VERSION ""

NS_ :

BS_:

BU_: IVI

BO_ 32 ACU_A102: 8 Vector__XXX
  SG_ AirbagCrashOrder_v3 : 5|6@0+ (1,0) [0|0] "" IVI

BO_ 116 ECM_A110: 8 Vector__XXX
  SG_ PowerTrainSetPoint : 11|10@0+ (0.125,0) [0|125] "%" IVI
  SG_ RawSensor : 17|10@0+ (0.125,0) [0|125] "%" IVI
  SG_ StopAutoPhase : 47|3@0+ (1,0) [0|0] "" IVI

BO_ 117 ECM_A112: 8 Vector__XXX
  SG_ PowerTrainStatus : 25|2@0+ (1,0) [0|0] "" IVI
  SG_ EngineRPM : 39|16@0+ (0.125,0) [0|8191.75] "rpm" IVI
  SG_ MeanEffectiveTorque : 55|12@0+ (0.5,-400) [-400|1647] "Nm" IVI

BO_ 168 STRG_A1: 7 Vector__XXX
  SG_ SteeringWheelAngleRaw : 22|15@0+ (0.1,-1080) [-1080|1080] "°" IVI
  SG_ SwaSensorInternalStatus : 39|3@0+ (1,0) [0|0] "" IVI
  SG_ SteeringWheelRotationSpeed : 47|16@0+ (0.1,-3276.7) [-3276.7|3276.7] "°/s" IVI

BO_ 171 VDC_A6: 8 Vector__XXX
  SG_ YawRateCorrected : 10|11@0+ (0.1,-100) [-100|100] "°/s" IVI
  SG_ BrakingPressure : 31|8@0+ (0.5,0) [0|126] "bar" IVI
  SG_ SteeringWheelAngleCorrected : 39|15@0+ (0.1,-1080) [-1080|1080] "°" IVI

BO_ 180 VDC_A5: 8 Vector__XXX
  SG_ LongitudinalAccelCorrected : 23|12@0+ (0.001,-2) [-2|2] "G" IVI
  SG_ TransversalAccelCorrected : 47|12@0+ (0.001,-2) [-2|2] "G" IVI

BO_ 286 ATCU_A107: 3 Vector__XXX
  SG_ TorqueConverterState : 22|2@0+ (1,0) [0|0] "" IVI

BO_ 303 ATCU_A108: 7 Vector__XXX
  SG_ GearLeverPosition_v2 : 20|4@0+ (1,0) [0|0] "" IVI

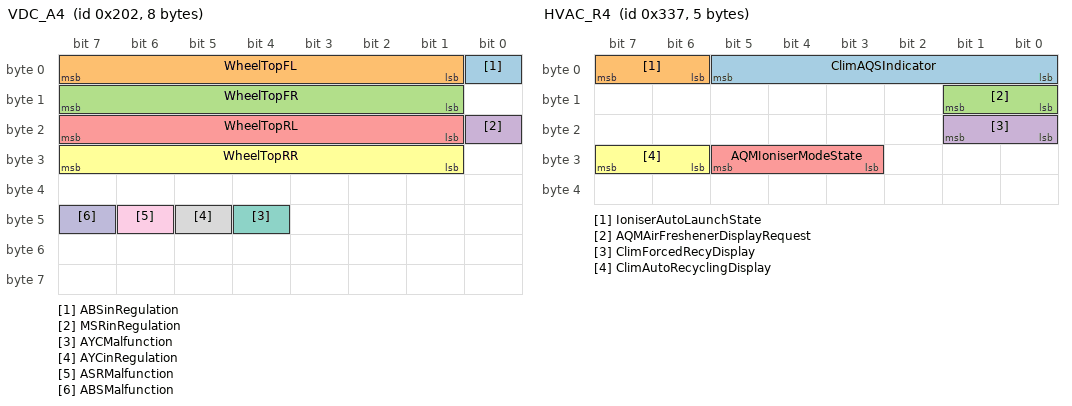
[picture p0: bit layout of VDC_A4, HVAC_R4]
BO_ 514 VDC_A4: 8 Vector__XXX
  SG_ ABSinRegulation : 0|1@0+ (1,0) [0|0] "" IVI
  SG_ WheelTopFL : 7|7@0+ (1,0) [0|96] "top" IVI
  SG_ WheelTopFR : 15|7@0+ (1,0) [0|96] "top" IVI
  SG_ MSRinRegulation : 16|1@0+ (1,0) [0|0] "" IVI
  SG_ WheelTopRL : 23|7@0+ (1,0) [0|96] "top" IVI
  SG_ WheelTopRR : 31|7@0+ (1,0) [0|96] "top" IVI
  SG_ AYCMalfunction : 44|1@0+ (1,0) [0|0] "" IVI
  SG_ AYCinRegulation : 45|1@0+ (1,0) [0|0] "" IVI
  SG_ ASRMalfunction : 46|1@0+ (1,0) [0|0] "" IVI
  SG_ ABSMalfunction : 47|1@0+ (1,0) [0|0] "" IVI

BO_ 534 EPS_A101: 4 Vector__XXX
  SG_ EPSWarning : 19|2@0+ (1,0) [0|0] "" IVI

BO_ 606 ADASISv2_A101: 8 IVI
  SG_ ADASISv2_ShortRang : 7|64@0+ (1,0) [0|0] "" Vector__XXX

BO_ 649 VDC_A3: 8 Vector__XXX
  SG_ WheelSpeedRL : 23|16@0+ (0.0416666667,0) [0|2730.583333] "rpm" IVI
  SG_ WheelSpeedRR : 39|16@0+ (0.0416666667,0) [0|2730.583333] "rpm" IVI
  SG_ VehicleSpeedBody : 55|16@0+ (0.01,0) [0|655.34] "km/h" IVI

BO_ 650 VDC_A9: 8 Vector__XXX
  SG_ WheelSpeedFR : 7|16@0+ (0.0416666667,0) [0|2730.583333] "rpm" IVI
  SG_ WheelSpeedFL : 23|16@0+ (0.0416666667,0) [0|2730.583333] "rpm" IVI
  SG_ VehicleSpeed : 39|16@0+ (0.01,0) [0|655.34] "km/h" IVI

BO_ 791 HVAC_A1: 8 Vector__XXX
  SG_ ISS_EcoActivationState : 43|2@0+ (1,0) [0|0] "" IVI
  SG_ AirCondEcoActivationState : 45|2@0+ (1,0) [0|0] "" IVI
  SG_ ClimECOModeStatusDisplay : 52|2@0+ (1,0) [0|0] "" IVI

BO_ 823 HVAC_R4: 5 Vector__XXX
  SG_ ClimAQSIndicator : 5|6@0+ (2,0) [0|100] "%" IVI
  SG_ IoniserAutoLaunchState : 7|2@0+ (1,0) [0|0] "" IVI
  SG_ AQMAirFreshenerDisplayRequest : 9|2@0+ (1,0) [0|0] "" IVI
  SG_ ClimForcedRecyDisplay : 17|2@0+ (1,0) [0|0] "" IVI
  SG_ AQMIoniserModeState : 29|3@0+ (1,0) [0|0] "" IVI
  SG_ ClimAutoRecyclingDisplay : 31|2@0+ (1,0) [0|0] "" IVI

BO_ 893 EPS_A103: 3 Vector__XXX
  SG_ LDW_VibrationIntensityState : 2|2@0+ (1,0) [0|0] "" IVI
  SG_ LCA_SteeringStatus2 : 7|2@0+ (1,0) [0|0] "" IVI

BO_ 928 ADASISv2_A102: 8 IVI
  SG_ ADASISv2_LongRang : 7|64@0+ (1,0) [0|0] "" Vector__XXX

BO_ 929 ADASISv2_A104: 8 IVI
  SG_ ADASISv2_SEGMENT : 7|64@0+ (1,0) [0|0] "" Vector__XXX

BO_ 931 ADASISv2_A105: 8 IVI
  SG_ ADASISv2_STUB : 7|64@0+ (1,0) [0|0] "" Vector__XXX

BO_ 934 AVM_A120: 3 Vector__XXX
  SG_ APA_StatusDisplay2 : 11|2@0+ (1,0) [0|0] "" IVI

BO_ 955 ECM_R102: 2 Vector__XXX
  SG_ RST_Boost_Duration_MMI : 7|8@0+ (1,0) [0|240] "s" IVI
  SG_ RST_Boost_Activation_MMI : 15|2@0+ (1,0) [0|0] "" IVI

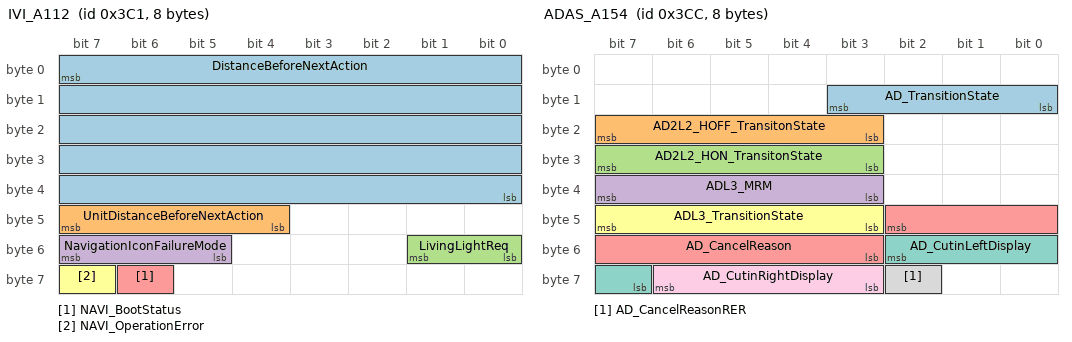
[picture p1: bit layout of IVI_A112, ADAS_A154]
BO_ 961 IVI_A112: 8 IVI
  SG_ DistanceBeforeNextAction : 7|40@0+ (1,0) [0|0] "" Vector__XXX
  SG_ UnitDistanceBeforeNextAction : 47|4@0+ (1,0) [0|0] "" Vector__XXX
  SG_ LivingLightReq : 49|2@0+ (1,0) [0|0] "" Vector__XXX
  SG_ NavigationIconFailureMode : 55|3@0+ (1,0) [0|0] "" Vector__XXX
  SG_ NAVI_BootStatus : 62|1@0+ (1,0) [0|0] "" Vector__XXX
  SG_ NAVI_OperationError : 63|1@0+ (1,0) [0|0] "" Vector__XXX

BO_ 962 SONAR_A118: 3 Vector__XXX
  SG_ APA_StatusDisplay : 11|2@0+ (1,0) [0|0] "" IVI

BO_ 967 IVI_A5: 8 IVI
  SG_ CDisplayAvailability : 1|2@0+ (1,0) [0|0] "" Vector__XXX
  SG_ AutoACC2_ON_Request_MM : 3|2@0+ (1,0) [0|0] "" Vector__XXX
  SG_ Audio_WorkingAuthorize : 5|2@0+ (1,0) [0|0] "" Vector__XXX
  SG_ IVI_RefusetoSleep : 7|2@0+ (1,0) [0|0] "" Vector__XXX
  SG_ SonarSystemPauseRequest2 : 8|1@0+ (1,0) [0|0] "" Vector__XXX
  SG_ IVI_InitializationState : 9|1@0+ (1,0) [0|0] "" Vector__XXX
  SG_ MMCustomerAction : 12|3@0+ (1,0) [0|6] "" Vector__XXX
  SG_ UserFeedbackAvailability : 13|1@0+ (1,0) [0|0] "" Vector__XXX
  SG_ AudioAvailability : 14|1@0+ (1,0) [0|0] "" Vector__XXX
  SG_ SwitchRequest_AVM : 16|1@0+ (1,0) [0|0] "" Vector__XXX
  SG_ ChangeViewRequest_AVM : 18|2@0+ (1,0) [0|0] "" Vector__XXX
  SG_ Audio_ProcessingDeactivation : 24|1@0+ (1,0) [0|0] "" Vector__XXX
  SG_ VehicleGPSreliability : 31|7@0+ (1,0) [0|127] "" Vector__XXX
  SG_ PassengerHeatingRequest : 33|2@0+ (1,0) [0|0] "" Vector__XXX
  SG_ PassengerVentilRequest : 35|2@0+ (1,0) [0|0] "" Vector__XXX
  SG_ DriverHeatingRequest : 37|2@0+ (1,0) [0|0] "" Vector__XXX
  SG_ DriverVentilRequest : 39|2@0+ (1,0) [0|0] "" Vector__XXX
  SG_ StorageFormatRequest : 42|2@0+ (1,0) [0|0] "" Vector__XXX
  SG_ TPMS_ResetDriverRequest2 : 44|2@0+ (1,0) [0|0] "" Vector__XXX
  SG_ TPW_ResetDriverRequest2 : 47|2@0+ (1,0) [0|0] "" Vector__XXX
  SG_ SatelliteGPSNumber : 55|7@0+ (1,0) [0|126] "wu" Vector__XXX
  SG_ EcoPedalForceSettingRequest : 58|2@0+ (1,0) [0|0] "" Vector__XXX
  SG_ HUD_UpDownRequest2 : 60|2@0+ (1,0) [0|0] "" Vector__XXX
  SG_ IVI_ParkAssistVolumeState : 63|3@0+ (1,0) [0|0] "" Vector__XXX

BO_ 969 HEVC_M101: 1 Vector__XXX
  SG_ TorqueDistributionRatioDisplay : 7|8@0+ (0.5,0) [0|100] "%" IVI

BO_ 970 BLM_A101: 1 Vector__XXX
  SG_ VirtualKeyActivationState : 3|1@0+ (1,0) [0|0] "" IVI
  SG_ VirtualKeyState : 4|1@0+ (1,0) [0|0] "" IVI

BO_ 972 ADAS_A154: 8 Vector__XXX
  SG_ AD_TransitionState : 11|4@0+ (1,0) [0|0] "" IVI
  SG_ AD2L2_HOFF_TransitonState : 23|5@0+ (1,0) [0|0] "" IVI
  SG_ AD2L2_HON_TransitonState : 31|5@0+ (1,0) [0|0] "" IVI
  SG_ ADL3_MRM : 39|5@0+ (1,0) [0|0] "" IVI
  SG_ AD_CancelReason : 42|8@0+ (1,0) [0|255] "CancelReason" IVI
  SG_ ADL3_TransitionState : 47|5@0+ (1,0) [0|0] "" IVI
  SG_ AD_CutinLeftDisplay : 50|4@0+ (1,0) [0|0] "" IVI
  SG_ AD_CancelReasonRER : 58|1@0+ (1,0) [0|0] "" IVI
  SG_ AD_CutinRightDisplay : 62|4@0+ (1,0) [0|0] "" IVI

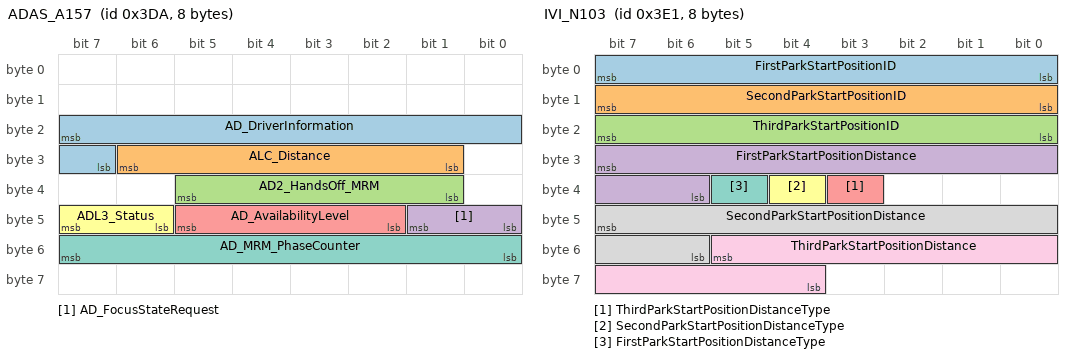
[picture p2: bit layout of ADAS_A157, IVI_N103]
BO_ 986 ADAS_A157: 8 Vector__XXX
  SG_ AD_DriverInformation : 23|9@0+ (1,0) [0|511] "Instruction" IVI
  SG_ ALC_Distance : 30|6@0+ (100,100) [100|6000] "m" IVI
  SG_ AD2_HandsOff_MRM : 37|5@0+ (1,0) [0|0] "" IVI
  SG_ AD_FocusStateRequest : 41|2@0+ (1,0) [0|0] "" IVI
  SG_ AD_AvailabilityLevel : 45|4@0+ (1,0) [0|0] "" IVI
  SG_ ADL3_Status : 47|2@0+ (1,0) [0|0] "" IVI
  SG_ AD_MRM_PhaseCounter : 55|8@0+ (0.2,-0.2) [0|50.6] "s" IVI

BO_ 993 IVI_N103: 8 IVI
  SG_ FirstParkStartPositionID : 7|8@0+ (1,0) [0|255] "-" Vector__XXX
  SG_ SecondParkStartPositionID : 15|8@0+ (1,0) [0|255] "-" Vector__XXX
  SG_ ThirdParkStartPositionID : 23|8@0+ (1,0) [0|255] "-" Vector__XXX
  SG_ FirstParkStartPositionDistance : 31|10@0+ (1,0) [0|1023] "m" Vector__XXX
  SG_ ThirdParkStartPositionDistanceType : 35|1@0+ (1,0) [0|0] "-" Vector__XXX
  SG_ SecondParkStartPositionDistanceType : 36|1@0+ (1,0) [0|0] "-" Vector__XXX
  SG_ FirstParkStartPositionDistanceType : 37|1@0+ (1,0) [0|0] "-" Vector__XXX
  SG_ SecondParkStartPositionDistance : 47|10@0+ (1,0) [0|1023] "m" Vector__XXX
  SG_ ThirdParkStartPositionDistance : 53|10@0+ (1,0) [0|1023] "m" Vector__XXX

BO_ 994 FWS_A102: 1 Vector__XXX
  SG_ a4WS_AnglePosition_v2 : 7|7@0+ (0.1,-5) [-5|5] "deg" IVI

BO_ 996 DSMU_A101: 3 Vector__XXX
  SG_ DriverMassageProgramState_v2 : 23|3@0+ (1,0) [0|0] "" IVI

BO_ 1000 HFM_A101: 4 Vector__XXX
  SG_ APPRUN_ActivationState : 12|1@0+ (1,0) [0|0] "" IVI
  SG_ WAL_ActivationState : 13|1@0+ (1,0) [0|0] "" IVI
  SG_ IKeyAccessActivationState : 18|1@0+ (1,0) [0|0] "" IVI

BO_ 1001 PSCU_A102: 1 Vector__XXX
  SG_ PassengerMassageProgramState_v2 : 6|3@0+ (1,0) [0|0] "" IVI

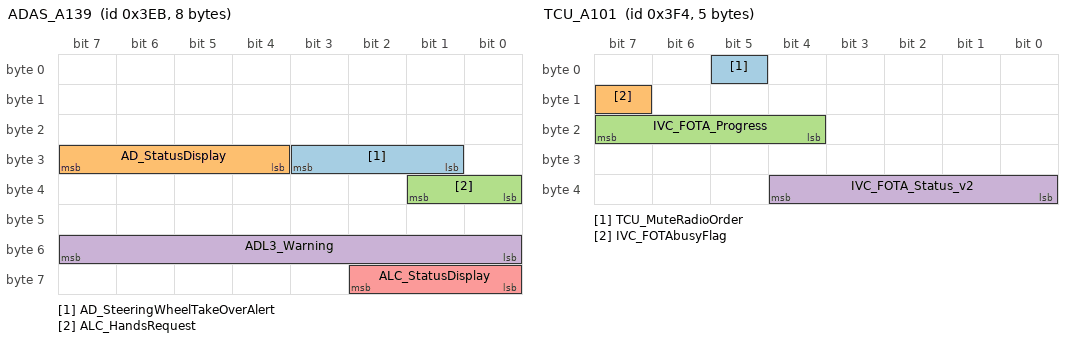
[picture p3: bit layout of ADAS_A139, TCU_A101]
BO_ 1003 ADAS_A139: 8 Vector__XXX
  SG_ AD_SteeringWheelTakeOverAlert : 27|3@0+ (1,0) [0|0] "" IVI
  SG_ AD_StatusDisplay : 31|4@0+ (1,0) [0|0] "" IVI
  SG_ ALC_HandsRequest : 33|2@0+ (1,0) [0|0] "" IVI
  SG_ ADL3_Warning : 55|8@0+ (1,0) [0|255] "Warning" IVI
  SG_ ALC_StatusDisplay : 58|3@0+ (1,0) [0|0] "" IVI

BO_ 1012 TCU_A101: 5 Vector__XXX
  SG_ TCU_MuteRadioOrder : 5|1@0+ (1,0) [0|0] "" IVI
  SG_ IVC_FOTAbusyFlag : 15|1@0+ (1,0) [0|0] "" IVI
  SG_ IVC_FOTA_Progress : 23|4@0+ (10,0) [0|100] "%" IVI
  SG_ IVC_FOTA_Status_v2 : 36|5@0+ (1,0) [0|0] "" IVI

BO_ 1017 UTA_R1: 2 Vector__XXX
  SG_ UTA_VigilanceLevelDisplay : 5|4@0+ (1,0) [0|0] "" IVI
  SG_ UTA_AlertActivationState : 6|1@0+ (1,0) [0|0] "" IVI
  SG_ UTA_VigilanceAlertDisplay_v2 : 15|2@0+ (1,0) [0|0] "" IVI

BO_ 1028 VSP_A101: 1 Vector__XXX
  SG_ VSPSoundActivationState : 4|1@0+ (1,0) [0|0] "" IVI
  SG_ VSPsoundChoiceActivationState : 7|3@0+ (1,0) [0|0] "" IVI

BO_ 1047 AVM_A119: 3 Vector__XXX
  SG_ AVM_WarningDisplayRequest : 7|3@0+ (1,0) [0|0] "" IVI
  SG_ HFP_ManeuverCompletion2 : 15|7@0+ (1,0) [0|100] "%" IVI
  SG_ HFP_ExtendedInstrContentDisplay2 : 23|5@0+ (1,0) [0|0] "" IVI

BO_ 1058 FRCAMERA_A111: 5 Vector__XXX
  SG_ OSPSpeedUnit : 19|2@0+ (1,0) [0|0] "" IVI
  SG_ TSR_ConfidenceLevel : 39|3@0+ (20,0) [0|100] "%" IVI

BO_ 1064 HEVC_A104: 7 Vector__XXX
  SG_ EcoNavFuelSaving : 0|10@0+ (0.01,0) [0|10] "L" IVI
  SG_ VehicleAutonomyZEV : 22|10@0+ (1,0) [0|1022] "km" IVI

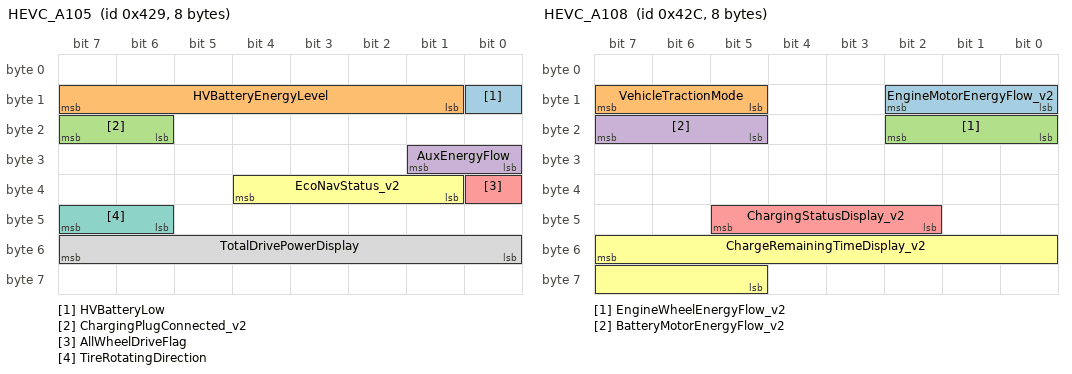
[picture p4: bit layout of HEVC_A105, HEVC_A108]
BO_ 1065 HEVC_A105: 8 Vector__XXX
  SG_ HVBatteryLow : 8|1@0+ (1,0) [0|0] "" IVI
  SG_ HVBatteryEnergyLevel : 15|7@0+ (1,0) [0|100] "%" IVI
  SG_ ChargingPlugConnected_v2 : 23|2@0+ (1,0) [0|0] "" IVI
  SG_ AuxEnergyFlow : 25|2@0+ (1,0) [0|0] "" IVI
  SG_ AllWheelDriveFlag : 32|1@0+ (1,0) [0|0] "" IVI
  SG_ EcoNavStatus_v2 : 36|4@0+ (1,0) [0|0] "" IVI
  SG_ TireRotatingDirection : 47|2@0+ (1,0) [0|0] "" IVI
  SG_ TotalDrivePowerDisplay : 55|8@0+ (1,-100) [-100|120] "%" IVI

BO_ 1066 HEVC_A106: 8 Vector__XXX
  SG_ HVbatteryChargeType_v2 : 50|3@0+ (1,0) [0|0] "" IVI

BO_ 1068 HEVC_A108: 8 Vector__XXX
  SG_ EngineMotorEnergyFlow_v2 : 10|3@0+ (1,0) [0|0] "" IVI
  SG_ VehicleTractionMode : 15|3@0+ (1,0) [0|0] "" IVI
  SG_ EngineWheelEnergyFlow_v2 : 18|3@0+ (1,0) [0|0] "" IVI
  SG_ BatteryMotorEnergyFlow_v2 : 23|3@0+ (1,0) [0|0] "" IVI
  SG_ ChargingStatusDisplay_v2 : 45|4@0+ (1,0) [0|0] "" IVI
  SG_ ChargeRemainingTimeDisplay_v2 : 55|11@0+ (1,0) [0|2046] "min" IVI

BO_ 1070 HEVC_R101: 7 Vector__XXX
  SG_ UserSOC : 7|8@0+ (0.392157,0) [0|100] "%" IVI

BO_ 1071 HEVC_R103: 3 Vector__XXX
  SG_ HVBatteryEnergyCap_Reachability : 7|11@0+ (0.05,0) [0|100] "kWh" IVI
  SG_ AvailableEnergy_HEVC : 12|11@0+ (0.05,0) [0|100] "kWh" IVI

BO_ 1076 HFM_A104: 8 Vector__XXX
  SG_ WAC_APRUN_ActivationState : 49|1@0+ (1,0) [0|0] "" IVI
  SG_ SwitchOffSESDisturbers : 50|1@0+ (1,0) [0|0] "" IVI

BO_ 1081 VDC_A114: 6 Vector__XXX
  SG_ SlopeEstimation : 7|8@0+ (0.2,-15) [-15|15] "°" IVI
  SG_ DistanceTotalizer : 15|28@0+ (0.01,0) [0|2600000] "km" IVI
  SG_ TCS_DeactivationState : 32|1@0+ (1,0) [0|0] "" IVI

BO_ 1086 HVAC_A2: 8 Vector__XXX
  SG_ InputPower_AC_INV : 15|7@0+ (50,0) [0|5100] "W" IVI
  SG_ ePTCpower : 23|6@0+ (250,0) [0|10000] "W" IVI

BO_ 1099 ATCU_A109: 8 Vector__XXX
  SG_ ATCVT_RangeIndicationExtended : 44|6@0+ (1,0) [0|0] "" IVI

BO_ 1100 ATCU_A110: 6 Vector__XXX
  SG_ RST_LaunchControlReady : 11|2@0+ (1,0) [0|0] "" IVI

BO_ 1101 BCM_A107: 4 Vector__XXX
  SG_ FlashingIndicatorStatusDisplay : 23|3@0+ (1,0) [0|0] "" IVI

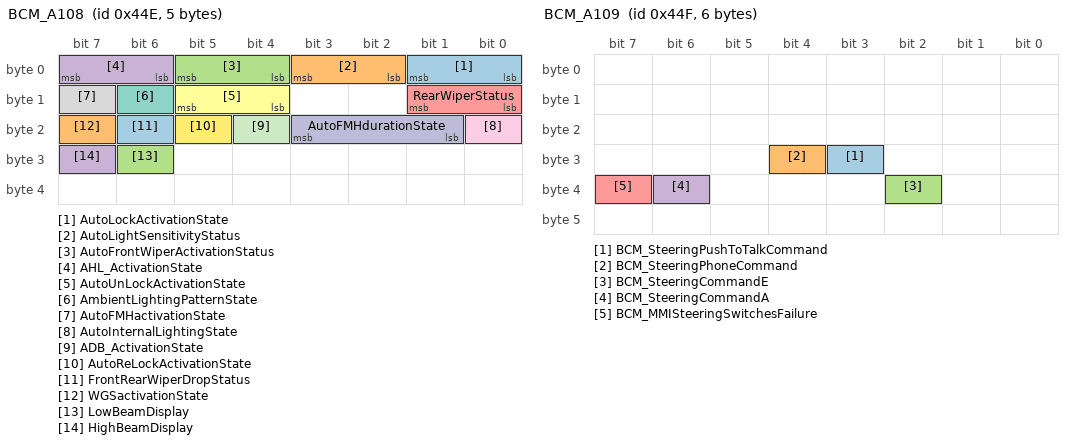
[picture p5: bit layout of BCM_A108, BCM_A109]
BO_ 1102 BCM_A108: 5 Vector__XXX
  SG_ AutoLockActivationState : 1|2@0+ (1,0) [0|0] "" IVI
  SG_ AutoLightSensitivityStatus : 3|2@0+ (1,0) [0|0] "" IVI
  SG_ AutoFrontWiperActivationStatus : 5|2@0+ (1,0) [0|0] "" IVI
  SG_ AHL_ActivationState : 7|2@0+ (1,0) [0|0] "" IVI
  SG_ RearWiperStatus : 9|2@0+ (1,0) [0|0] "" IVI
  SG_ AutoUnLockActivationState : 13|2@0+ (1,0) [0|0] "" IVI
  SG_ AmbientLightingPatternState : 14|1@0+ (1,0) [0|0] "" IVI
  SG_ AutoFMHactivationState : 15|1@0+ (1,0) [0|0] "" IVI
  SG_ AutoInternalLightingState : 16|1@0+ (1,0) [0|0] "" IVI
  SG_ AutoFMHdurationState : 19|3@0+ (1,0) [0|0] "" IVI
  SG_ ADB_ActivationState : 20|1@0+ (1,0) [0|0] "" IVI
  SG_ AutoReLockActivationState : 21|1@0+ (1,0) [0|0] "" IVI
  SG_ FrontRearWiperDropStatus : 22|1@0+ (1,0) [0|0] "" IVI
  SG_ WGSactivationState : 23|1@0+ (1,0) [0|0] "" IVI
  SG_ LowBeamDisplay : 30|1@0+ (1,0) [0|0] "" IVI
  SG_ HighBeamDisplay : 31|1@0+ (1,0) [0|0] "" IVI

BO_ 1103 BCM_A109: 6 Vector__XXX
  SG_ BCM_SteeringPushToTalkCommand : 27|1@0+ (1,0) [0|0] "" IVI
  SG_ BCM_SteeringPhoneCommand : 28|1@0+ (1,0) [0|0] "" IVI
  SG_ BCM_SteeringCommandE : 34|1@0+ (1,0) [0|0] "" IVI
  SG_ BCM_SteeringCommandA : 38|1@0+ (1,0) [0|0] "" IVI
  SG_ BCM_MMISteeringSwitchesFailure : 39|1@0+ (1,0) [0|0] "" IVI

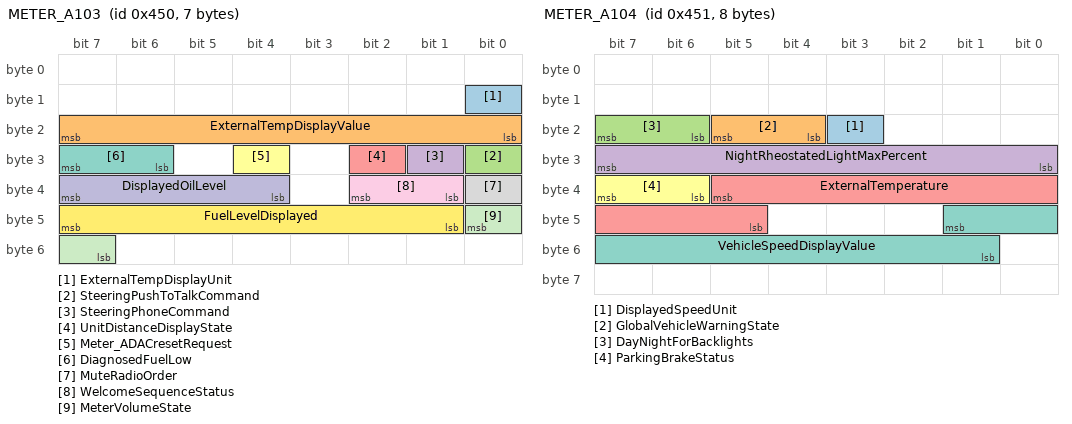
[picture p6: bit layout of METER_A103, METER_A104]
BO_ 1104 METER_A103: 7 Vector__XXX
  SG_ ExternalTempDisplayUnit : 8|1@0+ (1,0) [0|0] "" IVI
  SG_ ExternalTempDisplayValue : 23|8@0+ (1,-40) [-40|140] "" IVI
  SG_ SteeringPushToTalkCommand : 24|1@0+ (1,0) [0|0] "" IVI
  SG_ SteeringPhoneCommand : 25|1@0+ (1,0) [0|0] "" IVI
  SG_ UnitDistanceDisplayState : 26|1@0+ (1,0) [0|0] "" IVI
  SG_ Meter_ADACresetRequest : 28|1@0+ (1,0) [0|0] "" IVI
  SG_ DiagnosedFuelLow : 31|2@0+ (1,0) [0|0] "" IVI
  SG_ MuteRadioOrder : 32|1@0+ (1,0) [0|0] "" IVI
  SG_ WelcomeSequenceStatus : 34|2@0+ (1,0) [0|0] "" IVI
  SG_ DisplayedOilLevel : 39|4@0+ (1,0) [0|0] "" IVI
  SG_ MeterVolumeState : 40|2@0+ (1,0) [0|0] "" IVI
  SG_ FuelLevelDisplayed : 47|7@0+ (1,0) [0|80] "L" IVI

BO_ 1105 METER_A104: 8 Vector__XXX
  SG_ DisplayedSpeedUnit : 19|1@0+ (1,0) [0|0] "" IVI
  SG_ GlobalVehicleWarningState : 21|2@0+ (1,0) [0|0] "" IVI
  SG_ DayNightForBacklights : 23|2@0+ (1,0) [0|0] "" IVI
  SG_ NightRheostatedLightMaxPercent : 31|8@0+ (0.4,0) [0|100] "%" IVI
  SG_ ExternalTemperature : 37|9@0+ (0.25,-50) [-50|70] "°C" IVI
  SG_ ParkingBrakeStatus : 39|2@0+ (1,0) [0|0] "" IVI
  SG_ VehicleSpeedDisplayValue : 41|9@0+ (1,0) [0|510] "" IVI

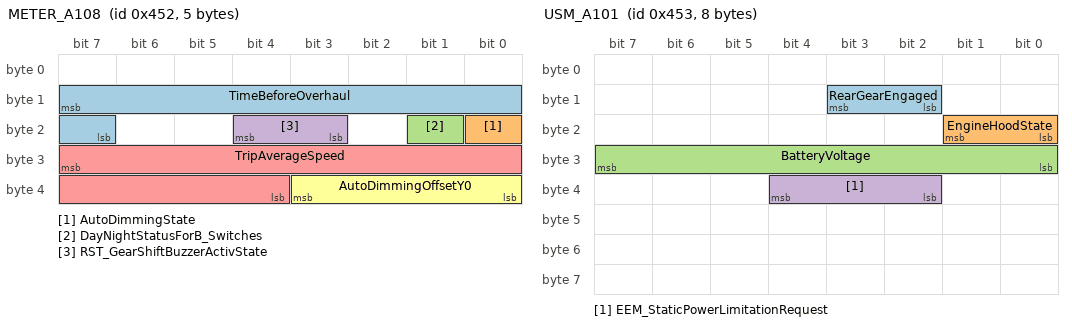
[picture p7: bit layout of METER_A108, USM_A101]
BO_ 1106 METER_A108: 5 Vector__XXX
  SG_ TimeBeforeOverhaul : 15|9@0+ (1,0) [0|511] "day" IVI
  SG_ AutoDimmingState : 16|1@0+ (1,0) [0|0] "" IVI
  SG_ DayNightStatusForB_Switches : 17|1@0+ (1,0) [0|0] "" IVI
  SG_ RST_GearShiftBuzzerActivState : 20|2@0+ (1,0) [0|0] "" IVI
  SG_ TripAverageSpeed : 31|12@0+ (0.1,0) [0|409.5] "" IVI
  SG_ AutoDimmingOffsetY0 : 35|4@0+ (1,0) [0|0] "" IVI

BO_ 1107 USM_A101: 8 Vector__XXX
  SG_ RearGearEngaged : 11|2@0+ (1,0) [0|0] "" IVI
  SG_ EngineHoodState : 17|2@0+ (1,0) [0|0] "" IVI
  SG_ BatteryVoltage : 31|8@0+ (0.06,6) [6|18] "V" IVI
  SG_ EEM_StaticPowerLimitationRequest : 36|3@0+ (1,0) [0|0] "" IVI

BO_ 1108 USM_A103: 8 Vector__XXX
  SG_ HandDrivingActivationState : 0|1@0+ (1,0) [0|0] "" IVI
  SG_ LowBatteryVoltageDisplay : 15|2@0+ (1,0) [0|0] "" IVI
  SG_ AFS_ActivationState : 16|1@0+ (1,0) [0|0] "" IVI

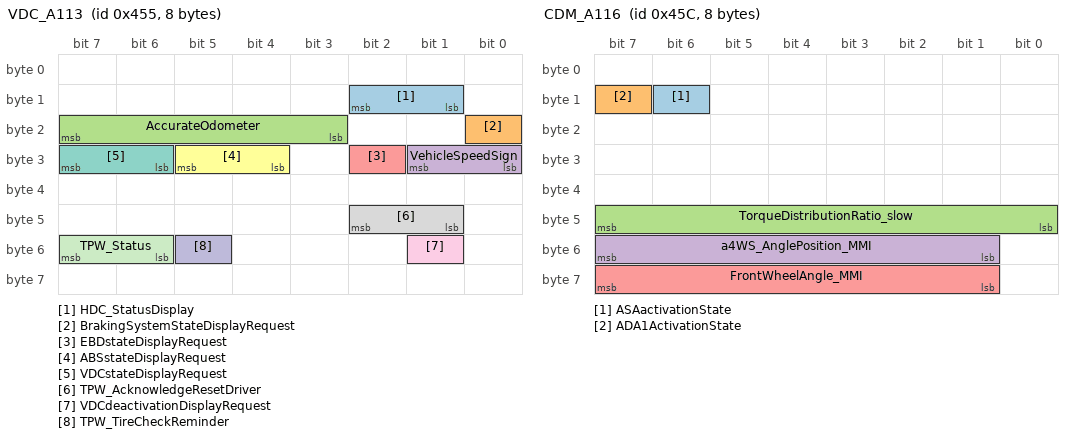
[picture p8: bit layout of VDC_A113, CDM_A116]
BO_ 1109 VDC_A113: 8 Vector__XXX
  SG_ HDC_StatusDisplay : 10|2@0+ (1,0) [0|0] "" IVI
  SG_ BrakingSystemStateDisplayRequest : 16|1@0+ (1,0) [0|0] "" IVI
  SG_ AccurateOdometer : 23|5@0+ (4,0) [0|120] "cm" IVI
  SG_ VehicleSpeedSign : 25|2@0+ (1,0) [0|0] "" IVI
  SG_ EBDstateDisplayRequest : 26|1@0+ (1,0) [0|0] "" IVI
  SG_ ABSstateDisplayRequest : 29|2@0+ (1,0) [0|0] "" IVI
  SG_ VDCstateDisplayRequest : 31|2@0+ (1,0) [0|0] "" IVI
  SG_ TPW_AcknowledgeResetDriver : 42|2@0+ (1,0) [0|0] "" IVI
  SG_ VDCdeactivationDisplayRequest : 49|1@0+ (1,0) [0|0] "" IVI
  SG_ TPW_TireCheckReminder : 53|1@0+ (1,0) [0|0] "" IVI
  SG_ TPW_Status : 55|2@0+ (1,0) [0|0] "" IVI

BO_ 1116 CDM_A116: 8 Vector__XXX
  SG_ ASAactivationState : 14|1@0+ (1,0) [0|0] "" IVI
  SG_ ADA1ActivationState : 15|1@0+ (1,0) [0|0] "" IVI
  SG_ TorqueDistributionRatio_slow : 47|8@0+ (0.5,0) [0|100] "%" IVI
  SG_ a4WS_AnglePosition_MMI : 55|7@0+ (0.1,-5) [-5|5] "deg" IVI
  SG_ FrontWheelAngle_MMI : 63|7@0+ (1,-50) [-50|50] "°" IVI

BO_ 1119 ECM_A108: 4 Vector__XXX
  SG_ EngineCoolantTemp : 23|8@0+ (1,-40) [-40|214] "°C" IVI

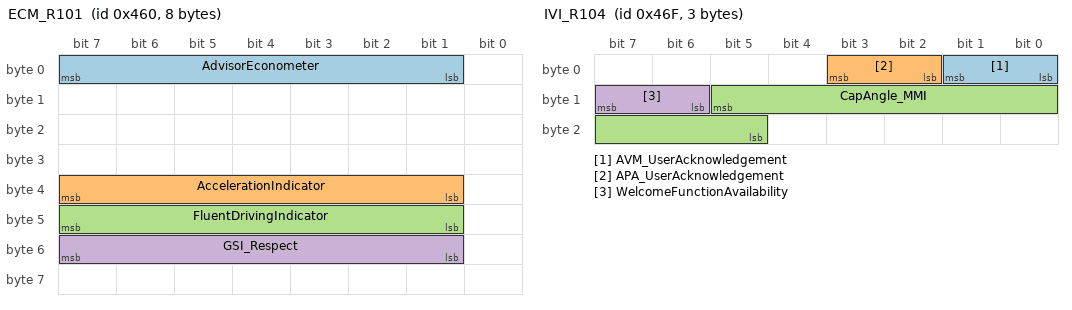
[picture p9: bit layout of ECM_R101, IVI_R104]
BO_ 1120 ECM_R101: 8 Vector__XXX
  SG_ AdvisorEconometer : 7|7@0+ (1,0) [0|127] "%" IVI
  SG_ AccelerationIndicator : 39|7@0+ (1,0) [0|127] "%" IVI
  SG_ FluentDrivingIndicator : 47|7@0+ (1,0) [0|127] "%" IVI
  SG_ GSI_Respect : 55|7@0+ (1,0) [0|127] "%" IVI

BO_ 1135 IVI_R104: 3 IVI
  SG_ AVM_UserAcknowledgement : 1|2@0+ (1,0) [0|0] "" Vector__XXX
  SG_ APA_UserAcknowledgement : 3|2@0+ (1,0) [0|0] "" Vector__XXX
  SG_ CapAngle_MMI : 13|9@0+ (1,0) [0|360] "°" Vector__XXX
  SG_ WelcomeFunctionAvailability : 15|2@0+ (1,0) [0|0] "" Vector__XXX

BO_ 1136 ECM_A107: 7 Vector__XXX
  SG_ EngineControlFailureLevel2 : 11|1@0+ (1,0) [0|0] "" IVI
  SG_ EngineControlFailureLevel1 : 32|1@0+ (1,0) [0|0] "" IVI

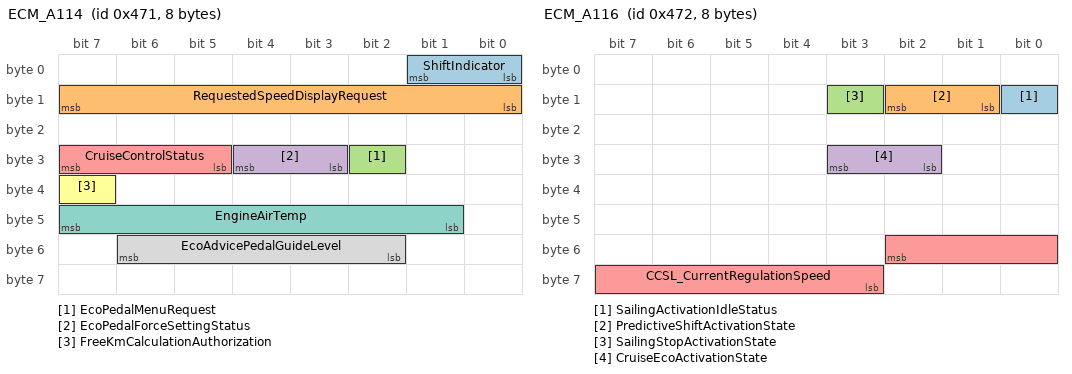
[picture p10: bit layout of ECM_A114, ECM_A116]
BO_ 1137 ECM_A114: 8 Vector__XXX
  SG_ ShiftIndicator : 1|2@0+ (1,0) [0|0] "" IVI
  SG_ RequestedSpeedDisplayRequest : 15|8@0+ (1,0) [0|253] "" IVI
  SG_ EcoPedalMenuRequest : 26|1@0+ (1,0) [0|0] "" IVI
  SG_ EcoPedalForceSettingStatus : 28|2@0+ (1,0) [0|0] "" IVI
  SG_ CruiseControlStatus : 31|3@0+ (1,0) [0|0] "" IVI
  SG_ FreeKmCalculationAuthorization : 39|1@0+ (1,0) [0|0] "" IVI
  SG_ EngineAirTemp : 47|7@0+ (1,-40) [-40|86] "°C" IVI
  SG_ EcoAdvicePedalGuideLevel : 54|5@0+ (1,0) [0|30] "wu" IVI

BO_ 1138 ECM_A116: 8 Vector__XXX
  SG_ SailingActivationIdleStatus : 8|1@0+ (1,0) [0|0] "" IVI
  SG_ PredictiveShiftActivationState : 10|2@0+ (1,0) [0|0] "" IVI
  SG_ SailingStopActivationState : 11|1@0+ (1,0) [0|0] "" IVI
  SG_ CruiseEcoActivationState : 27|2@0+ (1,0) [0|0] "" IVI
  SG_ CCSL_CurrentRegulationSpeed : 50|8@0+ (1,0) [0|200] "Cluster speed unit" IVI

BO_ 1140 ADAS_A116: 8 Vector__XXX
  SG_ LKA_AlertStatus : 9|2@0+ (1,0) [0|0] "" IVI
  SG_ LKA_ActivationState : 20|2@0+ (1,0) [0|0] "" IVI
  SG_ LKA_SWheelTakeOverAlert_v3 : 23|3@0+ (1,0) [0|0] "" IVI

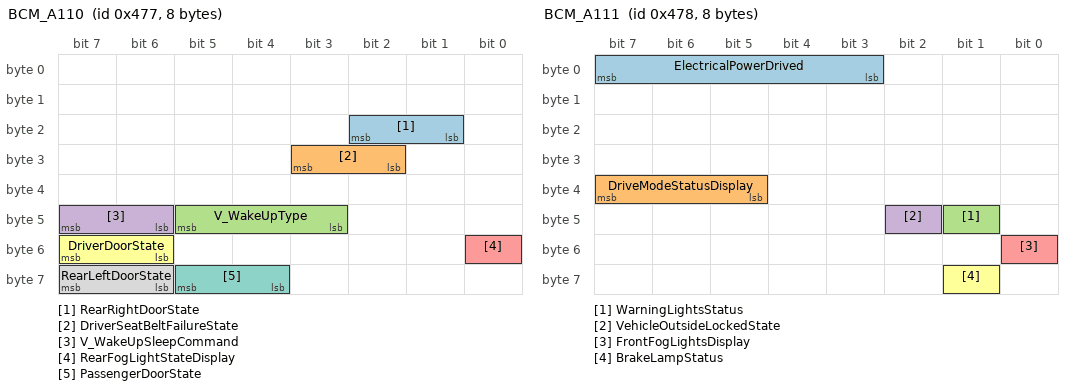
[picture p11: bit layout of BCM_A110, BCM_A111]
BO_ 1143 BCM_A110: 8 Vector__XXX
  SG_ RearRightDoorState : 18|2@0+ (1,0) [0|0] "" IVI
  SG_ DriverSeatBeltFailureState : 27|2@0+ (1,0) [0|0] "" IVI
  SG_ V_WakeUpType : 45|3@0+ (1,0) [0|0] "" IVI
  SG_ V_WakeUpSleepCommand : 47|2@0+ (1,0) [0|0] "" IVI
  SG_ RearFogLightStateDisplay : 48|1@0+ (1,0) [0|0] "" IVI
  SG_ DriverDoorState : 55|2@0+ (1,0) [0|0] "" IVI
  SG_ PassengerDoorState : 61|2@0+ (1,0) [0|0] "" IVI
  SG_ RearLeftDoorState : 63|2@0+ (1,0) [0|0] "" IVI

BO_ 1144 BCM_A111: 8 Vector__XXX
  SG_ ElectricalPowerDrived : 7|5@0+ (100,0) [0|3000] "W" IVI
  SG_ DriveModeStatusDisplay : 39|3@0+ (1,0) [0|0] "" IVI
  SG_ WarningLightsStatus : 41|1@0+ (1,0) [0|0] "" IVI
  SG_ VehicleOutsideLockedState : 42|1@0+ (1,0) [0|0] "" IVI
  SG_ FrontFogLightsDisplay : 48|1@0+ (1,0) [0|0] "" IVI
  SG_ BrakeLampStatus : 57|1@0+ (1,0) [0|0] "" IVI

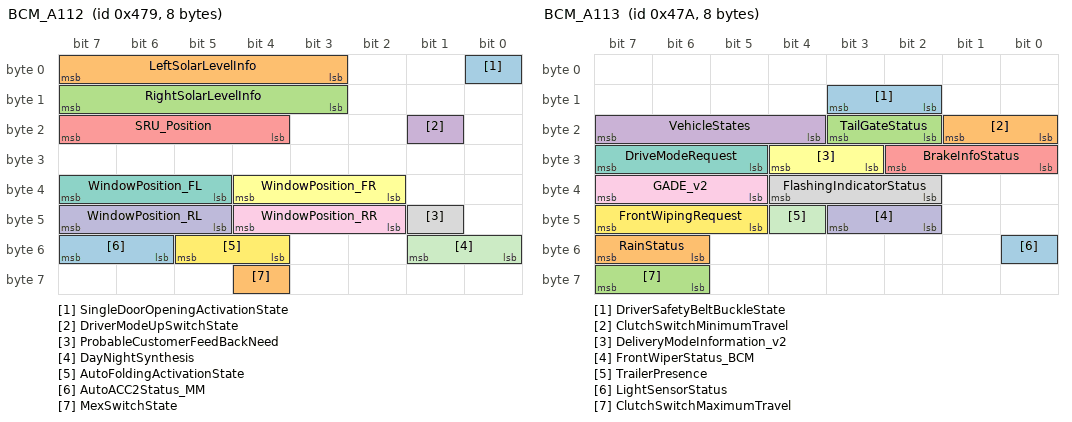
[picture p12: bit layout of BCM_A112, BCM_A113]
BO_ 1145 BCM_A112: 8 Vector__XXX
  SG_ SingleDoorOpeningActivationState : 0|1@0+ (1,0) [0|0] "" IVI
  SG_ LeftSolarLevelInfo : 7|5@0+ (50,0) [0|1500] "W" IVI
  SG_ RightSolarLevelInfo : 15|5@0+ (50,0) [0|1500] "W" IVI
  SG_ DriverModeUpSwitchState : 17|1@0+ (1,0) [0|0] "" IVI
  SG_ SRU_Position : 23|4@0+ (1,0) [0|0] "" IVI
  SG_ WindowPosition_FR : 36|3@0+ (1,0) [0|0] "" IVI
  SG_ WindowPosition_FL : 39|3@0+ (1,0) [0|0] "" IVI
  SG_ ProbableCustomerFeedBackNeed : 41|1@0+ (1,0) [0|0] "" IVI
  SG_ WindowPosition_RR : 44|3@0+ (1,0) [0|0] "" IVI
  SG_ WindowPosition_RL : 47|3@0+ (1,0) [0|0] "" IVI
  SG_ DayNightSynthesis : 49|2@0+ (1,0) [0|0] "" IVI
  SG_ AutoFoldingActivationState : 53|2@0+ (1,0) [0|0] "" IVI
  SG_ AutoACC2Status_MM : 55|2@0+ (1,0) [0|0] "" IVI
  SG_ MexSwitchState : 60|1@0+ (1,0) [0|0] "" IVI

BO_ 1146 BCM_A113: 8 Vector__XXX
  SG_ DriverSafetyBeltBuckleState : 11|2@0+ (1,0) [0|0] "" IVI
  SG_ ClutchSwitchMinimumTravel : 17|2@0+ (1,0) [0|0] "" IVI
  SG_ TailGateStatus : 19|2@0+ (1,0) [0|0] "" IVI
  SG_ VehicleStates : 23|4@0+ (1,0) [0|0] "" IVI
  SG_ BrakeInfoStatus : 26|3@0+ (1,0) [0|0] "" IVI
  SG_ DeliveryModeInformation_v2 : 28|2@0+ (1,0) [0|0] "" IVI
  SG_ DriveModeRequest : 31|3@0+ (1,0) [0|0] "" IVI
  SG_ FlashingIndicatorStatus : 36|3@0+ (1,0) [0|0] "" IVI
  SG_ GADE_v2 : 39|3@0+ (1,0) [0|0] "" IVI
  SG_ FrontWiperStatus_BCM : 43|2@0+ (1,0) [0|0] "" IVI
  SG_ TrailerPresence : 44|1@0+ (1,0) [0|0] "" IVI
  SG_ FrontWipingRequest : 47|3@0+ (1,0) [0|0] "" IVI
  SG_ LightSensorStatus : 48|1@0+ (1,0) [0|0] "" IVI
  SG_ RainStatus : 55|2@0+ (1,0) [0|0] "" IVI
  SG_ ClutchSwitchMaximumTravel : 63|2@0+ (1,0) [0|0] "" IVI

BO_ 1147 ECM_A105: 7 Vector__XXX
  SG_ OilPressureWarning_ECM : 17|1@0+ (1,0) [0|0] "" IVI
  SG_ WarningWaterTemp : 18|1@0+ (1,0) [0|0] "" IVI
  SG_ FuelConsumption : 31|8@0+ (80,0) [0|20400] "mm3" IVI

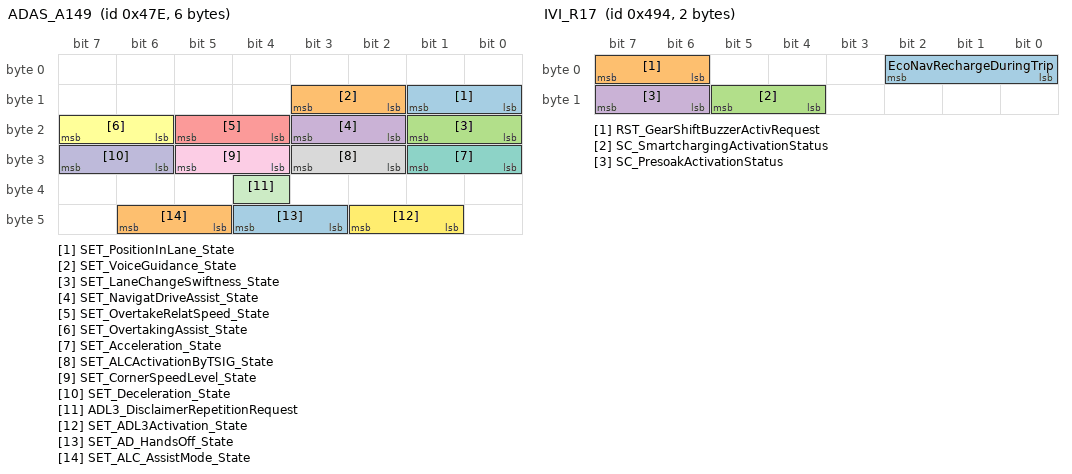
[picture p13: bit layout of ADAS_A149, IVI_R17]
BO_ 1150 ADAS_A149: 6 Vector__XXX
  SG_ SET_PositionInLane_State : 9|2@0+ (1,0) [0|0] "" IVI
  SG_ SET_VoiceGuidance_State : 11|2@0+ (1,0) [0|0] "" IVI
  SG_ SET_LaneChangeSwiftness_State : 17|2@0+ (1,0) [0|0] "" IVI
  SG_ SET_NavigatDriveAssist_State : 19|2@0+ (1,0) [0|0] "" IVI
  SG_ SET_OvertakeRelatSpeed_State : 21|2@0+ (1,0) [0|0] "" IVI
  SG_ SET_OvertakingAssist_State : 23|2@0+ (1,0) [0|0] "" IVI
  SG_ SET_Acceleration_State : 25|2@0+ (1,0) [0|0] "" IVI
  SG_ SET_ALCActivationByTSIG_State : 27|2@0+ (1,0) [0|0] "" IVI
  SG_ SET_CornerSpeedLevel_State : 29|2@0+ (1,0) [0|0] "" IVI
  SG_ SET_Deceleration_State : 31|2@0+ (1,0) [0|0] "" IVI
  SG_ ADL3_DisclaimerRepetitionRequest : 36|1@0+ (1,0) [0|0] "" IVI
  SG_ SET_ADL3Activation_State : 42|2@0+ (1,0) [0|0] "" IVI
  SG_ SET_AD_HandsOff_State : 44|2@0+ (1,0) [0|0] "" IVI
  SG_ SET_ALC_AssistMode_State : 46|2@0+ (1,0) [0|0] "" IVI

BO_ 1172 IVI_R17: 2 IVI
  SG_ EcoNavRechargeDuringTrip : 2|3@0+ (1,0) [0|0] "" Vector__XXX
  SG_ RST_GearShiftBuzzerActivRequest : 7|2@0+ (1,0) [0|0] "" Vector__XXX
  SG_ SC_SmartchargingActivationStatus : 13|2@0+ (1,0) [0|0] "" Vector__XXX
  SG_ SC_PresoakActivationStatus : 15|2@0+ (1,0) [0|0] "" Vector__XXX

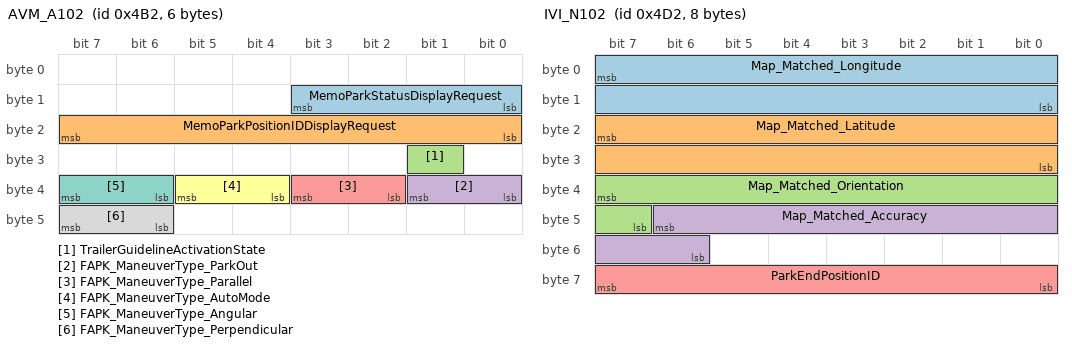
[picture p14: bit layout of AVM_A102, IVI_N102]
BO_ 1202 AVM_A102: 6 Vector__XXX
  SG_ MemoParkStatusDisplayRequest : 11|4@0+ (1,0) [0|15] "" IVI
  SG_ MemoParkPositionIDDisplayRequest : 23|8@0+ (1,0) [0|250] "" IVI
  SG_ TrailerGuidelineActivationState : 25|1@0+ (1,0) [0|0] "" IVI
  SG_ FAPK_ManeuverType_ParkOut : 33|2@0+ (1,0) [0|0] "" IVI
  SG_ FAPK_ManeuverType_Parallel : 35|2@0+ (1,0) [0|0] "" IVI
  SG_ FAPK_ManeuverType_AutoMode : 37|2@0+ (1,0) [0|0] "" IVI
  SG_ FAPK_ManeuverType_Angular : 39|2@0+ (1,0) [0|0] "" IVI
  SG_ FAPK_ManeuverType_Perpendicular : 47|2@0+ (1,0) [0|0] "" IVI

BO_ 1203 FRCAMERA_A110: 5 Vector__XXX
  SG_ OSPSpeedLimit : 15|8@0+ (1,5) [5|200] "Kmh/Mph" IVI

BO_ 1234 IVI_N102: 8 IVI
  SG_ Map_Matched_Longitude : 7|16@0+ (0.00010,-0.2) [-0.2|0.2] "min" Vector__XXX
  SG_ Map_Matched_Latitude : 23|16@0+ (0.00010,-0.2) [-0.2|0.2] "min" Vector__XXX
  SG_ Map_Matched_Orientation : 39|9@0+ (1,-180) [-180|179] "°" Vector__XXX
  SG_ Map_Matched_Accuracy : 46|9@0+ (0.1,0) [0|50] "m" Vector__XXX
  SG_ ParkEndPositionID : 63|8@0+ (1,0) [0|250] "" Vector__XXX

BO_ 1252 ECM_A14: 8 Vector__XXX
  SG_ NominalFuelConsumption : 55|8@0+ (80,0) [0|20400] "mm3" IVI

BO_ 1276 ADAS_A6: 8 Vector__XXX
  SG_ BCI_ActivationState : 32|1@0+ (1,0) [0|0] "" IVI
  SG_ ACC_Status_Slow : 45|4@0+ (1,0) [0|0] "" IVI

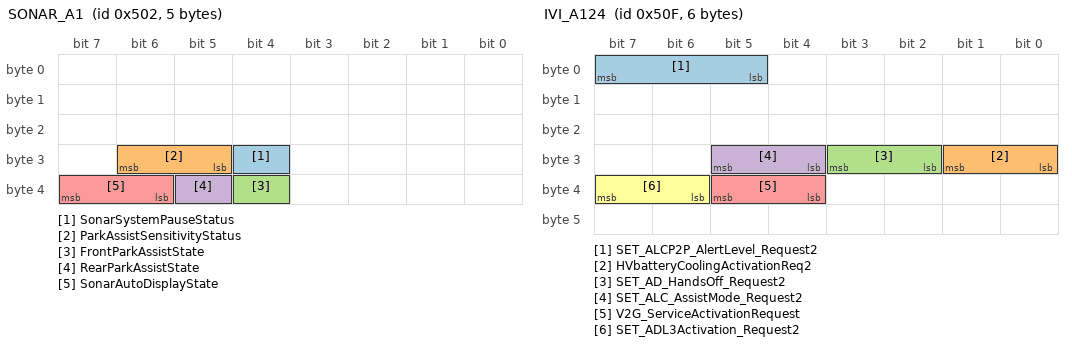
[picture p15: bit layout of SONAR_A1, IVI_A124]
BO_ 1282 SONAR_A1: 5 Vector__XXX
  SG_ SonarSystemPauseStatus : 28|1@0+ (1,0) [0|0] "" IVI
  SG_ ParkAssistSensitivityStatus : 30|2@0+ (1,0) [0|0] "" IVI
  SG_ FrontParkAssistState : 36|1@0+ (1,0) [0|0] "" IVI
  SG_ RearParkAssistState : 37|1@0+ (1,0) [0|0] "" IVI
  SG_ SonarAutoDisplayState : 39|2@0+ (1,0) [0|0] "" IVI

BO_ 1292 IVI_R106: 1 IVI
  SG_ RST_TrackSettings : 4|1@0+ (1,0) [0|0] "" Vector__XXX
  SG_ BrakePedalLevelRequest : 7|3@0+ (1,0) [0|0] "" Vector__XXX

BO_ 1294 BLM_A102: 1 Vector__XXX
  SG_ VirtualKeyMenuState : 7|2@0+ (1,0) [0|0] "" IVI

BO_ 1295 IVI_A124: 6 IVI
  SG_ SET_ALCP2P_AlertLevel_Request2 : 7|3@0+ (1,0) [0|0] "" Vector__XXX
  SG_ HVbatteryCoolingActivationReq2 : 25|2@0+ (1,0) [0|0] "" Vector__XXX
  SG_ SET_AD_HandsOff_Request2 : 27|2@0+ (1,0) [0|0] "" Vector__XXX
  SG_ SET_ALC_AssistMode_Request2 : 29|2@0+ (1,0) [0|0] "" Vector__XXX
  SG_ V2G_ServiceActivationRequest : 37|2@0+ (1,0) [0|0] "" Vector__XXX
  SG_ SET_ADL3Activation_Request2 : 39|2@0+ (1,0) [0|0] "" Vector__XXX

BO_ 1296 TCU_A103: 1 Vector__XXX
  SG_ IVI_SafeMode : 3|1@0+ (1,0) [0|0] "" IVI
  SG_ IVI_SafeModePersistentON : 4|1@0+ (1,0) [0|0] "" IVI
  SG_ IVI_SafeModeRebootReason : 7|3@0+ (1,0) [0|0] "" IVI

BO_ 1299 SONAR_A3: 5 Vector__XXX
  SG_ FKP_ObstacleZone_RF : 1|2@0+ (1,0) [0|0] "" IVI
  SG_ FKP_ObstacleZone_LRC : 3|2@0+ (1,0) [0|0] "" IVI
  SG_ FKP_ObstacleZone_LFC : 5|2@0+ (1,0) [0|0] "" IVI
  SG_ FKP_ObstacleZone_LF : 7|2@0+ (1,0) [0|0] "" IVI
  SG_ FKP_ObstacleZone_RRC : 9|2@0+ (1,0) [0|0] "" IVI
  SG_ FKP_ObstacleZone_RR : 11|2@0+ (1,0) [0|0] "" IVI
  SG_ FKP_ObstacleZone_RL : 13|2@0+ (1,0) [0|0] "" IVI
  SG_ FKP_ObstacleZone_RFC : 15|2@0+ (1,0) [0|0] "" IVI
  SG_ FKP_FrontMiddleL_Scan : 16|1@0+ (1,0) [0|0] "" IVI
  SG_ FKP_FrontMiddleR_Hatch : 17|1@0+ (1,0) [0|0] "" IVI
  SG_ FKP_FrontMiddleL_Hatch : 18|1@0+ (1,0) [0|0] "" IVI
  SG_ FKP_FrontFrontR_Scan : 19|1@0+ (1,0) [0|0] "" IVI
  SG_ FKP_FrontFrontR_Hatch : 20|1@0+ (1,0) [0|0] "" IVI
  SG_ FKP_FrontFrontL_Scan : 21|1@0+ (1,0) [0|0] "" IVI
  SG_ FKP_ImageDisplayRequest : 22|1@0+ (1,0) [0|0] "" IVI
  SG_ FKP_FrontMiddleR_Scan : 23|1@0+ (1,0) [0|0] "" IVI
  SG_ FKP_RearRearR_Scan : 24|1@0+ (1,0) [0|0] "" IVI
  SG_ FKP_RearRearR_Hatch : 25|1@0+ (1,0) [0|0] "" IVI
  SG_ FKP_RearRearL_Scan : 26|1@0+ (1,0) [0|0] "" IVI
  SG_ FKP_RearRearL_Hatch : 27|1@0+ (1,0) [0|0] "" IVI
  SG_ FKP_RearMiddleR_Scan : 28|1@0+ (1,0) [0|0] "" IVI
  SG_ FKP_RearMiddleR_Hatch : 29|1@0+ (1,0) [0|0] "" IVI
  SG_ FKP_RearMiddleL_Scan : 30|1@0+ (1,0) [0|0] "" IVI
  SG_ FKP_RearMiddleL_Hatch : 31|1@0+ (1,0) [0|0] "" IVI
  SG_ FKP_FrontFrontL_Hatch : 32|1@0+ (1,0) [0|0] "" IVI
  SG_ UPA_RearRight_Hatch : 33|1@0+ (1,0) [0|0] "" IVI
  SG_ UPA_RearMiddle_Hatch : 34|1@0+ (1,0) [0|0] "" IVI
  SG_ UPA_RearLeft_Hatch : 35|1@0+ (1,0) [0|0] "" IVI
  SG_ UPA_FrontRight_Hatch : 36|1@0+ (1,0) [0|0] "" IVI
  SG_ UPA_FrontMiddle_Hatch : 37|1@0+ (1,0) [0|0] "" IVI
  SG_ UPA_FrontLeft_Hatch : 38|1@0+ (1,0) [0|0] "" IVI
  SG_ FKP_ActivationStatus : 39|1@0+ (1,0) [0|0] "" IVI

BO_ 1303 FRCAMERA_A2: 8 Vector__XXX
  SG_ RainSymbolDisplayRequest : 14|1@0+ (1,0) [0|0] "" IVI
  SG_ TSR_OSP_SpeedSignalZone1 : 23|8@0+ (1,0) [0|200] "wu" IVI
  SG_ TSR_OSP_ActivationStatus : 42|2@0+ (1,0) [0|0] "" IVI
  SG_ OSPOverSpeedDisplayRequest : 47|1@0+ (1,0) [0|0] "" IVI

BO_ 1310 MM_NAV_CARTO_R1: 8 IVI
  SG_ CartoData : 4|61@0+ (1,0) [0|0] "" Vector__XXX
  SG_ OSPDataType : 7|3@0+ (1,0) [0|0] "" Vector__XXX

BO_ 1315 BCM_A8: 3 Vector__XXX
  SG_ AbsoluteTimeSince1rstIgnition : 7|24@0+ (1,0) [0|1.677E7] "min" IVI

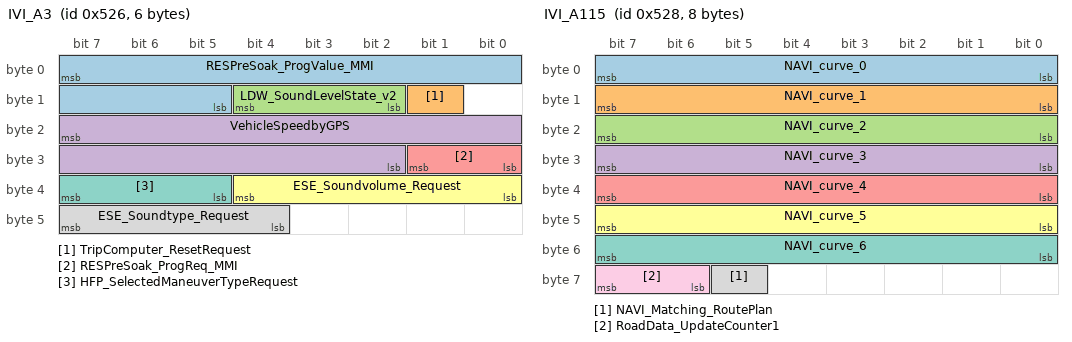
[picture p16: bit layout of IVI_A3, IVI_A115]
BO_ 1318 IVI_A3: 6 IVI
  SG_ RESPreSoak_ProgValue_MMI : 7|11@0+ (1,0) [0|1440] "min" Vector__XXX
  SG_ TripComputer_ResetRequest : 9|1@0+ (1,0) [0|0] "" Vector__XXX
  SG_ LDW_SoundLevelState_v2 : 12|3@0+ (1,0) [0|0] "" Vector__XXX
  SG_ VehicleSpeedbyGPS : 23|14@0+ (0.03,0) [0|255] "km/h" Vector__XXX
  SG_ RESPreSoak_ProgReq_MMI : 25|2@0+ (1,0) [0|0] "" Vector__XXX
  SG_ ESE_Soundvolume_Request : 36|5@0+ (1,0) [0|0] "" Vector__XXX
  SG_ HFP_SelectedManeuverTypeRequest : 39|3@0+ (1,0) [0|0] "" Vector__XXX
  SG_ ESE_Soundtype_Request : 47|4@0+ (1,0) [0|0] "" Vector__XXX

BO_ 1319 ADAS_N101: 4 Vector__XXX
  SG_ ADL2_CurveWarningState : 23|8@0+ (1,0) [0|255] "wu" IVI
  SG_ ADL2L3_P2PFeatureState : 31|8@0+ (1,0) [0|255] "wu" IVI

BO_ 1320 IVI_A115: 8 IVI
  SG_ NAVI_curve_0 : 7|8@0+ (1,0) [0|255] "" Vector__XXX
  SG_ NAVI_curve_1 : 15|8@0+ (1,0) [0|255] "" Vector__XXX
  SG_ NAVI_curve_2 : 23|8@0+ (1,0) [0|255] "" Vector__XXX
  SG_ NAVI_curve_3 : 31|8@0+ (1,0) [0|255] "" Vector__XXX
  SG_ NAVI_curve_4 : 39|8@0+ (1,0) [0|255] "" Vector__XXX
  SG_ NAVI_curve_5 : 47|8@0+ (1,0) [0|255] "" Vector__XXX
  SG_ NAVI_curve_6 : 55|8@0+ (1,0) [0|255] "" Vector__XXX
  SG_ NAVI_Matching_RoutePlan : 61|1@0+ (1,0) [0|0] "" Vector__XXX
  SG_ RoadData_UpdateCounter1 : 63|2@0+ (1,0) [0|3] "" Vector__XXX

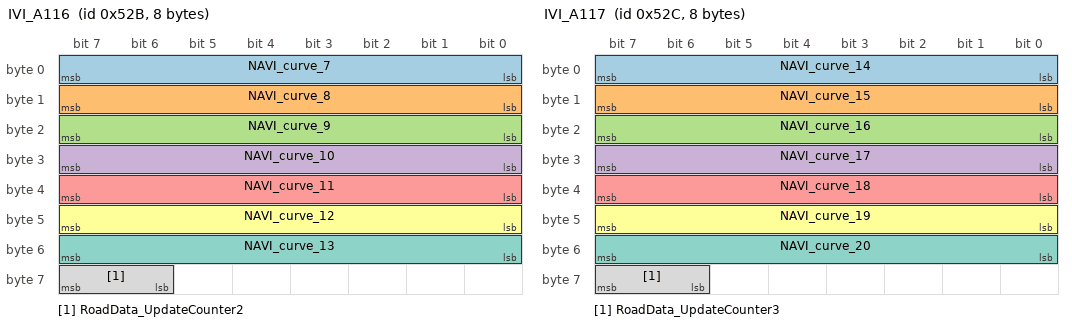
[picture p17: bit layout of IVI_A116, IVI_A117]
BO_ 1323 IVI_A116: 8 IVI
  SG_ NAVI_curve_7 : 7|8@0+ (1,0) [0|255] "" Vector__XXX
  SG_ NAVI_curve_8 : 15|8@0+ (1,0) [0|255] "" Vector__XXX
  SG_ NAVI_curve_9 : 23|8@0+ (1,0) [0|255] "" Vector__XXX
  SG_ NAVI_curve_10 : 31|8@0+ (1,0) [0|255] "" Vector__XXX
  SG_ NAVI_curve_11 : 39|8@0+ (1,0) [0|255] "" Vector__XXX
  SG_ NAVI_curve_12 : 47|8@0+ (1,0) [0|255] "" Vector__XXX
  SG_ NAVI_curve_13 : 55|8@0+ (1,0) [0|255] "" Vector__XXX
  SG_ RoadData_UpdateCounter2 : 63|2@0+ (1,0) [0|3] "" Vector__XXX

BO_ 1324 IVI_A117: 8 IVI
  SG_ NAVI_curve_14 : 7|8@0+ (1,0) [0|255] "" Vector__XXX
  SG_ NAVI_curve_15 : 15|8@0+ (1,0) [0|255] "" Vector__XXX
  SG_ NAVI_curve_16 : 23|8@0+ (1,0) [0|255] "" Vector__XXX
  SG_ NAVI_curve_17 : 31|8@0+ (1,0) [0|255] "" Vector__XXX
  SG_ NAVI_curve_18 : 39|8@0+ (1,0) [0|255] "" Vector__XXX
  SG_ NAVI_curve_19 : 47|8@0+ (1,0) [0|255] "" Vector__XXX
  SG_ NAVI_curve_20 : 55|8@0+ (1,0) [0|255] "" Vector__XXX
  SG_ RoadData_UpdateCounter3 : 63|2@0+ (1,0) [0|3] "" Vector__XXX

BO_ 1325 IVI_A118: 8 IVI
  SG_ NAVI_DistanceToBranch : 7|8@0+ (10,-500) [-500|1000] "m" Vector__XXX
  SG_ NAVI_BranchMultipleInfo : 8|1@0+ (1,0) [0|0] "" Vector__XXX
  SG_ NAVI_BranchDirection : 10|2@0+ (1,0) [0|0] "" Vector__XXX
  SG_ NAVI_CurveDirection : 15|5@0+ (1,0) [0|19] "-" Vector__XXX
  SG_ NaviGPS_PositioningStatus : 16|1@0+ (1,0) [0|0] "" Vector__XXX
  SG_ NAVI_Matching_Status : 17|1@0+ (1,0) [0|0] "" Vector__XXX
  SG_ NAVI_MatchingReset : 18|1@0+ (1,0) [0|0] "" Vector__XXX
  SG_ NAVI_DistanceToLinkFailure : 23|5@0+ (25,0) [0|500] "m" Vector__XXX
  SG_ NAVI_LinkFailure : 24|1@0+ (1,0) [0|0] "" Vector__XXX
  SG_ NAVI_TurningStatus : 25|1@0+ (1,0) [0|0] "" Vector__XXX
  SG_ NAVI_CurvatureError : 26|1@0+ (1,0) [0|0] "" Vector__XXX
  SG_ NAVI_LinkFailurePoint : 31|5@0+ (1,0) [0|30] "-" Vector__XXX
  SG_ NAVI_DistanceToIntersection : 39|6@0+ (10,0) [0|630] "m" Vector__XXX
  SG_ InGuidingRoute : 40|1@0+ (1,0) [0|0] "" Vector__XXX
  SG_ Current_Roadtype : 43|3@0+ (1,0) [0|0] "" Vector__XXX
  SG_ NAVI_DirectionDifference : 47|4@0+ (2.5,0) [0|35] "deg" Vector__XXX
  SG_ RoadData_UpdateCounter4 : 49|2@0+ (1,0) [0|3] "" Vector__XXX
  SG_ DistanceToTollgate : 55|6@0+ (10,0) [0|630] "m" Vector__XXX
  SG_ RouteGuiding_flag : 60|1@0+ (1,0) [0|0] "" Vector__XXX
  SG_ Current_Linktype : 63|3@0+ (1,0) [0|0] "" Vector__XXX

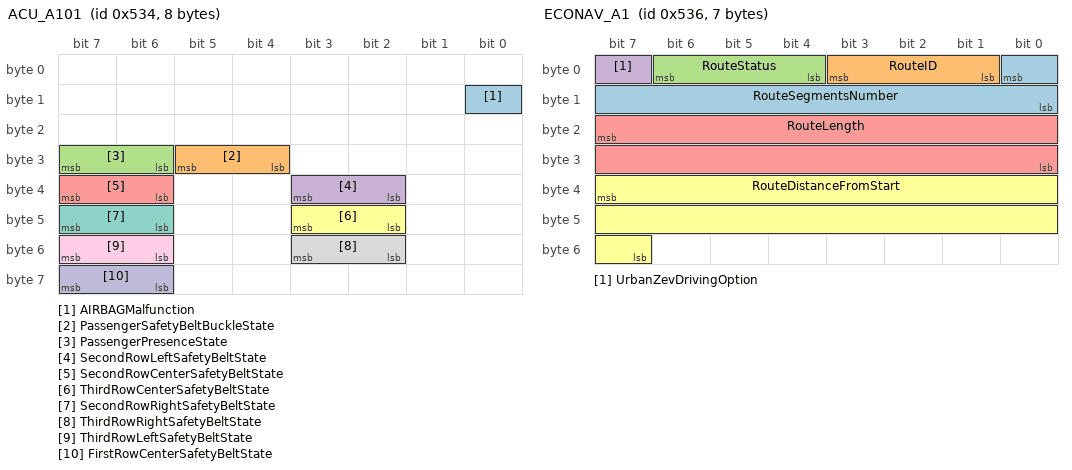
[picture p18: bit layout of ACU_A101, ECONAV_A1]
BO_ 1332 ACU_A101: 8 Vector__XXX
  SG_ AIRBAGMalfunction : 8|1@0+ (1,0) [0|0] "" IVI
  SG_ PassengerSafetyBeltBuckleState : 29|2@0+ (1,0) [0|0] "" IVI
  SG_ PassengerPresenceState : 31|2@0+ (1,0) [0|0] "" IVI
  SG_ SecondRowLeftSafetyBeltState : 35|2@0+ (1,0) [0|0] "" IVI
  SG_ SecondRowCenterSafetyBeltState : 39|2@0+ (1,0) [0|0] "" IVI
  SG_ ThirdRowCenterSafetyBeltState : 43|2@0+ (1,0) [0|0] "" IVI
  SG_ SecondRowRightSafetyBeltState : 47|2@0+ (1,0) [0|0] "" IVI
  SG_ ThirdRowRightSafetyBeltState : 51|2@0+ (1,0) [0|0] "" IVI
  SG_ ThirdRowLeftSafetyBeltState : 55|2@0+ (1,0) [0|0] "" IVI
  SG_ FirstRowCenterSafetyBeltState : 63|2@0+ (1,0) [0|0] "" IVI

BO_ 1334 ECONAV_A1: 7 IVI
  SG_ RouteSegmentsNumber : 0|9@0+ (1,1) [1|512] "wu" Vector__XXX
  SG_ RouteID : 3|3@0+ (1,0) [0|0] "" Vector__XXX
  SG_ RouteStatus : 6|3@0+ (1,0) [0|0] "" Vector__XXX
  SG_ UrbanZevDrivingOption : 7|1@0+ (1,0) [0|0] "" Vector__XXX
  SG_ RouteLength : 23|16@0+ (0.1,0) [0|5000] "km" Vector__XXX
  SG_ RouteDistanceFromStart : 39|17@0+ (10,0) [0|1024000] "m" Vector__XXX

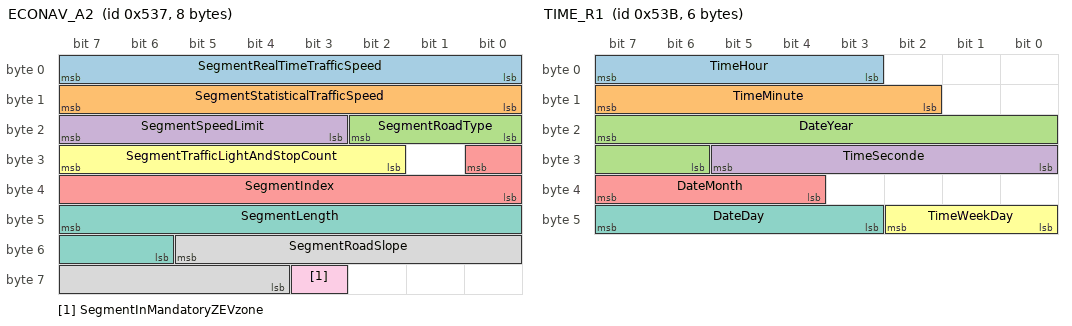
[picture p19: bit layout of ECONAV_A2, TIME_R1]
BO_ 1335 ECONAV_A2: 8 IVI
  SG_ SegmentRealTimeTrafficSpeed : 7|8@0+ (1,0) [0|200] "km/h" Vector__XXX
  SG_ SegmentStatisticalTrafficSpeed : 15|8@0+ (1,0) [0|200] "km/h" Vector__XXX
  SG_ SegmentRoadType : 18|3@0+ (1,0) [0|0] "" Vector__XXX
  SG_ SegmentSpeedLimit : 23|5@0+ (10,0) [0|200] "km/h" Vector__XXX
  SG_ SegmentIndex : 24|9@0+ (1,1) [1|512] "" Vector__XXX
  SG_ SegmentTrafficLightAndStopCount : 31|6@0+ (1,0) [0|62] "" Vector__XXX
  SG_ SegmentLength : 47|10@0+ (10,0) [0|8000] "m" Vector__XXX
  SG_ SegmentRoadSlope : 53|10@0+ (0.1,-40) [-40|40] "%" Vector__XXX
  SG_ SegmentInMandatoryZEVzone : 59|1@0+ (1,0) [0|0] "" Vector__XXX

BO_ 1339 TIME_R1: 6 IVI
  SG_ TimeHour : 7|5@0+ (1,0) [0|23] "h" Vector__XXX
  SG_ TimeMinute : 15|6@0+ (1,0) [0|59] "min" Vector__XXX
  SG_ DateYear : 23|10@0+ (1,2000) [2000|3000] "year" Vector__XXX
  SG_ TimeSeconde : 29|6@0+ (1,0) [0|59] "s" Vector__XXX
  SG_ DateMonth : 39|4@0+ (1,0) [0|12] "month" Vector__XXX
  SG_ TimeWeekDay : 42|3@0+ (1,0) [0|0] "" Vector__XXX
  SG_ DateDay : 47|5@0+ (1,0) [0|31] "day" Vector__XXX

BO_ 1341 SONAR_A4: 8 Vector__XXX
  SG_ UPA_SoundRecurrenceType : 0|1@0+ (1,0) [0|0] "" IVI
  SG_ UPA_SoundRecurrencePeriod : 7|7@0+ (0.1,0) [0|12.6] "Hz" IVI
  SG_ UPA_SystemState : 9|2@0+ (1,0) [0|0] "" IVI
  SG_ UPA_Obstacle_Zone_Front_Right : 12|3@0+ (1,0) [0|0] "" IVI
  SG_ UPA_Obstacle_Zone_Front_Left : 15|3@0+ (1,0) [0|0] "" IVI
  SG_ UPA_Image_DisplayRequest : 17|2@0+ (1,0) [0|0] "" IVI
  SG_ UPA_Obstacle_Zone_Rear_Right : 20|3@0+ (1,0) [0|0] "" IVI
  SG_ UPA_Obstacle_Zone_Rear_Left : 23|3@0+ (1,0) [0|0] "" IVI
  SG_ UPA_SoundActivationBeep : 24|1@0+ (1,0) [0|0] "" IVI
  SG_ UPA_SoundErrorBeep : 25|1@0+ (1,0) [0|0] "" IVI
  SG_ UPA_Obstacle_Zone_Rear_Center : 28|3@0+ (1,0) [0|0] "" IVI
  SG_ UPA_Obstacle_Zone_Front_Center : 31|3@0+ (1,0) [0|0] "" IVI
  SG_ SensorAvailabilityFrontLeft : 32|1@0+ (1,0) [0|0] "" IVI
  SG_ SensorAvailabilityFrontCenter : 33|1@0+ (1,0) [0|0] "" IVI
  SG_ UPA_SoundObstacleZone : 36|3@0+ (1,0) [0|0] "" IVI
  SG_ UPAStatusDisplayRequest : 39|3@0+ (1,0) [0|0] "" IVI
  SG_ SensorAvailabilityFrontRight : 40|1@0+ (1,0) [0|0] "" IVI
  SG_ SonarObstacleDistanceDisplay : 44|4@0+ (1,0) [0|0] "" IVI
  SG_ ParkAssistVolumeState : 47|3@0+ (1,0) [0|0] "" IVI
  SG_ SensorAvailabilityRearRight : 53|1@0+ (1,0) [0|0] "" IVI
  SG_ SensorAvailabilityRearLeft : 54|1@0+ (1,0) [0|0] "" IVI
  SG_ SensorAvailabilityRearCenter : 55|1@0+ (1,0) [0|0] "" IVI
  SG_ UPA_ClosingAuthorization : 58|1@0+ (1,0) [0|0] "" IVI

BA_DEF_  "BusType" STRING;
BA_DEF_ BO_  "CANFD_BRS" ENUM "0","1";
BA_DEF_ BO_  "GenMsgSendType" STRING;
BA_DEF_ SG_  "Unavailable_Value" STRING;
BA_DEF_ BO_  "VFrameFormat" ENUM "StandardCAN","ExtendedCAN","reserved","reserved","reserved","reserved","reserved","reserved","reserved","reserved","reserved","reserved","reserved","reserved","StandardCAN_FD","ExtendedCAN_FD";
BA_DEF_ BO_  "GenMsgCycleTime" INT 0 50000;
BA_DEF_ BO_  "Exclusion_time" INT 0 50000;
BA_DEF_ SG_  "Event" STRING;
BA_DEF_ BO_  "Optional_Frame" STRING;

BA_DEF_DEF_  "CANFD_BRS" "0";
BA_DEF_DEF_  "Event" "false";
BA_DEF_DEF_  "GenMsgCycleTime" 0;
BA_DEF_DEF_  "Optional_Frame" "false";
BA_DEF_DEF_  "VFrameFormat" "StandardCAN";

BA_ "BusType" "CAN";
BA_ "Exclusion_time" BO_ 32 4;
BA_ "GenMsgCycleTime" BO_ 32 500;
BA_ "GenMsgSendType" BO_ 32 "Periodic and Event";
BA_ "GenMsgCycleTime" BO_ 116 10;
BA_ "GenMsgSendType" BO_ 116 "Periodic";
BA_ "GenMsgCycleTime" BO_ 117 10;
BA_ "GenMsgSendType" BO_ 117 "Periodic";
BA_ "GenMsgCycleTime" BO_ 168 10;
BA_ "GenMsgSendType" BO_ 168 "Periodic";
BA_ "GenMsgCycleTime" BO_ 171 10;
BA_ "GenMsgSendType" BO_ 171 "Periodic";
BA_ "GenMsgCycleTime" BO_ 180 10;
BA_ "GenMsgSendType" BO_ 180 "Periodic";
BA_ "GenMsgCycleTime" BO_ 286 10;
BA_ "GenMsgSendType" BO_ 286 "Periodic";
BA_ "GenMsgCycleTime" BO_ 303 10;
BA_ "GenMsgSendType" BO_ 303 "Periodic";
BA_ "GenMsgCycleTime" BO_ 514 20;
BA_ "GenMsgSendType" BO_ 514 "Periodic";
BA_ "GenMsgCycleTime" BO_ 534 20;
BA_ "GenMsgSendType" BO_ 534 "Periodic";
BA_ "GenMsgCycleTime" BO_ 606 20;
BA_ "GenMsgSendType" BO_ 606 "Periodic";
BA_ "GenMsgCycleTime" BO_ 649 20;
BA_ "GenMsgSendType" BO_ 649 "Periodic";
BA_ "GenMsgCycleTime" BO_ 650 20;
BA_ "GenMsgSendType" BO_ 650 "Periodic";
BA_ "GenMsgCycleTime" BO_ 791 50;
BA_ "GenMsgSendType" BO_ 791 "Periodic";
BA_ "GenMsgCycleTime" BO_ 823 50;
BA_ "GenMsgSendType" BO_ 823 "Periodic";
BA_ "GenMsgCycleTime" BO_ 893 100;
BA_ "GenMsgSendType" BO_ 893 "Periodic";
BA_ "GenMsgCycleTime" BO_ 928 100;
BA_ "GenMsgSendType" BO_ 928 "Periodic";
BA_ "GenMsgCycleTime" BO_ 929 100;
BA_ "GenMsgSendType" BO_ 929 "Periodic";
BA_ "GenMsgCycleTime" BO_ 931 100;
BA_ "GenMsgSendType" BO_ 931 "Periodic";
BA_ "Exclusion_time" BO_ 934 10;
BA_ "GenMsgCycleTime" BO_ 934 100;
BA_ "GenMsgSendType" BO_ 934 "Periodic and Event";
BA_ "Exclusion_time" BO_ 955 10;
BA_ "GenMsgCycleTime" BO_ 955 1000;
BA_ "GenMsgSendType" BO_ 955 "Periodic and Event";
BA_ "Exclusion_time" BO_ 961 20;
BA_ "GenMsgCycleTime" BO_ 961 100;
BA_ "GenMsgSendType" BO_ 961 "Periodic and Event";
BA_ "Exclusion_time" BO_ 962 20;
BA_ "GenMsgCycleTime" BO_ 962 100;
BA_ "GenMsgSendType" BO_ 962 "Periodic and Event";
BA_ "Exclusion_time" BO_ 967 10;
BA_ "GenMsgCycleTime" BO_ 967 100;
BA_ "GenMsgSendType" BO_ 967 "Periodic and Event";
BA_ "GenMsgCycleTime" BO_ 969 100;
BA_ "GenMsgSendType" BO_ 969 "Periodic";
BA_ "GenMsgCycleTime" BO_ 970 100;
BA_ "GenMsgSendType" BO_ 970 "Periodic";
BA_ "Exclusion_time" BO_ 972 20;
BA_ "GenMsgCycleTime" BO_ 972 100;
BA_ "GenMsgSendType" BO_ 972 "Periodic and Event";
BA_ "Exclusion_time" BO_ 986 20;
BA_ "GenMsgCycleTime" BO_ 986 100;
BA_ "GenMsgSendType" BO_ 986 "Periodic and Event";
BA_ "Exclusion_time" BO_ 993 20;
BA_ "GenMsgCycleTime" BO_ 993 100;
BA_ "GenMsgSendType" BO_ 993 "Periodic and Event";
BA_ "GenMsgCycleTime" BO_ 994 100;
BA_ "GenMsgSendType" BO_ 994 "Periodic";
BA_ "Exclusion_time" BO_ 996 10;
BA_ "GenMsgCycleTime" BO_ 996 100;
BA_ "GenMsgSendType" BO_ 996 "Periodic and Event";
BA_ "Exclusion_time" BO_ 1000 10;
BA_ "GenMsgCycleTime" BO_ 1000 100;
BA_ "GenMsgSendType" BO_ 1000 "Periodic and Event";
BA_ "GenMsgCycleTime" BO_ 1001 100;
BA_ "GenMsgSendType" BO_ 1001 "Periodic";
BA_ "Exclusion_time" BO_ 1003 20;
BA_ "GenMsgCycleTime" BO_ 1003 100;
BA_ "GenMsgSendType" BO_ 1003 "Periodic and Event";
BA_ "GenMsgCycleTime" BO_ 1012 100;
BA_ "GenMsgSendType" BO_ 1012 "Periodic";
BA_ "Exclusion_time" BO_ 1017 100;
BA_ "GenMsgCycleTime" BO_ 1017 500;
BA_ "GenMsgSendType" BO_ 1017 "Periodic and Event";
BA_ "GenMsgCycleTime" BO_ 1028 100;
BA_ "GenMsgSendType" BO_ 1028 "Periodic";
BA_ "Exclusion_time" BO_ 1047 10;
BA_ "GenMsgCycleTime" BO_ 1047 200;
BA_ "GenMsgSendType" BO_ 1047 "Periodic and Event";
BA_ "Exclusion_time" BO_ 1058 20;
BA_ "GenMsgCycleTime" BO_ 1058 100;
BA_ "GenMsgSendType" BO_ 1058 "Periodic and Event";
BA_ "GenMsgCycleTime" BO_ 1064 100;
BA_ "GenMsgSendType" BO_ 1064 "Periodic";
BA_ "Exclusion_time" BO_ 1065 10;
BA_ "GenMsgCycleTime" BO_ 1065 100;
BA_ "GenMsgSendType" BO_ 1065 "Periodic and Event";
BA_ "GenMsgCycleTime" BO_ 1066 100;
BA_ "GenMsgSendType" BO_ 1066 "Periodic";
BA_ "Exclusion_time" BO_ 1068 10;
BA_ "GenMsgCycleTime" BO_ 1068 100;
BA_ "GenMsgSendType" BO_ 1068 "Periodic and Event";
BA_ "GenMsgCycleTime" BO_ 1070 100;
BA_ "GenMsgSendType" BO_ 1070 "Periodic";
BA_ "GenMsgCycleTime" BO_ 1071 100;
BA_ "GenMsgSendType" BO_ 1071 "Periodic";
BA_ "Exclusion_time" BO_ 1076 10;
BA_ "GenMsgCycleTime" BO_ 1076 100;
BA_ "GenMsgSendType" BO_ 1076 "Periodic and Event";
BA_ "Exclusion_time" BO_ 1081 20;
BA_ "GenMsgCycleTime" BO_ 1081 100;
BA_ "GenMsgSendType" BO_ 1081 "Periodic and Event";
BA_ "GenMsgCycleTime" BO_ 1086 200;
BA_ "GenMsgSendType" BO_ 1086 "Periodic";
BA_ "Exclusion_time" BO_ 1099 10;
BA_ "GenMsgCycleTime" BO_ 1099 100;
BA_ "GenMsgSendType" BO_ 1099 "Periodic and Event";
BA_ "Exclusion_time" BO_ 1100 10;
BA_ "GenMsgCycleTime" BO_ 1100 100;
BA_ "GenMsgSendType" BO_ 1100 "Periodic and Event";
BA_ "Exclusion_time" BO_ 1101 20;
BA_ "GenMsgCycleTime" BO_ 1101 100;
BA_ "GenMsgSendType" BO_ 1101 "Periodic and Event";
BA_ "Exclusion_time" BO_ 1102 10;
BA_ "GenMsgCycleTime" BO_ 1102 100;
BA_ "GenMsgSendType" BO_ 1102 "Periodic and Event";
BA_ "Exclusion_time" BO_ 1103 10;
BA_ "GenMsgCycleTime" BO_ 1103 100;
BA_ "GenMsgSendType" BO_ 1103 "Periodic and Event";
BA_ "Exclusion_time" BO_ 1104 10;
BA_ "GenMsgCycleTime" BO_ 1104 100;
BA_ "GenMsgSendType" BO_ 1104 "Periodic and Event";
BA_ "Exclusion_time" BO_ 1105 10;
BA_ "GenMsgCycleTime" BO_ 1105 100;
BA_ "GenMsgSendType" BO_ 1105 "Periodic and Event";
BA_ "Exclusion_time" BO_ 1106 20;
BA_ "GenMsgCycleTime" BO_ 1106 100;
BA_ "GenMsgSendType" BO_ 1106 "Periodic and Event";
BA_ "Exclusion_time" BO_ 1107 10;
BA_ "GenMsgCycleTime" BO_ 1107 100;
BA_ "GenMsgSendType" BO_ 1107 "Periodic and Event";
BA_ "Exclusion_time" BO_ 1108 10;
BA_ "GenMsgCycleTime" BO_ 1108 100;
BA_ "GenMsgSendType" BO_ 1108 "Periodic and Event";
BA_ "Exclusion_time" BO_ 1109 20;
BA_ "GenMsgCycleTime" BO_ 1109 100;
BA_ "GenMsgSendType" BO_ 1109 "Periodic and Event";
BA_ "Exclusion_time" BO_ 1116 10;
BA_ "GenMsgCycleTime" BO_ 1116 100;
BA_ "GenMsgSendType" BO_ 1116 "Periodic and Event";
BA_ "Exclusion_time" BO_ 1119 10;
BA_ "GenMsgCycleTime" BO_ 1119 100;
BA_ "GenMsgSendType" BO_ 1119 "Periodic and Event";
BA_ "GenMsgCycleTime" BO_ 1120 100;
BA_ "GenMsgSendType" BO_ 1120 "Periodic";
BA_ "Exclusion_time" BO_ 1135 10;
BA_ "GenMsgCycleTime" BO_ 1135 100;
BA_ "GenMsgSendType" BO_ 1135 "Periodic and Event";
BA_ "GenMsgCycleTime" BO_ 1136 100;
BA_ "GenMsgSendType" BO_ 1136 "Periodic";
BA_ "Exclusion_time" BO_ 1137 10;
BA_ "GenMsgCycleTime" BO_ 1137 100;
BA_ "GenMsgSendType" BO_ 1137 "Periodic and Event";
BA_ "GenMsgCycleTime" BO_ 1138 100;
BA_ "GenMsgSendType" BO_ 1138 "Periodic";
BA_ "Exclusion_time" BO_ 1140 10;
BA_ "GenMsgCycleTime" BO_ 1140 100;
BA_ "GenMsgSendType" BO_ 1140 "Periodic and Event";
BA_ "Exclusion_time" BO_ 1143 10;
BA_ "GenMsgCycleTime" BO_ 1143 100;
BA_ "GenMsgSendType" BO_ 1143 "Periodic and Event";
BA_ "Exclusion_time" BO_ 1144 10;
BA_ "GenMsgCycleTime" BO_ 1144 100;
BA_ "GenMsgSendType" BO_ 1144 "Periodic and Event";
BA_ "Exclusion_time" BO_ 1145 10;
BA_ "GenMsgCycleTime" BO_ 1145 100;
BA_ "GenMsgSendType" BO_ 1145 "Periodic and Event";
BA_ "Exclusion_time" BO_ 1146 10;
BA_ "GenMsgCycleTime" BO_ 1146 100;
BA_ "GenMsgSendType" BO_ 1146 "Periodic and Event";
BA_ "Exclusion_time" BO_ 1147 10;
BA_ "GenMsgCycleTime" BO_ 1147 100;
BA_ "GenMsgSendType" BO_ 1147 "Periodic and Event";
BA_ "Exclusion_time" BO_ 1150 20;
BA_ "GenMsgCycleTime" BO_ 1150 500;
BA_ "GenMsgSendType" BO_ 1150 "Periodic and Event";
BA_ "GenMsgCycleTime" BO_ 1172 100;
BA_ "GenMsgSendType" BO_ 1172 "Periodic";
BA_ "Exclusion_time" BO_ 1202 20;
BA_ "GenMsgCycleTime" BO_ 1202 100;
BA_ "GenMsgSendType" BO_ 1202 "Periodic and Event";
BA_ "GenMsgCycleTime" BO_ 1203 100;
BA_ "GenMsgSendType" BO_ 1203 "Periodic";
BA_ "Exclusion_time" BO_ 1234 20;
BA_ "GenMsgCycleTime" BO_ 1234 100;
BA_ "GenMsgSendType" BO_ 1234 "Periodic and Event";
BA_ "GenMsgCycleTime" BO_ 1252 100;
BA_ "GenMsgSendType" BO_ 1252 "Periodic";
BA_ "Exclusion_time" BO_ 1276 10;
BA_ "GenMsgCycleTime" BO_ 1276 100;
BA_ "GenMsgSendType" BO_ 1276 "Periodic and Event";
BA_ "Exclusion_time" BO_ 1282 50;
BA_ "GenMsgCycleTime" BO_ 1282 400;
BA_ "GenMsgSendType" BO_ 1282 "Periodic and Event";
BA_ "Exclusion_time" BO_ 1292 100;
BA_ "GenMsgCycleTime" BO_ 1292 3000;
BA_ "GenMsgSendType" BO_ 1292 "Periodic and Event";
BA_ "Exclusion_time" BO_ 1294 100;
BA_ "GenMsgCycleTime" BO_ 1294 3000;
BA_ "GenMsgSendType" BO_ 1294 "Periodic and Event";
BA_ "Exclusion_time" BO_ 1295 100;
BA_ "GenMsgCycleTime" BO_ 1295 3000;
BA_ "GenMsgSendType" BO_ 1295 "Periodic and Event";
BA_ "Exclusion_time" BO_ 1296 100;
BA_ "GenMsgCycleTime" BO_ 1296 3000;
BA_ "GenMsgSendType" BO_ 1296 "Periodic and Event";
BA_ "Exclusion_time" BO_ 1299 50;
BA_ "GenMsgCycleTime" BO_ 1299 400;
BA_ "GenMsgSendType" BO_ 1299 "Periodic and Event";
BA_ "Exclusion_time" BO_ 1303 20;
BA_ "GenMsgCycleTime" BO_ 1303 500;
BA_ "GenMsgSendType" BO_ 1303 "Periodic and Event";
BA_ "Exclusion_time" BO_ 1310 20;
BA_ "GenMsgCycleTime" BO_ 1310 1000;
BA_ "GenMsgSendType" BO_ 1310 "Periodic and Event";
BA_ "GenMsgCycleTime" BO_ 1315 1000;
BA_ "GenMsgSendType" BO_ 1315 "Periodic";
BA_ "Exclusion_time" BO_ 1318 50;
BA_ "GenMsgCycleTime" BO_ 1318 1000;
BA_ "GenMsgSendType" BO_ 1318 "Periodic and Event";
BA_ "Exclusion_time" BO_ 1319 20;
BA_ "GenMsgCycleTime" BO_ 1319 500;
BA_ "GenMsgSendType" BO_ 1319 "Periodic and Event";
BA_ "Exclusion_time" BO_ 1320 20;
BA_ "GenMsgCycleTime" BO_ 1320 500;
BA_ "GenMsgSendType" BO_ 1320 "Periodic and Event";
BA_ "Exclusion_time" BO_ 1323 20;
BA_ "GenMsgCycleTime" BO_ 1323 500;
BA_ "GenMsgSendType" BO_ 1323 "Periodic and Event";
BA_ "Exclusion_time" BO_ 1324 20;
BA_ "GenMsgCycleTime" BO_ 1324 500;
BA_ "GenMsgSendType" BO_ 1324 "Periodic and Event";
BA_ "Exclusion_time" BO_ 1325 20;
BA_ "GenMsgCycleTime" BO_ 1325 500;
BA_ "GenMsgSendType" BO_ 1325 "Periodic and Event";
BA_ "GenMsgCycleTime" BO_ 1332 100;
BA_ "GenMsgSendType" BO_ 1332 "Periodic";
BA_ "GenMsgCycleTime" BO_ 1334 1000;
BA_ "GenMsgSendType" BO_ 1334 "Periodic";
BA_ "Exclusion_time" BO_ 1335 50;
BA_ "GenMsgCycleTime" BO_ 1335 1000;
BA_ "GenMsgSendType" BO_ 1335 "Periodic and Event";
BA_ "Exclusion_time" BO_ 1339 100;
BA_ "GenMsgCycleTime" BO_ 1339 3000;
BA_ "GenMsgSendType" BO_ 1339 "Periodic and Event";
BA_ "GenMsgCycleTime" BO_ 1341 100;
BA_ "GenMsgSendType" BO_ 1341 "Periodic";
BA_ "Event" SG_ 32 AirbagCrashOrder_v3 "true";
BA_ "Event" SG_ 32 AirbagCrashOrder_v3 "true";
BA_ "Event" SG_ 32 AirbagCrashOrder_v3 "true";
BA_ "Event" SG_ 32 AirbagCrashOrder_v3 "true";
BA_ "Event" SG_ 32 AirbagCrashOrder_v3 "true";
BA_ "Unavailable_Value" SG_ 32 AirbagCrashOrder_v3 "Not applicable";
BA_ "Unavailable_Value" SG_ 116 PowerTrainSetPoint "0x3FF";
BA_ "Unavailable_Value" SG_ 116 RawSensor "0x3FF";
BA_ "Unavailable_Value" SG_ 116 StopAutoPhase "0b111";
BA_ "Unavailable_Value" SG_ 117 PowerTrainStatus "0b00";
BA_ "Unavailable_Value" SG_ 117 EngineRPM "0xFFFF";
BA_ "Unavailable_Value" SG_ 117 MeanEffectiveTorque "0xFFF";
BA_ "Unavailable_Value" SG_ 168 SteeringWheelAngleRaw "0x7FFF";
BA_ "Unavailable_Value" SG_ 168 SwaSensorInternalStatus "0b000";
BA_ "Unavailable_Value" SG_ 168 SteeringWheelRotationSpeed "0xFFFF";
BA_ "Unavailable_Value" SG_ 171 YawRateCorrected "0x7FF";
BA_ "Unavailable_Value" SG_ 171 BrakingPressure "0xFF";
BA_ "Unavailable_Value" SG_ 171 SteeringWheelAngleCorrected "0x7FFF";
BA_ "Unavailable_Value" SG_ 180 LongitudinalAccelCorrected "0xFFF";
BA_ "Unavailable_Value" SG_ 180 TransversalAccelCorrected "0xFFF";
BA_ "Unavailable_Value" SG_ 286 TorqueConverterState "0b11";
BA_ "Unavailable_Value" SG_ 303 GearLeverPosition_v2 "0xF";
BA_ "Unavailable_Value" SG_ 514 ABSinRegulation "0b0";
BA_ "Unavailable_Value" SG_ 514 WheelTopFL "0x7F";
BA_ "Unavailable_Value" SG_ 514 WheelTopFR "0x7F";
BA_ "Unavailable_Value" SG_ 514 MSRinRegulation "0b0";
BA_ "Unavailable_Value" SG_ 514 WheelTopRL "0x7F";
BA_ "Unavailable_Value" SG_ 514 WheelTopRR "0x7F";
BA_ "Unavailable_Value" SG_ 514 AYCMalfunction "0b0";
BA_ "Unavailable_Value" SG_ 514 AYCinRegulation "0b0";
BA_ "Unavailable_Value" SG_ 514 ASRMalfunction "0b0";
BA_ "Unavailable_Value" SG_ 514 ABSMalfunction "0b0";
BA_ "Unavailable_Value" SG_ 534 EPSWarning "0b00";
BA_ "Unavailable_Value" SG_ 649 WheelSpeedRL "0xFFFF";
BA_ "Unavailable_Value" SG_ 649 WheelSpeedRR "0xFFFF";
BA_ "Unavailable_Value" SG_ 649 VehicleSpeedBody "0xFFFF";
BA_ "Unavailable_Value" SG_ 650 WheelSpeedFR "0xFFFF";
BA_ "Unavailable_Value" SG_ 650 WheelSpeedFL "0xFFFF";
BA_ "Unavailable_Value" SG_ 650 VehicleSpeed "0xFFFF";
BA_ "Unavailable_Value" SG_ 791 ISS_EcoActivationState "0b00";
BA_ "Unavailable_Value" SG_ 791 AirCondEcoActivationState "0b00";
BA_ "Unavailable_Value" SG_ 791 ClimECOModeStatusDisplay "0b11";
BA_ "Unavailable_Value" SG_ 823 ClimAQSIndicator "0x3F";
BA_ "Unavailable_Value" SG_ 823 IoniserAutoLaunchState "0b00";
BA_ "Unavailable_Value" SG_ 823 AQMAirFreshenerDisplayRequest "0b00";
BA_ "Unavailable_Value" SG_ 823 ClimForcedRecyDisplay "0b00";
BA_ "Unavailable_Value" SG_ 823 AQMIoniserModeState "0b000";
BA_ "Unavailable_Value" SG_ 823 ClimAutoRecyclingDisplay "0b00";
BA_ "Unavailable_Value" SG_ 893 LDW_VibrationIntensityState "0b00";
BA_ "Unavailable_Value" SG_ 893 LCA_SteeringStatus2 "0b00";
BA_ "Unavailable_Value" SG_ 931 ADASISv2_STUB "null";
BA_ "Unavailable_Value" SG_ 934 APA_StatusDisplay2 "0b00";
BA_ "Event" SG_ 955 RST_Boost_Duration_MMI "true";
BA_ "Event" SG_ 955 RST_Boost_Duration_MMI "true";
BA_ "Event" SG_ 955 RST_Boost_Duration_MMI "true";
BA_ "Event" SG_ 955 RST_Boost_Duration_MMI "true";
BA_ "Unavailable_Value" SG_ 955 RST_Boost_Duration_MMI "0xFF";
BA_ "Event" SG_ 955 RST_Boost_Activation_MMI "true";
BA_ "Event" SG_ 955 RST_Boost_Activation_MMI "true";
BA_ "Event" SG_ 955 RST_Boost_Activation_MMI "true";
BA_ "Event" SG_ 955 RST_Boost_Activation_MMI "true";
BA_ "Unavailable_Value" SG_ 955 RST_Boost_Activation_MMI "0b11";
BA_ "Unavailable_Value" SG_ 961 DistanceBeforeNextAction "0xFFFFFFFFFF";
BA_ "Unavailable_Value" SG_ 961 LivingLightReq "0b00";
BA_ "Event" SG_ 961 NAVI_BootStatus "true";
BA_ "Event" SG_ 961 NAVI_BootStatus "true";
BA_ "Event" SG_ 961 NAVI_BootStatus "true";
BA_ "Event" SG_ 961 NAVI_BootStatus "true";
BA_ "Event" SG_ 961 NAVI_OperationError "true";
BA_ "Event" SG_ 961 NAVI_OperationError "true";
BA_ "Event" SG_ 961 NAVI_OperationError "true";
BA_ "Event" SG_ 961 NAVI_OperationError "true";
BA_ "Unavailable_Value" SG_ 962 APA_StatusDisplay "0b00";
BA_ "Event" SG_ 967 CDisplayAvailability "true";
BA_ "Event" SG_ 967 CDisplayAvailability "true";
BA_ "Event" SG_ 967 CDisplayAvailability "true";
BA_ "Event" SG_ 967 CDisplayAvailability "true";
BA_ "Unavailable_Value" SG_ 967 CDisplayAvailability "0b00";
BA_ "Event" SG_ 967 AutoACC2_ON_Request_MM "true";
BA_ "Event" SG_ 967 AutoACC2_ON_Request_MM "true";
BA_ "Event" SG_ 967 AutoACC2_ON_Request_MM "true";
BA_ "Event" SG_ 967 AutoACC2_ON_Request_MM "true";
BA_ "Unavailable_Value" SG_ 967 AutoACC2_ON_Request_MM "0b00";
BA_ "Unavailable_Value" SG_ 967 Audio_WorkingAuthorize "0b11";
BA_ "Unavailable_Value" SG_ 967 IVI_RefusetoSleep "0b10";
BA_ "Unavailable_Value" SG_ 967 SonarSystemPauseRequest2 "0b0";
BA_ "Unavailable_Value" SG_ 967 IVI_InitializationState "0b0";
BA_ "Unavailable_Value" SG_ 967 MMCustomerAction "0b111";
BA_ "Unavailable_Value" SG_ 967 UserFeedbackAvailability "0b1";
BA_ "Unavailable_Value" SG_ 967 AudioAvailability "0b1";
BA_ "Unavailable_Value" SG_ 967 SwitchRequest_AVM "0b0";
BA_ "Unavailable_Value" SG_ 967 ChangeViewRequest_AVM "0b00";
BA_ "Unavailable_Value" SG_ 967 Audio_ProcessingDeactivation "0b0";
BA_ "Unavailable_Value" SG_ 967 VehicleGPSreliability "0x00";
BA_ "Unavailable_Value" SG_ 967 PassengerHeatingRequest "0b00";
BA_ "Event" SG_ 967 PassengerVentilRequest "true";
BA_ "Event" SG_ 967 PassengerVentilRequest "true";
BA_ "Event" SG_ 967 PassengerVentilRequest "true";
BA_ "Event" SG_ 967 PassengerVentilRequest "true";
BA_ "Unavailable_Value" SG_ 967 PassengerVentilRequest "0b00";
BA_ "Unavailable_Value" SG_ 967 DriverHeatingRequest "0b00";
BA_ "Event" SG_ 967 DriverVentilRequest "true";
BA_ "Event" SG_ 967 DriverVentilRequest "true";
BA_ "Event" SG_ 967 DriverVentilRequest "true";
BA_ "Event" SG_ 967 DriverVentilRequest "true";
BA_ "Unavailable_Value" SG_ 967 DriverVentilRequest "0b00";
BA_ "Unavailable_Value" SG_ 967 StorageFormatRequest "0b00";
BA_ "Unavailable_Value" SG_ 967 TPMS_ResetDriverRequest2 "0b00";
BA_ "Unavailable_Value" SG_ 967 TPW_ResetDriverRequest2 "0b00";
BA_ "Event" SG_ 967 SatelliteGPSNumber "true";
BA_ "Event" SG_ 967 SatelliteGPSNumber "true";
BA_ "Event" SG_ 967 SatelliteGPSNumber "true";
BA_ "Event" SG_ 967 SatelliteGPSNumber "true";
BA_ "Unavailable_Value" SG_ 967 SatelliteGPSNumber "0x7F";
BA_ "Unavailable_Value" SG_ 967 EcoPedalForceSettingRequest "0b00";
BA_ "Event" SG_ 967 HUD_UpDownRequest2 "true";
BA_ "Event" SG_ 967 HUD_UpDownRequest2 "true";
BA_ "Event" SG_ 967 HUD_UpDownRequest2 "true";
BA_ "Event" SG_ 967 HUD_UpDownRequest2 "true";
BA_ "Unavailable_Value" SG_ 967 HUD_UpDownRequest2 "0b00";
BA_ "Unavailable_Value" SG_ 967 IVI_ParkAssistVolumeState "Not applicable";
BA_ "Unavailable_Value" SG_ 969 TorqueDistributionRatioDisplay "0xFF";
BA_ "Unavailable_Value" SG_ 970 VirtualKeyActivationState "0b0";
BA_ "Event" SG_ 972 AD_TransitionState "true";
BA_ "Event" SG_ 972 AD_TransitionState "true";
BA_ "Event" SG_ 972 AD_TransitionState "true";
BA_ "Event" SG_ 972 AD_TransitionState "true";
BA_ "Unavailable_Value" SG_ 972 AD_TransitionState "0b0000";
BA_ "Event" SG_ 972 AD2L2_HOFF_TransitonState "true";
BA_ "Event" SG_ 972 AD2L2_HOFF_TransitonState "true";
BA_ "Event" SG_ 972 AD2L2_HOFF_TransitonState "true";
BA_ "Event" SG_ 972 AD2L2_HOFF_TransitonState "true";
BA_ "Unavailable_Value" SG_ 972 AD2L2_HOFF_TransitonState "0x0";
BA_ "Event" SG_ 972 AD2L2_HON_TransitonState "true";
BA_ "Event" SG_ 972 AD2L2_HON_TransitonState "true";
BA_ "Event" SG_ 972 AD2L2_HON_TransitonState "true";
BA_ "Event" SG_ 972 AD2L2_HON_TransitonState "true";
BA_ "Unavailable_Value" SG_ 972 AD2L2_HON_TransitonState "0x0";
BA_ "Event" SG_ 972 ADL3_MRM "true";
BA_ "Event" SG_ 972 ADL3_MRM "true";
BA_ "Event" SG_ 972 ADL3_MRM "true";
BA_ "Event" SG_ 972 ADL3_MRM "true";
BA_ "Unavailable_Value" SG_ 972 ADL3_MRM "0x0";
BA_ "Unavailable_Value" SG_ 972 AD_CancelReason "0x000";
BA_ "Event" SG_ 972 ADL3_TransitionState "true";
BA_ "Event" SG_ 972 ADL3_TransitionState "true";
BA_ "Event" SG_ 972 ADL3_TransitionState "true";
BA_ "Event" SG_ 972 ADL3_TransitionState "true";
BA_ "Unavailable_Value" SG_ 972 ADL3_TransitionState "0x0";
BA_ "Event" SG_ 972 AD_CutinLeftDisplay "true";
BA_ "Event" SG_ 972 AD_CutinLeftDisplay "true";
BA_ "Event" SG_ 972 AD_CutinLeftDisplay "true";
BA_ "Event" SG_ 972 AD_CutinLeftDisplay "true";
BA_ "Unavailable_Value" SG_ 972 AD_CutinLeftDisplay "0b0000";
BA_ "Event" SG_ 972 AD_CancelReasonRER "true";
BA_ "Event" SG_ 972 AD_CancelReasonRER "true";
BA_ "Event" SG_ 972 AD_CancelReasonRER "true";
BA_ "Event" SG_ 972 AD_CancelReasonRER "true";
BA_ "Unavailable_Value" SG_ 972 AD_CancelReasonRER "0b0";
BA_ "Event" SG_ 972 AD_CutinRightDisplay "true";
BA_ "Event" SG_ 972 AD_CutinRightDisplay "true";
BA_ "Event" SG_ 972 AD_CutinRightDisplay "true";
BA_ "Event" SG_ 972 AD_CutinRightDisplay "true";
BA_ "Unavailable_Value" SG_ 972 AD_CutinRightDisplay "0b0000";
BA_ "Event" SG_ 986 AD_DriverInformation "true";
BA_ "Event" SG_ 986 AD_DriverInformation "true";
BA_ "Event" SG_ 986 AD_DriverInformation "true";
BA_ "Event" SG_ 986 AD_DriverInformation "true";
BA_ "Unavailable_Value" SG_ 986 AD_DriverInformation "0x000";
BA_ "Event" SG_ 986 ALC_Distance "true";
BA_ "Event" SG_ 986 ALC_Distance "true";
BA_ "Event" SG_ 986 ALC_Distance "true";
BA_ "Event" SG_ 986 ALC_Distance "true";
BA_ "Unavailable_Value" SG_ 986 ALC_Distance "0x3F";
BA_ "Event" SG_ 986 AD2_HandsOff_MRM "true";
BA_ "Event" SG_ 986 AD2_HandsOff_MRM "true";
BA_ "Event" SG_ 986 AD2_HandsOff_MRM "true";
BA_ "Event" SG_ 986 AD2_HandsOff_MRM "true";
BA_ "Unavailable_Value" SG_ 986 AD2_HandsOff_MRM "0x0";
BA_ "Event" SG_ 986 AD_FocusStateRequest "true";
BA_ "Event" SG_ 986 AD_FocusStateRequest "true";
BA_ "Event" SG_ 986 AD_FocusStateRequest "true";
BA_ "Event" SG_ 986 AD_FocusStateRequest "true";
BA_ "Unavailable_Value" SG_ 986 AD_FocusStateRequest "0b00";
BA_ "Event" SG_ 986 AD_AvailabilityLevel "true";
BA_ "Event" SG_ 986 AD_AvailabilityLevel "true";
BA_ "Event" SG_ 986 AD_AvailabilityLevel "true";
BA_ "Event" SG_ 986 AD_AvailabilityLevel "true";
BA_ "Unavailable_Value" SG_ 986 AD_AvailabilityLevel "0b0000";
BA_ "Event" SG_ 986 ADL3_Status "true";
BA_ "Event" SG_ 986 ADL3_Status "true";
BA_ "Event" SG_ 986 ADL3_Status "true";
BA_ "Event" SG_ 986 ADL3_Status "true";
BA_ "Unavailable_Value" SG_ 986 ADL3_Status "0b00";
BA_ "Unavailable_Value" SG_ 986 AD_MRM_PhaseCounter "0xFF";
BA_ "Unavailable_Value" SG_ 993 FirstParkStartPositionID "0x00";
BA_ "Unavailable_Value" SG_ 993 SecondParkStartPositionID "0x00";
BA_ "Unavailable_Value" SG_ 993 ThirdParkStartPositionID "0x00";
BA_ "Unavailable_Value" SG_ 993 FirstParkStartPositionDistance "0x3FF";
BA_ "Unavailable_Value" SG_ 993 ThirdParkStartPositionDistanceType "null";
BA_ "Unavailable_Value" SG_ 993 SecondParkStartPositionDistanceType "null";
BA_ "Unavailable_Value" SG_ 993 FirstParkStartPositionDistanceType "null";
BA_ "Unavailable_Value" SG_ 993 SecondParkStartPositionDistance "0x3FF";
BA_ "Unavailable_Value" SG_ 993 ThirdParkStartPositionDistance "0x3FF";
BA_ "Unavailable_Value" SG_ 994 a4WS_AnglePosition_v2 "0x7F";
BA_ "Unavailable_Value" SG_ 1000 APPRUN_ActivationState "0b0";
BA_ "Unavailable_Value" SG_ 1000 WAL_ActivationState "0b0";
BA_ "Unavailable_Value" SG_ 1000 IKeyAccessActivationState "0b0";
BA_ "Event" SG_ 1003 AD_SteeringWheelTakeOverAlert "true";
BA_ "Event" SG_ 1003 AD_SteeringWheelTakeOverAlert "true";
BA_ "Event" SG_ 1003 AD_SteeringWheelTakeOverAlert "true";
BA_ "Event" SG_ 1003 AD_SteeringWheelTakeOverAlert "true";
BA_ "Event" SG_ 1003 AD_SteeringWheelTakeOverAlert "true";
BA_ "Unavailable_Value" SG_ 1003 AD_SteeringWheelTakeOverAlert "0b000";
BA_ "Event" SG_ 1003 AD_StatusDisplay "true";
BA_ "Event" SG_ 1003 AD_StatusDisplay "true";
BA_ "Event" SG_ 1003 AD_StatusDisplay "true";
BA_ "Event" SG_ 1003 AD_StatusDisplay "true";
BA_ "Event" SG_ 1003 AD_StatusDisplay "true";
BA_ "Unavailable_Value" SG_ 1003 AD_StatusDisplay "0b0000";
BA_ "Event" SG_ 1003 ALC_HandsRequest "true";
BA_ "Event" SG_ 1003 ALC_HandsRequest "true";
BA_ "Event" SG_ 1003 ALC_HandsRequest "true";
BA_ "Event" SG_ 1003 ALC_HandsRequest "true";
BA_ "Event" SG_ 1003 ALC_HandsRequest "true";
BA_ "Unavailable_Value" SG_ 1003 ALC_HandsRequest "0b00";
BA_ "Event" SG_ 1003 ADL3_Warning "true";
BA_ "Event" SG_ 1003 ADL3_Warning "true";
BA_ "Event" SG_ 1003 ADL3_Warning "true";
BA_ "Event" SG_ 1003 ADL3_Warning "true";
BA_ "Event" SG_ 1003 ADL3_Warning "true";
BA_ "Unavailable_Value" SG_ 1003 ADL3_Warning "0x000";
BA_ "Event" SG_ 1003 ALC_StatusDisplay "true";
BA_ "Event" SG_ 1003 ALC_StatusDisplay "true";
BA_ "Event" SG_ 1003 ALC_StatusDisplay "true";
BA_ "Event" SG_ 1003 ALC_StatusDisplay "true";
BA_ "Event" SG_ 1003 ALC_StatusDisplay "true";
BA_ "Unavailable_Value" SG_ 1003 ALC_StatusDisplay "0b000";
BA_ "Unavailable_Value" SG_ 1012 TCU_MuteRadioOrder "0b0";
BA_ "Unavailable_Value" SG_ 1012 IVC_FOTAbusyFlag "0b0";
BA_ "Unavailable_Value" SG_ 1012 IVC_FOTA_Progress "0xF";
BA_ "Unavailable_Value" SG_ 1012 IVC_FOTA_Status_v2 "0x1F";
BA_ "Unavailable_Value" SG_ 1017 UTA_VigilanceLevelDisplay "0xF";
BA_ "Unavailable_Value" SG_ 1017 UTA_AlertActivationState "0b0";
BA_ "Unavailable_Value" SG_ 1017 UTA_VigilanceAlertDisplay_v2 "0b00";
BA_ "Event" SG_ 1047 AVM_WarningDisplayRequest "true";
BA_ "Event" SG_ 1047 AVM_WarningDisplayRequest "true";
BA_ "Event" SG_ 1047 AVM_WarningDisplayRequest "true";
BA_ "Event" SG_ 1047 AVM_WarningDisplayRequest "true";
BA_ "Unavailable_Value" SG_ 1047 AVM_WarningDisplayRequest "0b000";
BA_ "Event" SG_ 1047 HFP_ManeuverCompletion2 "true";
BA_ "Event" SG_ 1047 HFP_ManeuverCompletion2 "true";
BA_ "Event" SG_ 1047 HFP_ManeuverCompletion2 "true";
BA_ "Event" SG_ 1047 HFP_ManeuverCompletion2 "true";
BA_ "Unavailable_Value" SG_ 1047 HFP_ManeuverCompletion2 "0x00";
BA_ "Event" SG_ 1047 HFP_ExtendedInstrContentDisplay2 "true";
BA_ "Event" SG_ 1047 HFP_ExtendedInstrContentDisplay2 "true";
BA_ "Event" SG_ 1047 HFP_ExtendedInstrContentDisplay2 "true";
BA_ "Event" SG_ 1047 HFP_ExtendedInstrContentDisplay2 "true";
BA_ "Unavailable_Value" SG_ 1047 HFP_ExtendedInstrContentDisplay2 "0x1F";
BA_ "Unavailable_Value" SG_ 1058 OSPSpeedUnit "0b11";
BA_ "Unavailable_Value" SG_ 1058 TSR_ConfidenceLevel "0b101";
BA_ "Unavailable_Value" SG_ 1064 EcoNavFuelSaving "0x000";
BA_ "Unavailable_Value" SG_ 1064 VehicleAutonomyZEV "0x3FF";
BA_ "Unavailable_Value" SG_ 1065 HVBatteryLow "0b0";
BA_ "Unavailable_Value" SG_ 1065 HVBatteryEnergyLevel "0x7F";
BA_ "Unavailable_Value" SG_ 1065 ChargingPlugConnected_v2 "0b11";
BA_ "Unavailable_Value" SG_ 1065 AuxEnergyFlow "0b00";
BA_ "Unavailable_Value" SG_ 1065 AllWheelDriveFlag "0b0";
BA_ "Unavailable_Value" SG_ 1065 EcoNavStatus_v2 "0x0";
BA_ "Unavailable_Value" SG_ 1065 TireRotatingDirection "0b11";
BA_ "Event" SG_ 1065 TotalDrivePowerDisplay "true";
BA_ "Event" SG_ 1065 TotalDrivePowerDisplay "true";
BA_ "Event" SG_ 1065 TotalDrivePowerDisplay "true";
BA_ "Event" SG_ 1065 TotalDrivePowerDisplay "true";
BA_ "Unavailable_Value" SG_ 1065 TotalDrivePowerDisplay "0xFF";
BA_ "Unavailable_Value" SG_ 1066 HVbatteryChargeType_v2 "0b000";
BA_ "Unavailable_Value" SG_ 1068 EngineMotorEnergyFlow_v2 "0b000";
BA_ "Unavailable_Value" SG_ 1068 VehicleTractionMode "0b111";
BA_ "Unavailable_Value" SG_ 1068 EngineWheelEnergyFlow_v2 "0b000";
BA_ "Unavailable_Value" SG_ 1068 BatteryMotorEnergyFlow_v2 "0b000";
BA_ "Unavailable_Value" SG_ 1068 ChargingStatusDisplay_v2 "0b0000";
BA_ "Unavailable_Value" SG_ 1068 ChargeRemainingTimeDisplay_v2 "0x7FF";
BA_ "Unavailable_Value" SG_ 1070 UserSOC "0x0";
BA_ "Unavailable_Value" SG_ 1071 HVBatteryEnergyCap_Reachability "0x7FF";
BA_ "Unavailable_Value" SG_ 1071 AvailableEnergy_HEVC "0x7FF";
BA_ "Unavailable_Value" SG_ 1076 WAC_APRUN_ActivationState "0b0";
BA_ "Unavailable_Value" SG_ 1076 SwitchOffSESDisturbers "0b0";
BA_ "Unavailable_Value" SG_ 1081 SlopeEstimation "0xFF";
BA_ "Unavailable_Value" SG_ 1081 DistanceTotalizer "0xFFFFFFF";
BA_ "Unavailable_Value" SG_ 1086 InputPower_AC_INV "0x7F";
BA_ "Unavailable_Value" SG_ 1086 ePTCpower "0x3F";
BA_ "Event" SG_ 1099 ATCVT_RangeIndicationExtended "true";
BA_ "Event" SG_ 1099 ATCVT_RangeIndicationExtended "true";
BA_ "Event" SG_ 1099 ATCVT_RangeIndicationExtended "true";
BA_ "Event" SG_ 1099 ATCVT_RangeIndicationExtended "true";
BA_ "Unavailable_Value" SG_ 1099 ATCVT_RangeIndicationExtended "0x00";
BA_ "Unavailable_Value" SG_ 1100 RST_LaunchControlReady "0b00";
BA_ "Event" SG_ 1101 FlashingIndicatorStatusDisplay "true";
BA_ "Event" SG_ 1101 FlashingIndicatorStatusDisplay "true";
BA_ "Event" SG_ 1101 FlashingIndicatorStatusDisplay "true";
BA_ "Event" SG_ 1101 FlashingIndicatorStatusDisplay "true";
BA_ "Unavailable_Value" SG_ 1101 FlashingIndicatorStatusDisplay "0b111";
BA_ "Unavailable_Value" SG_ 1102 AutoLockActivationState "0b00";
BA_ "Unavailable_Value" SG_ 1102 AutoLightSensitivityStatus "0b00";
BA_ "Unavailable_Value" SG_ 1102 AutoFrontWiperActivationStatus "0b00";
BA_ "Unavailable_Value" SG_ 1102 AHL_ActivationState "0b11";
BA_ "Unavailable_Value" SG_ 1102 RearWiperStatus "0b00";
BA_ "Unavailable_Value" SG_ 1102 AutoUnLockActivationState "0b00";
BA_ "Unavailable_Value" SG_ 1102 AmbientLightingPatternState "0b0";
BA_ "Unavailable_Value" SG_ 1102 AutoFMHactivationState "0b0";
BA_ "Unavailable_Value" SG_ 1102 AutoInternalLightingState "0b0";
BA_ "Unavailable_Value" SG_ 1102 AutoFMHdurationState "0b000";
BA_ "Unavailable_Value" SG_ 1102 ADB_ActivationState "0b0";
BA_ "Unavailable_Value" SG_ 1102 AutoReLockActivationState "0b0";
BA_ "Unavailable_Value" SG_ 1102 FrontRearWiperDropStatus "0b0";
BA_ "Unavailable_Value" SG_ 1102 WGSactivationState "0b0";
BA_ "Event" SG_ 1102 LowBeamDisplay "true";
BA_ "Event" SG_ 1102 LowBeamDisplay "true";
BA_ "Event" SG_ 1102 LowBeamDisplay "true";
BA_ "Event" SG_ 1102 LowBeamDisplay "true";
BA_ "Unavailable_Value" SG_ 1102 LowBeamDisplay "0b0";
BA_ "Event" SG_ 1102 HighBeamDisplay "true";
BA_ "Event" SG_ 1102 HighBeamDisplay "true";
BA_ "Event" SG_ 1102 HighBeamDisplay "true";
BA_ "Event" SG_ 1102 HighBeamDisplay "true";
BA_ "Unavailable_Value" SG_ 1102 HighBeamDisplay "0b0";
BA_ "Event" SG_ 1103 BCM_SteeringPushToTalkCommand "true";
BA_ "Event" SG_ 1103 BCM_SteeringPushToTalkCommand "true";
BA_ "Event" SG_ 1103 BCM_SteeringPushToTalkCommand "true";
BA_ "Event" SG_ 1103 BCM_SteeringPushToTalkCommand "true";
BA_ "Unavailable_Value" SG_ 1103 BCM_SteeringPushToTalkCommand "0b0";
BA_ "Event" SG_ 1103 BCM_SteeringPhoneCommand "true";
BA_ "Event" SG_ 1103 BCM_SteeringPhoneCommand "true";
BA_ "Event" SG_ 1103 BCM_SteeringPhoneCommand "true";
BA_ "Event" SG_ 1103 BCM_SteeringPhoneCommand "true";
BA_ "Unavailable_Value" SG_ 1103 BCM_SteeringPhoneCommand "0b0";
BA_ "Event" SG_ 1103 BCM_SteeringCommandE "true";
BA_ "Event" SG_ 1103 BCM_SteeringCommandE "true";
BA_ "Event" SG_ 1103 BCM_SteeringCommandE "true";
BA_ "Event" SG_ 1103 BCM_SteeringCommandE "true";
BA_ "Unavailable_Value" SG_ 1103 BCM_SteeringCommandE "0b0";
BA_ "Event" SG_ 1103 BCM_SteeringCommandA "true";
BA_ "Event" SG_ 1103 BCM_SteeringCommandA "true";
BA_ "Event" SG_ 1103 BCM_SteeringCommandA "true";
BA_ "Event" SG_ 1103 BCM_SteeringCommandA "true";
BA_ "Unavailable_Value" SG_ 1103 BCM_SteeringCommandA "0b0";
BA_ "Event" SG_ 1103 BCM_MMISteeringSwitchesFailure "true";
BA_ "Event" SG_ 1103 BCM_MMISteeringSwitchesFailure "true";
BA_ "Event" SG_ 1103 BCM_MMISteeringSwitchesFailure "true";
BA_ "Event" SG_ 1103 BCM_MMISteeringSwitchesFailure "true";
BA_ "Unavailable_Value" SG_ 1103 BCM_MMISteeringSwitchesFailure "0b0";
BA_ "Unavailable_Value" SG_ 1104 ExternalTempDisplayUnit "0b0";
BA_ "Unavailable_Value" SG_ 1104 ExternalTempDisplayValue "0xFF";
BA_ "Event" SG_ 1104 SteeringPushToTalkCommand "true";
BA_ "Event" SG_ 1104 SteeringPushToTalkCommand "true";
BA_ "Event" SG_ 1104 SteeringPushToTalkCommand "true";
BA_ "Event" SG_ 1104 SteeringPushToTalkCommand "true";
BA_ "Unavailable_Value" SG_ 1104 SteeringPushToTalkCommand "0b0";
BA_ "Event" SG_ 1104 SteeringPhoneCommand "true";
BA_ "Event" SG_ 1104 SteeringPhoneCommand "true";
BA_ "Event" SG_ 1104 SteeringPhoneCommand "true";
BA_ "Event" SG_ 1104 SteeringPhoneCommand "true";
BA_ "Unavailable_Value" SG_ 1104 SteeringPhoneCommand "0b0";
BA_ "Unavailable_Value" SG_ 1104 UnitDistanceDisplayState "0b0";
BA_ "Unavailable_Value" SG_ 1104 Meter_ADACresetRequest "0b0";
BA_ "Event" SG_ 1104 DiagnosedFuelLow "true";
BA_ "Event" SG_ 1104 DiagnosedFuelLow "true";
BA_ "Event" SG_ 1104 DiagnosedFuelLow "true";
BA_ "Event" SG_ 1104 DiagnosedFuelLow "true";
BA_ "Unavailable_Value" SG_ 1104 DiagnosedFuelLow "0b00";
BA_ "Unavailable_Value" SG_ 1104 MuteRadioOrder "0b0";
BA_ "Unavailable_Value" SG_ 1104 WelcomeSequenceStatus "0b00";
BA_ "Unavailable_Value" SG_ 1104 DisplayedOilLevel "0xF";
BA_ "Unavailable_Value" SG_ 1104 MeterVolumeState "0b00";
BA_ "Unavailable_Value" SG_ 1104 FuelLevelDisplayed "0x7F";
BA_ "Unavailable_Value" SG_ 1105 DisplayedSpeedUnit "0b0";
BA_ "Event" SG_ 1105 GlobalVehicleWarningState "true";
BA_ "Event" SG_ 1105 GlobalVehicleWarningState "true";
BA_ "Event" SG_ 1105 GlobalVehicleWarningState "true";
BA_ "Event" SG_ 1105 GlobalVehicleWarningState "true";
BA_ "Event" SG_ 1105 GlobalVehicleWarningState "true";
BA_ "Unavailable_Value" SG_ 1105 GlobalVehicleWarningState "0b00";
BA_ "Event" SG_ 1105 DayNightForBacklights "true";
BA_ "Event" SG_ 1105 DayNightForBacklights "true";
BA_ "Event" SG_ 1105 DayNightForBacklights "true";
BA_ "Event" SG_ 1105 DayNightForBacklights "true";
BA_ "Event" SG_ 1105 DayNightForBacklights "true";
BA_ "Unavailable_Value" SG_ 1105 DayNightForBacklights "0b11";
BA_ "Event" SG_ 1105 NightRheostatedLightMaxPercent "true";
BA_ "Event" SG_ 1105 NightRheostatedLightMaxPercent "true";
BA_ "Event" SG_ 1105 NightRheostatedLightMaxPercent "true";
BA_ "Event" SG_ 1105 NightRheostatedLightMaxPercent "true";
BA_ "Event" SG_ 1105 NightRheostatedLightMaxPercent "true";
BA_ "Unavailable_Value" SG_ 1105 NightRheostatedLightMaxPercent "0xFF";
BA_ "Unavailable_Value" SG_ 1105 ExternalTemperature "0x1FF";
BA_ "Event" SG_ 1105 ParkingBrakeStatus "true";
BA_ "Event" SG_ 1105 ParkingBrakeStatus "true";
BA_ "Event" SG_ 1105 ParkingBrakeStatus "true";
BA_ "Event" SG_ 1105 ParkingBrakeStatus "true";
BA_ "Event" SG_ 1105 ParkingBrakeStatus "true";
BA_ "Unavailable_Value" SG_ 1105 ParkingBrakeStatus "0b11";
BA_ "Unavailable_Value" SG_ 1105 VehicleSpeedDisplayValue "0x1FF";
BA_ "Unavailable_Value" SG_ 1106 TimeBeforeOverhaul "0x1FF";
BA_ "Unavailable_Value" SG_ 1106 AutoDimmingState "0b0";
BA_ "Unavailable_Value" SG_ 1106 DayNightStatusForB_Switches "0b0";
BA_ "Unavailable_Value" SG_ 1106 RST_GearShiftBuzzerActivState "0b00";
BA_ "Unavailable_Value" SG_ 1106 TripAverageSpeed "0xFFF";
BA_ "Unavailable_Value" SG_ 1106 AutoDimmingOffsetY0 "0b0000";
BA_ "Event" SG_ 1107 RearGearEngaged "true";
BA_ "Event" SG_ 1107 RearGearEngaged "true";
BA_ "Event" SG_ 1107 RearGearEngaged "true";
BA_ "Event" SG_ 1107 RearGearEngaged "true";
BA_ "Event" SG_ 1107 RearGearEngaged "true";
BA_ "Unavailable_Value" SG_ 1107 RearGearEngaged "0b11";
BA_ "Event" SG_ 1107 EngineHoodState "true";
BA_ "Event" SG_ 1107 EngineHoodState "true";
BA_ "Event" SG_ 1107 EngineHoodState "true";
BA_ "Event" SG_ 1107 EngineHoodState "true";
BA_ "Unavailable_Value" SG_ 1107 EngineHoodState "0b00";
BA_ "Unavailable_Value" SG_ 1107 BatteryVoltage "0xFF";
BA_ "Unavailable_Value" SG_ 1107 EEM_StaticPowerLimitationRequest "0b000";
BA_ "Unavailable_Value" SG_ 1108 HandDrivingActivationState "0b0";
BA_ "Event" SG_ 1108 LowBatteryVoltageDisplay "true";
BA_ "Event" SG_ 1108 LowBatteryVoltageDisplay "true";
BA_ "Event" SG_ 1108 LowBatteryVoltageDisplay "true";
BA_ "Event" SG_ 1108 LowBatteryVoltageDisplay "true";
BA_ "Unavailable_Value" SG_ 1108 LowBatteryVoltageDisplay "0b00";
BA_ "Unavailable_Value" SG_ 1108 AFS_ActivationState "0b0";
BA_ "Unavailable_Value" SG_ 1109 HDC_StatusDisplay "0b00";
BA_ "Unavailable_Value" SG_ 1109 BrakingSystemStateDisplayRequest "0b0";
BA_ "Unavailable_Value" SG_ 1109 AccurateOdometer "0x1F";
BA_ "Event" SG_ 1109 VehicleSpeedSign "true";
BA_ "Event" SG_ 1109 VehicleSpeedSign "true";
BA_ "Event" SG_ 1109 VehicleSpeedSign "true";
BA_ "Event" SG_ 1109 VehicleSpeedSign "true";
BA_ "Event" SG_ 1109 VehicleSpeedSign "true";
BA_ "Unavailable_Value" SG_ 1109 VehicleSpeedSign "0b11";
BA_ "Unavailable_Value" SG_ 1109 EBDstateDisplayRequest "0b0";
BA_ "Unavailable_Value" SG_ 1109 ABSstateDisplayRequest "0b00";
BA_ "Unavailable_Value" SG_ 1109 VDCstateDisplayRequest "0b00";
BA_ "Unavailable_Value" SG_ 1109 TPW_AcknowledgeResetDriver "0b00";
BA_ "Event" SG_ 1109 VDCdeactivationDisplayRequest "true";
BA_ "Event" SG_ 1109 VDCdeactivationDisplayRequest "true";
BA_ "Event" SG_ 1109 VDCdeactivationDisplayRequest "true";
BA_ "Event" SG_ 1109 VDCdeactivationDisplayRequest "true";
BA_ "Event" SG_ 1109 VDCdeactivationDisplayRequest "true";
BA_ "Unavailable_Value" SG_ 1109 VDCdeactivationDisplayRequest "0b0";
BA_ "Unavailable_Value" SG_ 1109 TPW_TireCheckReminder "0b0";
BA_ "Unavailable_Value" SG_ 1109 TPW_Status "0b00";
BA_ "Unavailable_Value" SG_ 1116 ASAactivationState "0b0";
BA_ "Unavailable_Value" SG_ 1116 ADA1ActivationState "0b0";
BA_ "Unavailable_Value" SG_ 1116 TorqueDistributionRatio_slow "0x00";
BA_ "Unavailable_Value" SG_ 1116 a4WS_AnglePosition_MMI "0x7F";
BA_ "Unavailable_Value" SG_ 1116 FrontWheelAngle_MMI "0x7F";
BA_ "Unavailable_Value" SG_ 1119 EngineCoolantTemp "0xFF";
BA_ "Unavailable_Value" SG_ 1120 AdvisorEconometer "0x7F";
BA_ "Unavailable_Value" SG_ 1120 AccelerationIndicator "0x7F";
BA_ "Unavailable_Value" SG_ 1120 FluentDrivingIndicator "0x7F";
BA_ "Unavailable_Value" SG_ 1120 GSI_Respect "0x7F";
BA_ "Unavailable_Value" SG_ 1135 AVM_UserAcknowledgement "0b00";
BA_ "Unavailable_Value" SG_ 1135 APA_UserAcknowledgement "0b00";
BA_ "Event" SG_ 1135 WelcomeFunctionAvailability "true";
BA_ "Event" SG_ 1135 WelcomeFunctionAvailability "true";
BA_ "Event" SG_ 1135 WelcomeFunctionAvailability "true";
BA_ "Event" SG_ 1135 WelcomeFunctionAvailability "true";
BA_ "Unavailable_Value" SG_ 1136 EngineControlFailureLevel2 "0b0";
BA_ "Unavailable_Value" SG_ 1136 EngineControlFailureLevel1 "0b0";
BA_ "Unavailable_Value" SG_ 1137 ShiftIndicator "0b00";
BA_ "Event" SG_ 1137 RequestedSpeedDisplayRequest "true";
BA_ "Event" SG_ 1137 RequestedSpeedDisplayRequest "true";
BA_ "Event" SG_ 1137 RequestedSpeedDisplayRequest "true";
BA_ "Event" SG_ 1137 RequestedSpeedDisplayRequest "true";
BA_ "Unavailable_Value" SG_ 1137 RequestedSpeedDisplayRequest "0xFE";
BA_ "Unavailable_Value" SG_ 1137 EcoPedalMenuRequest "0b0";
BA_ "Unavailable_Value" SG_ 1137 EcoPedalForceSettingStatus "0b00";
BA_ "Unavailable_Value" SG_ 1137 CruiseControlStatus "0b111";
BA_ "Unavailable_Value" SG_ 1137 FreeKmCalculationAuthorization "0b0";
BA_ "Unavailable_Value" SG_ 1137 EngineAirTemp "0x7F";
BA_ "Unavailable_Value" SG_ 1137 EcoAdvicePedalGuideLevel "0x1F";
BA_ "Unavailable_Value" SG_ 1138 SailingActivationIdleStatus "0b0";
BA_ "Unavailable_Value" SG_ 1138 PredictiveShiftActivationState "0b00";
BA_ "Unavailable_Value" SG_ 1138 SailingStopActivationState "0b0";
BA_ "Unavailable_Value" SG_ 1138 CruiseEcoActivationState "0b00";
BA_ "Event" SG_ 1140 LKA_AlertStatus "true";
BA_ "Event" SG_ 1140 LKA_AlertStatus "true";
BA_ "Event" SG_ 1140 LKA_AlertStatus "true";
BA_ "Event" SG_ 1140 LKA_AlertStatus "true";
BA_ "Unavailable_Value" SG_ 1140 LKA_AlertStatus "0b00";
BA_ "Unavailable_Value" SG_ 1140 LKA_ActivationState "0b00";
BA_ "Event" SG_ 1140 LKA_SWheelTakeOverAlert_v3 "true";
BA_ "Event" SG_ 1140 LKA_SWheelTakeOverAlert_v3 "true";
BA_ "Event" SG_ 1140 LKA_SWheelTakeOverAlert_v3 "true";
BA_ "Event" SG_ 1140 LKA_SWheelTakeOverAlert_v3 "true";
BA_ "Unavailable_Value" SG_ 1140 LKA_SWheelTakeOverAlert_v3 "0b000";
BA_ "Event" SG_ 1143 RearRightDoorState "true";
BA_ "Event" SG_ 1143 RearRightDoorState "true";
BA_ "Event" SG_ 1143 RearRightDoorState "true";
BA_ "Event" SG_ 1143 RearRightDoorState "true";
BA_ "Event" SG_ 1143 RearRightDoorState "true";
BA_ "Unavailable_Value" SG_ 1143 RearRightDoorState "0b00";
BA_ "Event" SG_ 1143 DriverSeatBeltFailureState "true";
BA_ "Event" SG_ 1143 DriverSeatBeltFailureState "true";
BA_ "Event" SG_ 1143 DriverSeatBeltFailureState "true";
BA_ "Event" SG_ 1143 DriverSeatBeltFailureState "true";
BA_ "Unavailable_Value" SG_ 1143 DriverSeatBeltFailureState "0b00";
BA_ "Event" SG_ 1143 V_WakeUpType "true";
BA_ "Event" SG_ 1143 V_WakeUpType "true";
BA_ "Event" SG_ 1143 V_WakeUpType "true";
BA_ "Event" SG_ 1143 V_WakeUpType "true";
BA_ "Unavailable_Value" SG_ 1143 V_WakeUpType "0b111";
BA_ "Event" SG_ 1143 V_WakeUpSleepCommand "true";
BA_ "Event" SG_ 1143 V_WakeUpSleepCommand "true";
BA_ "Event" SG_ 1143 V_WakeUpSleepCommand "true";
BA_ "Event" SG_ 1143 V_WakeUpSleepCommand "true";
BA_ "Unavailable_Value" SG_ 1143 V_WakeUpSleepCommand "0b11";
BA_ "Event" SG_ 1143 RearFogLightStateDisplay "true";
BA_ "Event" SG_ 1143 RearFogLightStateDisplay "true";
BA_ "Event" SG_ 1143 RearFogLightStateDisplay "true";
BA_ "Event" SG_ 1143 RearFogLightStateDisplay "true";
BA_ "Unavailable_Value" SG_ 1143 RearFogLightStateDisplay "0b0";
BA_ "Event" SG_ 1143 DriverDoorState "true";
BA_ "Event" SG_ 1143 DriverDoorState "true";
BA_ "Event" SG_ 1143 DriverDoorState "true";
BA_ "Event" SG_ 1143 DriverDoorState "true";
BA_ "Event" SG_ 1143 DriverDoorState "true";
BA_ "Unavailable_Value" SG_ 1143 DriverDoorState "0b00";
BA_ "Event" SG_ 1143 PassengerDoorState "true";
BA_ "Event" SG_ 1143 PassengerDoorState "true";
BA_ "Event" SG_ 1143 PassengerDoorState "true";
BA_ "Event" SG_ 1143 PassengerDoorState "true";
BA_ "Event" SG_ 1143 PassengerDoorState "true";
BA_ "Unavailable_Value" SG_ 1143 PassengerDoorState "0b00";
BA_ "Event" SG_ 1143 RearLeftDoorState "true";
BA_ "Event" SG_ 1143 RearLeftDoorState "true";
BA_ "Event" SG_ 1143 RearLeftDoorState "true";
BA_ "Event" SG_ 1143 RearLeftDoorState "true";
BA_ "Event" SG_ 1143 RearLeftDoorState "true";
BA_ "Unavailable_Value" SG_ 1143 RearLeftDoorState "0b00";
BA_ "Unavailable_Value" SG_ 1144 ElectricalPowerDrived "0x1F";
BA_ "Unavailable_Value" SG_ 1144 DriveModeStatusDisplay "0b000";
BA_ "Event" SG_ 1144 WarningLightsStatus "true";
BA_ "Event" SG_ 1144 WarningLightsStatus "true";
BA_ "Event" SG_ 1144 WarningLightsStatus "true";
BA_ "Event" SG_ 1144 WarningLightsStatus "true";
BA_ "Event" SG_ 1144 WarningLightsStatus "true";
BA_ "Unavailable_Value" SG_ 1144 WarningLightsStatus "0b0";
BA_ "Event" SG_ 1144 VehicleOutsideLockedState "true";
BA_ "Event" SG_ 1144 VehicleOutsideLockedState "true";
BA_ "Event" SG_ 1144 VehicleOutsideLockedState "true";
BA_ "Event" SG_ 1144 VehicleOutsideLockedState "true";
BA_ "Event" SG_ 1144 VehicleOutsideLockedState "true";
BA_ "Unavailable_Value" SG_ 1144 VehicleOutsideLockedState "Not applicable";
BA_ "Event" SG_ 1144 FrontFogLightsDisplay "true";
BA_ "Event" SG_ 1144 FrontFogLightsDisplay "true";
BA_ "Event" SG_ 1144 FrontFogLightsDisplay "true";
BA_ "Event" SG_ 1144 FrontFogLightsDisplay "true";
BA_ "Event" SG_ 1144 FrontFogLightsDisplay "true";
BA_ "Unavailable_Value" SG_ 1144 FrontFogLightsDisplay "0b0";
BA_ "Event" SG_ 1144 BrakeLampStatus "true";
BA_ "Event" SG_ 1144 BrakeLampStatus "true";
BA_ "Event" SG_ 1144 BrakeLampStatus "true";
BA_ "Event" SG_ 1144 BrakeLampStatus "true";
BA_ "Event" SG_ 1144 BrakeLampStatus "true";
BA_ "Unavailable_Value" SG_ 1144 BrakeLampStatus "0b0";
BA_ "Unavailable_Value" SG_ 1145 SingleDoorOpeningActivationState "0b0";
BA_ "Unavailable_Value" SG_ 1145 LeftSolarLevelInfo "0x1F";
BA_ "Unavailable_Value" SG_ 1145 RightSolarLevelInfo "0x1F";
BA_ "Unavailable_Value" SG_ 1145 DriverModeUpSwitchState "0b0";
BA_ "Unavailable_Value" SG_ 1145 SRU_Position "0b0000";
BA_ "Unavailable_Value" SG_ 1145 WindowPosition_FR "0b000";
BA_ "Unavailable_Value" SG_ 1145 WindowPosition_FL "0b000";
BA_ "Unavailable_Value" SG_ 1145 ProbableCustomerFeedBackNeed "0b0";
BA_ "Unavailable_Value" SG_ 1145 WindowPosition_RR "0b000";
BA_ "Unavailable_Value" SG_ 1145 WindowPosition_RL "0b000";
BA_ "Event" SG_ 1145 DayNightSynthesis "true";
BA_ "Event" SG_ 1145 DayNightSynthesis "true";
BA_ "Event" SG_ 1145 DayNightSynthesis "true";
BA_ "Event" SG_ 1145 DayNightSynthesis "true";
BA_ "Unavailable_Value" SG_ 1145 DayNightSynthesis "0b00";
BA_ "Unavailable_Value" SG_ 1145 AutoFoldingActivationState "0b00";
BA_ "Event" SG_ 1145 AutoACC2Status_MM "true";
BA_ "Event" SG_ 1145 AutoACC2Status_MM "true";
BA_ "Event" SG_ 1145 AutoACC2Status_MM "true";
BA_ "Event" SG_ 1145 AutoACC2Status_MM "true";
BA_ "Unavailable_Value" SG_ 1145 AutoACC2Status_MM "0b00";
BA_ "Unavailable_Value" SG_ 1145 MexSwitchState "0b0";
BA_ "Event" SG_ 1146 DriverSafetyBeltBuckleState "true";
BA_ "Event" SG_ 1146 DriverSafetyBeltBuckleState "true";
BA_ "Event" SG_ 1146 DriverSafetyBeltBuckleState "true";
BA_ "Event" SG_ 1146 DriverSafetyBeltBuckleState "true";
BA_ "Event" SG_ 1146 DriverSafetyBeltBuckleState "true";
BA_ "Unavailable_Value" SG_ 1146 DriverSafetyBeltBuckleState "0b11";
BA_ "Event" SG_ 1146 ClutchSwitchMinimumTravel "true";
BA_ "Event" SG_ 1146 ClutchSwitchMinimumTravel "true";
BA_ "Event" SG_ 1146 ClutchSwitchMinimumTravel "true";
BA_ "Event" SG_ 1146 ClutchSwitchMinimumTravel "true";
BA_ "Event" SG_ 1146 ClutchSwitchMinimumTravel "true";
BA_ "Unavailable_Value" SG_ 1146 ClutchSwitchMinimumTravel "0b11";
BA_ "Unavailable_Value" SG_ 1146 TailGateStatus "0b00";
BA_ "Event" SG_ 1146 VehicleStates "true";
BA_ "Event" SG_ 1146 VehicleStates "true";
BA_ "Event" SG_ 1146 VehicleStates "true";
BA_ "Event" SG_ 1146 VehicleStates "true";
BA_ "Event" SG_ 1146 VehicleStates "true";
BA_ "Unavailable_Value" SG_ 1146 VehicleStates "0xF";
BA_ "Event" SG_ 1146 BrakeInfoStatus "true";
BA_ "Event" SG_ 1146 BrakeInfoStatus "true";
BA_ "Event" SG_ 1146 BrakeInfoStatus "true";
BA_ "Event" SG_ 1146 BrakeInfoStatus "true";
BA_ "Event" SG_ 1146 BrakeInfoStatus "true";
BA_ "Unavailable_Value" SG_ 1146 BrakeInfoStatus "0b111";
BA_ "Unavailable_Value" SG_ 1146 DeliveryModeInformation_v2 "0b00";
BA_ "Event" SG_ 1146 DriveModeRequest "true";
BA_ "Event" SG_ 1146 DriveModeRequest "true";
BA_ "Event" SG_ 1146 DriveModeRequest "true";
BA_ "Event" SG_ 1146 DriveModeRequest "true";
BA_ "Unavailable_Value" SG_ 1146 DriveModeRequest "0b111";
BA_ "Event" SG_ 1146 FlashingIndicatorStatus "true";
BA_ "Event" SG_ 1146 FlashingIndicatorStatus "true";
BA_ "Event" SG_ 1146 FlashingIndicatorStatus "true";
BA_ "Event" SG_ 1146 FlashingIndicatorStatus "true";
BA_ "Event" SG_ 1146 FlashingIndicatorStatus "true";
BA_ "Unavailable_Value" SG_ 1146 FlashingIndicatorStatus "0b111";
BA_ "Event" SG_ 1146 GADE_v2 "true";
BA_ "Event" SG_ 1146 GADE_v2 "true";
BA_ "Event" SG_ 1146 GADE_v2 "true";
BA_ "Event" SG_ 1146 GADE_v2 "true";
BA_ "Event" SG_ 1146 GADE_v2 "true";
BA_ "Unavailable_Value" SG_ 1146 GADE_v2 "0b111";
BA_ "Event" SG_ 1146 FrontWiperStatus_BCM "true";
BA_ "Event" SG_ 1146 FrontWiperStatus_BCM "true";
BA_ "Event" SG_ 1146 FrontWiperStatus_BCM "true";
BA_ "Event" SG_ 1146 FrontWiperStatus_BCM "true";
BA_ "Event" SG_ 1146 FrontWiperStatus_BCM "true";
BA_ "Unavailable_Value" SG_ 1146 FrontWiperStatus_BCM "0b11";
BA_ "Unavailable_Value" SG_ 1146 TrailerPresence "0b0";
BA_ "Event" SG_ 1146 FrontWipingRequest "true";
BA_ "Event" SG_ 1146 FrontWipingRequest "true";
BA_ "Event" SG_ 1146 FrontWipingRequest "true";
BA_ "Event" SG_ 1146 FrontWipingRequest "true";
BA_ "Event" SG_ 1146 FrontWipingRequest "true";
BA_ "Unavailable_Value" SG_ 1146 FrontWipingRequest "0b100";
BA_ "Unavailable_Value" SG_ 1146 LightSensorStatus "0b0";
BA_ "Unavailable_Value" SG_ 1146 RainStatus "0b11";
BA_ "Event" SG_ 1146 ClutchSwitchMaximumTravel "true";
BA_ "Event" SG_ 1146 ClutchSwitchMaximumTravel "true";
BA_ "Event" SG_ 1146 ClutchSwitchMaximumTravel "true";
BA_ "Event" SG_ 1146 ClutchSwitchMaximumTravel "true";
BA_ "Unavailable_Value" SG_ 1146 ClutchSwitchMaximumTravel "0b11";
BA_ "Unavailable_Value" SG_ 1147 OilPressureWarning_ECM "0b0";
BA_ "Unavailable_Value" SG_ 1147 WarningWaterTemp "0b0";
BA_ "Unavailable_Value" SG_ 1147 FuelConsumption "0x00";
BA_ "Event" SG_ 1150 SET_PositionInLane_State "true";
BA_ "Event" SG_ 1150 SET_PositionInLane_State "true";
BA_ "Event" SG_ 1150 SET_PositionInLane_State "true";
BA_ "Event" SG_ 1150 SET_PositionInLane_State "true";
BA_ "Unavailable_Value" SG_ 1150 SET_PositionInLane_State "null";
BA_ "Event" SG_ 1150 SET_VoiceGuidance_State "true";
BA_ "Event" SG_ 1150 SET_VoiceGuidance_State "true";
BA_ "Event" SG_ 1150 SET_VoiceGuidance_State "true";
BA_ "Event" SG_ 1150 SET_VoiceGuidance_State "true";
BA_ "Unavailable_Value" SG_ 1150 SET_VoiceGuidance_State "null";
BA_ "Event" SG_ 1150 SET_LaneChangeSwiftness_State "true";
BA_ "Event" SG_ 1150 SET_LaneChangeSwiftness_State "true";
BA_ "Event" SG_ 1150 SET_LaneChangeSwiftness_State "true";
BA_ "Event" SG_ 1150 SET_LaneChangeSwiftness_State "true";
BA_ "Unavailable_Value" SG_ 1150 SET_LaneChangeSwiftness_State "null";
BA_ "Event" SG_ 1150 SET_NavigatDriveAssist_State "true";
BA_ "Event" SG_ 1150 SET_NavigatDriveAssist_State "true";
BA_ "Event" SG_ 1150 SET_NavigatDriveAssist_State "true";
BA_ "Event" SG_ 1150 SET_NavigatDriveAssist_State "true";
BA_ "Unavailable_Value" SG_ 1150 SET_NavigatDriveAssist_State "null";
BA_ "Event" SG_ 1150 SET_OvertakeRelatSpeed_State "true";
BA_ "Event" SG_ 1150 SET_OvertakeRelatSpeed_State "true";
BA_ "Event" SG_ 1150 SET_OvertakeRelatSpeed_State "true";
BA_ "Event" SG_ 1150 SET_OvertakeRelatSpeed_State "true";
BA_ "Unavailable_Value" SG_ 1150 SET_OvertakeRelatSpeed_State "null";
BA_ "Event" SG_ 1150 SET_OvertakingAssist_State "true";
BA_ "Event" SG_ 1150 SET_OvertakingAssist_State "true";
BA_ "Event" SG_ 1150 SET_OvertakingAssist_State "true";
BA_ "Event" SG_ 1150 SET_OvertakingAssist_State "true";
BA_ "Unavailable_Value" SG_ 1150 SET_OvertakingAssist_State "null";
BA_ "Event" SG_ 1150 SET_Acceleration_State "true";
BA_ "Event" SG_ 1150 SET_Acceleration_State "true";
BA_ "Event" SG_ 1150 SET_Acceleration_State "true";
BA_ "Event" SG_ 1150 SET_Acceleration_State "true";
BA_ "Unavailable_Value" SG_ 1150 SET_Acceleration_State "null";
BA_ "Event" SG_ 1150 SET_ALCActivationByTSIG_State "true";
BA_ "Event" SG_ 1150 SET_ALCActivationByTSIG_State "true";
BA_ "Event" SG_ 1150 SET_ALCActivationByTSIG_State "true";
BA_ "Event" SG_ 1150 SET_ALCActivationByTSIG_State "true";
BA_ "Unavailable_Value" SG_ 1150 SET_ALCActivationByTSIG_State "null";
BA_ "Event" SG_ 1150 SET_CornerSpeedLevel_State "true";
BA_ "Event" SG_ 1150 SET_CornerSpeedLevel_State "true";
BA_ "Event" SG_ 1150 SET_CornerSpeedLevel_State "true";
BA_ "Event" SG_ 1150 SET_CornerSpeedLevel_State "true";
BA_ "Unavailable_Value" SG_ 1150 SET_CornerSpeedLevel_State "null";
BA_ "Event" SG_ 1150 SET_Deceleration_State "true";
BA_ "Event" SG_ 1150 SET_Deceleration_State "true";
BA_ "Event" SG_ 1150 SET_Deceleration_State "true";
BA_ "Event" SG_ 1150 SET_Deceleration_State "true";
BA_ "Unavailable_Value" SG_ 1150 SET_Deceleration_State "null";
BA_ "Event" SG_ 1150 ADL3_DisclaimerRepetitionRequest "true";
BA_ "Event" SG_ 1150 ADL3_DisclaimerRepetitionRequest "true";
BA_ "Event" SG_ 1150 ADL3_DisclaimerRepetitionRequest "true";
BA_ "Event" SG_ 1150 ADL3_DisclaimerRepetitionRequest "true";
BA_ "Unavailable_Value" SG_ 1150 ADL3_DisclaimerRepetitionRequest "0b0";
BA_ "Event" SG_ 1150 SET_ADL3Activation_State "true";
BA_ "Event" SG_ 1150 SET_ADL3Activation_State "true";
BA_ "Event" SG_ 1150 SET_ADL3Activation_State "true";
BA_ "Event" SG_ 1150 SET_ADL3Activation_State "true";
BA_ "Unavailable_Value" SG_ 1150 SET_ADL3Activation_State "0b00";
BA_ "Event" SG_ 1150 SET_AD_HandsOff_State "true";
BA_ "Event" SG_ 1150 SET_AD_HandsOff_State "true";
BA_ "Event" SG_ 1150 SET_AD_HandsOff_State "true";
BA_ "Event" SG_ 1150 SET_AD_HandsOff_State "true";
BA_ "Unavailable_Value" SG_ 1150 SET_AD_HandsOff_State "0b00";
BA_ "Event" SG_ 1150 SET_ALC_AssistMode_State "true";
BA_ "Event" SG_ 1150 SET_ALC_AssistMode_State "true";
BA_ "Event" SG_ 1150 SET_ALC_AssistMode_State "true";
BA_ "Event" SG_ 1150 SET_ALC_AssistMode_State "true";
BA_ "Unavailable_Value" SG_ 1150 SET_ALC_AssistMode_State "0b00";
BA_ "Unavailable_Value" SG_ 1172 EcoNavRechargeDuringTrip "0b000";
BA_ "Unavailable_Value" SG_ 1172 RST_GearShiftBuzzerActivRequest "0b00";
BA_ "Unavailable_Value" SG_ 1172 SC_SmartchargingActivationStatus "0b11";
BA_ "Unavailable_Value" SG_ 1172 SC_PresoakActivationStatus "0b11";
BA_ "Unavailable_Value" SG_ 1202 MemoParkStatusDisplayRequest "null";
BA_ "Unavailable_Value" SG_ 1202 MemoParkPositionIDDisplayRequest "0x00";
BA_ "Event" SG_ 1202 FAPK_ManeuverType_ParkOut "true";
BA_ "Event" SG_ 1202 FAPK_ManeuverType_ParkOut "true";
BA_ "Event" SG_ 1202 FAPK_ManeuverType_ParkOut "true";
BA_ "Event" SG_ 1202 FAPK_ManeuverType_ParkOut "true";
BA_ "Unavailable_Value" SG_ 1202 FAPK_ManeuverType_ParkOut "0b11";
BA_ "Event" SG_ 1202 FAPK_ManeuverType_Parallel "true";
BA_ "Event" SG_ 1202 FAPK_ManeuverType_Parallel "true";
BA_ "Event" SG_ 1202 FAPK_ManeuverType_Parallel "true";
BA_ "Event" SG_ 1202 FAPK_ManeuverType_Parallel "true";
BA_ "Unavailable_Value" SG_ 1202 FAPK_ManeuverType_Parallel "0b11";
BA_ "Event" SG_ 1202 FAPK_ManeuverType_AutoMode "true";
BA_ "Event" SG_ 1202 FAPK_ManeuverType_AutoMode "true";
BA_ "Event" SG_ 1202 FAPK_ManeuverType_AutoMode "true";
BA_ "Event" SG_ 1202 FAPK_ManeuverType_AutoMode "true";
BA_ "Unavailable_Value" SG_ 1202 FAPK_ManeuverType_AutoMode "0b11";
BA_ "Event" SG_ 1202 FAPK_ManeuverType_Angular "true";
BA_ "Event" SG_ 1202 FAPK_ManeuverType_Angular "true";
BA_ "Event" SG_ 1202 FAPK_ManeuverType_Angular "true";
BA_ "Event" SG_ 1202 FAPK_ManeuverType_Angular "true";
BA_ "Unavailable_Value" SG_ 1202 FAPK_ManeuverType_Angular "0b11";
BA_ "Event" SG_ 1202 FAPK_ManeuverType_Perpendicular "true";
BA_ "Event" SG_ 1202 FAPK_ManeuverType_Perpendicular "true";
BA_ "Event" SG_ 1202 FAPK_ManeuverType_Perpendicular "true";
BA_ "Event" SG_ 1202 FAPK_ManeuverType_Perpendicular "true";
BA_ "Unavailable_Value" SG_ 1202 FAPK_ManeuverType_Perpendicular "0b11";
BA_ "Unavailable_Value" SG_ 1203 OSPSpeedLimit "0xFF";
BA_ "Event" SG_ 1234 Map_Matched_Longitude "true";
BA_ "Event" SG_ 1234 Map_Matched_Longitude "true";
BA_ "Event" SG_ 1234 Map_Matched_Longitude "true";
BA_ "Event" SG_ 1234 Map_Matched_Longitude "true";
BA_ "Unavailable_Value" SG_ 1234 Map_Matched_Longitude "0xFFFF";
BA_ "Event" SG_ 1234 Map_Matched_Latitude "true";
BA_ "Event" SG_ 1234 Map_Matched_Latitude "true";
BA_ "Event" SG_ 1234 Map_Matched_Latitude "true";
BA_ "Event" SG_ 1234 Map_Matched_Latitude "true";
BA_ "Unavailable_Value" SG_ 1234 Map_Matched_Latitude "0xFFFF";
BA_ "Event" SG_ 1234 Map_Matched_Orientation "true";
BA_ "Event" SG_ 1234 Map_Matched_Orientation "true";
BA_ "Event" SG_ 1234 Map_Matched_Orientation "true";
BA_ "Event" SG_ 1234 Map_Matched_Orientation "true";
BA_ "Unavailable_Value" SG_ 1234 Map_Matched_Orientation "0x1FF";
BA_ "Event" SG_ 1234 Map_Matched_Accuracy "true";
BA_ "Event" SG_ 1234 Map_Matched_Accuracy "true";
BA_ "Event" SG_ 1234 Map_Matched_Accuracy "true";
BA_ "Event" SG_ 1234 Map_Matched_Accuracy "true";
BA_ "Unavailable_Value" SG_ 1234 Map_Matched_Accuracy "0x1FF";
BA_ "Event" SG_ 1234 ParkEndPositionID "true";
BA_ "Event" SG_ 1234 ParkEndPositionID "true";
BA_ "Event" SG_ 1234 ParkEndPositionID "true";
BA_ "Event" SG_ 1234 ParkEndPositionID "true";
BA_ "Unavailable_Value" SG_ 1234 ParkEndPositionID "0x00";
BA_ "Unavailable_Value" SG_ 1252 NominalFuelConsumption "0xFF";
BA_ "Unavailable_Value" SG_ 1276 BCI_ActivationState "0b0";
BA_ "Unavailable_Value" SG_ 1276 ACC_Status_Slow "0xF";
BA_ "Event" SG_ 1282 SonarSystemPauseStatus "true";
BA_ "Event" SG_ 1282 SonarSystemPauseStatus "true";
BA_ "Event" SG_ 1282 SonarSystemPauseStatus "true";
BA_ "Event" SG_ 1282 SonarSystemPauseStatus "true";
BA_ "Unavailable_Value" SG_ 1282 SonarSystemPauseStatus "0b0";
BA_ "Event" SG_ 1282 ParkAssistSensitivityStatus "true";
BA_ "Event" SG_ 1282 ParkAssistSensitivityStatus "true";
BA_ "Event" SG_ 1282 ParkAssistSensitivityStatus "true";
BA_ "Event" SG_ 1282 ParkAssistSensitivityStatus "true";
BA_ "Unavailable_Value" SG_ 1282 ParkAssistSensitivityStatus "0b00";
BA_ "Event" SG_ 1282 FrontParkAssistState "true";
BA_ "Event" SG_ 1282 FrontParkAssistState "true";
BA_ "Event" SG_ 1282 FrontParkAssistState "true";
BA_ "Event" SG_ 1282 FrontParkAssistState "true";
BA_ "Unavailable_Value" SG_ 1282 FrontParkAssistState "0b0";
BA_ "Event" SG_ 1282 RearParkAssistState "true";
BA_ "Event" SG_ 1282 RearParkAssistState "true";
BA_ "Event" SG_ 1282 RearParkAssistState "true";
BA_ "Event" SG_ 1282 RearParkAssistState "true";
BA_ "Unavailable_Value" SG_ 1282 RearParkAssistState "0b0";
BA_ "Event" SG_ 1282 SonarAutoDisplayState "true";
BA_ "Event" SG_ 1282 SonarAutoDisplayState "true";
BA_ "Event" SG_ 1282 SonarAutoDisplayState "true";
BA_ "Event" SG_ 1282 SonarAutoDisplayState "true";
BA_ "Unavailable_Value" SG_ 1282 SonarAutoDisplayState "0b00";
BA_ "Event" SG_ 1292 RST_TrackSettings "true";
BA_ "Event" SG_ 1292 RST_TrackSettings "true";
BA_ "Event" SG_ 1292 RST_TrackSettings "true";
BA_ "Event" SG_ 1292 RST_TrackSettings "true";
BA_ "Unavailable_Value" SG_ 1292 RST_TrackSettings "0b0";
BA_ "Event" SG_ 1292 BrakePedalLevelRequest "true";
BA_ "Event" SG_ 1292 BrakePedalLevelRequest "true";
BA_ "Event" SG_ 1292 BrakePedalLevelRequest "true";
BA_ "Event" SG_ 1292 BrakePedalLevelRequest "true";
BA_ "Unavailable_Value" SG_ 1292 BrakePedalLevelRequest "0b111";
BA_ "Event" SG_ 1294 VirtualKeyMenuState "true";
BA_ "Event" SG_ 1294 VirtualKeyMenuState "true";
BA_ "Event" SG_ 1294 VirtualKeyMenuState "true";
BA_ "Event" SG_ 1294 VirtualKeyMenuState "true";
BA_ "Event" SG_ 1295 SET_ALCP2P_AlertLevel_Request2 "true";
BA_ "Event" SG_ 1295 SET_ALCP2P_AlertLevel_Request2 "true";
BA_ "Event" SG_ 1295 SET_ALCP2P_AlertLevel_Request2 "true";
BA_ "Event" SG_ 1295 SET_ALCP2P_AlertLevel_Request2 "true";
BA_ "Unavailable_Value" SG_ 1295 SET_ALCP2P_AlertLevel_Request2 "0b000";
BA_ "Event" SG_ 1295 HVbatteryCoolingActivationReq2 "true";
BA_ "Event" SG_ 1295 HVbatteryCoolingActivationReq2 "true";
BA_ "Event" SG_ 1295 HVbatteryCoolingActivationReq2 "true";
BA_ "Event" SG_ 1295 HVbatteryCoolingActivationReq2 "true";
BA_ "Unavailable_Value" SG_ 1295 HVbatteryCoolingActivationReq2 "0b00";
BA_ "Event" SG_ 1295 SET_AD_HandsOff_Request2 "true";
BA_ "Event" SG_ 1295 SET_AD_HandsOff_Request2 "true";
BA_ "Event" SG_ 1295 SET_AD_HandsOff_Request2 "true";
BA_ "Event" SG_ 1295 SET_AD_HandsOff_Request2 "true";
BA_ "Unavailable_Value" SG_ 1295 SET_AD_HandsOff_Request2 "0b00";
BA_ "Event" SG_ 1295 SET_ALC_AssistMode_Request2 "true";
BA_ "Event" SG_ 1295 SET_ALC_AssistMode_Request2 "true";
BA_ "Event" SG_ 1295 SET_ALC_AssistMode_Request2 "true";
BA_ "Event" SG_ 1295 SET_ALC_AssistMode_Request2 "true";
BA_ "Unavailable_Value" SG_ 1295 SET_ALC_AssistMode_Request2 "0b00";
BA_ "Event" SG_ 1295 V2G_ServiceActivationRequest "true";
BA_ "Event" SG_ 1295 V2G_ServiceActivationRequest "true";
BA_ "Event" SG_ 1295 V2G_ServiceActivationRequest "true";
BA_ "Event" SG_ 1295 V2G_ServiceActivationRequest "true";
BA_ "Unavailable_Value" SG_ 1295 V2G_ServiceActivationRequest "0b00";
BA_ "Event" SG_ 1295 SET_ADL3Activation_Request2 "true";
BA_ "Event" SG_ 1295 SET_ADL3Activation_Request2 "true";
BA_ "Event" SG_ 1295 SET_ADL3Activation_Request2 "true";
BA_ "Event" SG_ 1295 SET_ADL3Activation_Request2 "true";
BA_ "Unavailable_Value" SG_ 1295 SET_ADL3Activation_Request2 "0b00";
BA_ "Event" SG_ 1296 IVI_SafeMode "true";
BA_ "Event" SG_ 1296 IVI_SafeMode "true";
BA_ "Event" SG_ 1296 IVI_SafeMode "true";
BA_ "Event" SG_ 1296 IVI_SafeMode "true";
BA_ "Event" SG_ 1296 IVI_SafeModePersistentON "true";
BA_ "Event" SG_ 1296 IVI_SafeModePersistentON "true";
BA_ "Event" SG_ 1296 IVI_SafeModePersistentON "true";
BA_ "Event" SG_ 1296 IVI_SafeModePersistentON "true";
BA_ "Event" SG_ 1296 IVI_SafeModeRebootReason "true";
BA_ "Event" SG_ 1296 IVI_SafeModeRebootReason "true";
BA_ "Event" SG_ 1296 IVI_SafeModeRebootReason "true";
BA_ "Event" SG_ 1296 IVI_SafeModeRebootReason "true";
BA_ "Event" SG_ 1299 FKP_ObstacleZone_RF "true";
BA_ "Event" SG_ 1299 FKP_ObstacleZone_RF "true";
BA_ "Event" SG_ 1299 FKP_ObstacleZone_RF "true";
BA_ "Event" SG_ 1299 FKP_ObstacleZone_RF "true";
BA_ "Unavailable_Value" SG_ 1299 FKP_ObstacleZone_RF "0b00";
BA_ "Event" SG_ 1299 FKP_ObstacleZone_LRC "true";
BA_ "Event" SG_ 1299 FKP_ObstacleZone_LRC "true";
BA_ "Event" SG_ 1299 FKP_ObstacleZone_LRC "true";
BA_ "Event" SG_ 1299 FKP_ObstacleZone_LRC "true";
BA_ "Unavailable_Value" SG_ 1299 FKP_ObstacleZone_LRC "0b00";
BA_ "Event" SG_ 1299 FKP_ObstacleZone_LFC "true";
BA_ "Event" SG_ 1299 FKP_ObstacleZone_LFC "true";
BA_ "Event" SG_ 1299 FKP_ObstacleZone_LFC "true";
BA_ "Event" SG_ 1299 FKP_ObstacleZone_LFC "true";
BA_ "Unavailable_Value" SG_ 1299 FKP_ObstacleZone_LFC "0b00";
BA_ "Event" SG_ 1299 FKP_ObstacleZone_LF "true";
BA_ "Event" SG_ 1299 FKP_ObstacleZone_LF "true";
BA_ "Event" SG_ 1299 FKP_ObstacleZone_LF "true";
BA_ "Event" SG_ 1299 FKP_ObstacleZone_LF "true";
BA_ "Unavailable_Value" SG_ 1299 FKP_ObstacleZone_LF "0b00";
BA_ "Event" SG_ 1299 FKP_ObstacleZone_RRC "true";
BA_ "Event" SG_ 1299 FKP_ObstacleZone_RRC "true";
BA_ "Event" SG_ 1299 FKP_ObstacleZone_RRC "true";
BA_ "Event" SG_ 1299 FKP_ObstacleZone_RRC "true";
BA_ "Unavailable_Value" SG_ 1299 FKP_ObstacleZone_RRC "0b00";
BA_ "Event" SG_ 1299 FKP_ObstacleZone_RR "true";
BA_ "Event" SG_ 1299 FKP_ObstacleZone_RR "true";
BA_ "Event" SG_ 1299 FKP_ObstacleZone_RR "true";
BA_ "Event" SG_ 1299 FKP_ObstacleZone_RR "true";
BA_ "Unavailable_Value" SG_ 1299 FKP_ObstacleZone_RR "0b00";
BA_ "Event" SG_ 1299 FKP_ObstacleZone_RL "true";
BA_ "Event" SG_ 1299 FKP_ObstacleZone_RL "true";
BA_ "Event" SG_ 1299 FKP_ObstacleZone_RL "true";
BA_ "Event" SG_ 1299 FKP_ObstacleZone_RL "true";
BA_ "Unavailable_Value" SG_ 1299 FKP_ObstacleZone_RL "0b00";
BA_ "Event" SG_ 1299 FKP_ObstacleZone_RFC "true";
BA_ "Event" SG_ 1299 FKP_ObstacleZone_RFC "true";
BA_ "Event" SG_ 1299 FKP_ObstacleZone_RFC "true";
BA_ "Event" SG_ 1299 FKP_ObstacleZone_RFC "true";
BA_ "Unavailable_Value" SG_ 1299 FKP_ObstacleZone_RFC "0b00";
BA_ "Event" SG_ 1299 FKP_FrontMiddleL_Scan "true";
BA_ "Event" SG_ 1299 FKP_FrontMiddleL_Scan "true";
BA_ "Event" SG_ 1299 FKP_FrontMiddleL_Scan "true";
BA_ "Event" SG_ 1299 FKP_FrontMiddleL_Scan "true";
BA_ "Unavailable_Value" SG_ 1299 FKP_FrontMiddleL_Scan "0b0";
BA_ "Event" SG_ 1299 FKP_FrontMiddleR_Hatch "true";
BA_ "Event" SG_ 1299 FKP_FrontMiddleR_Hatch "true";
BA_ "Event" SG_ 1299 FKP_FrontMiddleR_Hatch "true";
BA_ "Event" SG_ 1299 FKP_FrontMiddleR_Hatch "true";
BA_ "Unavailable_Value" SG_ 1299 FKP_FrontMiddleR_Hatch "0b0";
BA_ "Event" SG_ 1299 FKP_FrontMiddleL_Hatch "true";
BA_ "Event" SG_ 1299 FKP_FrontMiddleL_Hatch "true";
BA_ "Event" SG_ 1299 FKP_FrontMiddleL_Hatch "true";
BA_ "Event" SG_ 1299 FKP_FrontMiddleL_Hatch "true";
BA_ "Unavailable_Value" SG_ 1299 FKP_FrontMiddleL_Hatch "0b0";
BA_ "Event" SG_ 1299 FKP_FrontFrontR_Scan "true";
BA_ "Event" SG_ 1299 FKP_FrontFrontR_Scan "true";
BA_ "Event" SG_ 1299 FKP_FrontFrontR_Scan "true";
BA_ "Event" SG_ 1299 FKP_FrontFrontR_Scan "true";
BA_ "Unavailable_Value" SG_ 1299 FKP_FrontFrontR_Scan "0b0";
BA_ "Event" SG_ 1299 FKP_FrontFrontR_Hatch "true";
BA_ "Event" SG_ 1299 FKP_FrontFrontR_Hatch "true";
BA_ "Event" SG_ 1299 FKP_FrontFrontR_Hatch "true";
BA_ "Event" SG_ 1299 FKP_FrontFrontR_Hatch "true";
BA_ "Unavailable_Value" SG_ 1299 FKP_FrontFrontR_Hatch "0b0";
BA_ "Event" SG_ 1299 FKP_FrontFrontL_Scan "true";
BA_ "Event" SG_ 1299 FKP_FrontFrontL_Scan "true";
BA_ "Event" SG_ 1299 FKP_FrontFrontL_Scan "true";
BA_ "Event" SG_ 1299 FKP_FrontFrontL_Scan "true";
BA_ "Unavailable_Value" SG_ 1299 FKP_FrontFrontL_Scan "0b0";
BA_ "Event" SG_ 1299 FKP_ImageDisplayRequest "true";
BA_ "Event" SG_ 1299 FKP_ImageDisplayRequest "true";
BA_ "Event" SG_ 1299 FKP_ImageDisplayRequest "true";
BA_ "Event" SG_ 1299 FKP_ImageDisplayRequest "true";
BA_ "Unavailable_Value" SG_ 1299 FKP_ImageDisplayRequest "0b0";
BA_ "Event" SG_ 1299 FKP_FrontMiddleR_Scan "true";
BA_ "Event" SG_ 1299 FKP_FrontMiddleR_Scan "true";
BA_ "Event" SG_ 1299 FKP_FrontMiddleR_Scan "true";
BA_ "Event" SG_ 1299 FKP_FrontMiddleR_Scan "true";
BA_ "Unavailable_Value" SG_ 1299 FKP_FrontMiddleR_Scan "0b0";
BA_ "Event" SG_ 1299 FKP_RearRearR_Scan "true";
BA_ "Event" SG_ 1299 FKP_RearRearR_Scan "true";
BA_ "Event" SG_ 1299 FKP_RearRearR_Scan "true";
BA_ "Event" SG_ 1299 FKP_RearRearR_Scan "true";
BA_ "Unavailable_Value" SG_ 1299 FKP_RearRearR_Scan "0b0";
BA_ "Event" SG_ 1299 FKP_RearRearR_Hatch "true";
BA_ "Event" SG_ 1299 FKP_RearRearR_Hatch "true";
BA_ "Event" SG_ 1299 FKP_RearRearR_Hatch "true";
BA_ "Event" SG_ 1299 FKP_RearRearR_Hatch "true";
BA_ "Unavailable_Value" SG_ 1299 FKP_RearRearR_Hatch "0b0";
BA_ "Event" SG_ 1299 FKP_RearRearL_Scan "true";
BA_ "Event" SG_ 1299 FKP_RearRearL_Scan "true";
BA_ "Event" SG_ 1299 FKP_RearRearL_Scan "true";
BA_ "Event" SG_ 1299 FKP_RearRearL_Scan "true";
BA_ "Unavailable_Value" SG_ 1299 FKP_RearRearL_Scan "0b0";
BA_ "Event" SG_ 1299 FKP_RearRearL_Hatch "true";
BA_ "Event" SG_ 1299 FKP_RearRearL_Hatch "true";
BA_ "Event" SG_ 1299 FKP_RearRearL_Hatch "true";
BA_ "Event" SG_ 1299 FKP_RearRearL_Hatch "true";
BA_ "Unavailable_Value" SG_ 1299 FKP_RearRearL_Hatch "0b0";
BA_ "Event" SG_ 1299 FKP_RearMiddleR_Scan "true";
BA_ "Event" SG_ 1299 FKP_RearMiddleR_Scan "true";
BA_ "Event" SG_ 1299 FKP_RearMiddleR_Scan "true";
BA_ "Event" SG_ 1299 FKP_RearMiddleR_Scan "true";
BA_ "Unavailable_Value" SG_ 1299 FKP_RearMiddleR_Scan "0b0";
BA_ "Event" SG_ 1299 FKP_RearMiddleR_Hatch "true";
BA_ "Event" SG_ 1299 FKP_RearMiddleR_Hatch "true";
BA_ "Event" SG_ 1299 FKP_RearMiddleR_Hatch "true";
BA_ "Event" SG_ 1299 FKP_RearMiddleR_Hatch "true";
BA_ "Unavailable_Value" SG_ 1299 FKP_RearMiddleR_Hatch "0b0";
BA_ "Event" SG_ 1299 FKP_RearMiddleL_Scan "true";
BA_ "Event" SG_ 1299 FKP_RearMiddleL_Scan "true";
BA_ "Event" SG_ 1299 FKP_RearMiddleL_Scan "true";
BA_ "Event" SG_ 1299 FKP_RearMiddleL_Scan "true";
BA_ "Unavailable_Value" SG_ 1299 FKP_RearMiddleL_Scan "0b0";
BA_ "Event" SG_ 1299 FKP_RearMiddleL_Hatch "true";
BA_ "Event" SG_ 1299 FKP_RearMiddleL_Hatch "true";
BA_ "Event" SG_ 1299 FKP_RearMiddleL_Hatch "true";
BA_ "Event" SG_ 1299 FKP_RearMiddleL_Hatch "true";
BA_ "Unavailable_Value" SG_ 1299 FKP_RearMiddleL_Hatch "0b0";
BA_ "Event" SG_ 1299 FKP_FrontFrontL_Hatch "true";
BA_ "Event" SG_ 1299 FKP_FrontFrontL_Hatch "true";
BA_ "Event" SG_ 1299 FKP_FrontFrontL_Hatch "true";
BA_ "Event" SG_ 1299 FKP_FrontFrontL_Hatch "true";
BA_ "Unavailable_Value" SG_ 1299 FKP_FrontFrontL_Hatch "0b0";
BA_ "Event" SG_ 1299 UPA_RearRight_Hatch "true";
BA_ "Event" SG_ 1299 UPA_RearRight_Hatch "true";
BA_ "Event" SG_ 1299 UPA_RearRight_Hatch "true";
BA_ "Event" SG_ 1299 UPA_RearRight_Hatch "true";
BA_ "Unavailable_Value" SG_ 1299 UPA_RearRight_Hatch "0b0";
BA_ "Event" SG_ 1299 UPA_RearMiddle_Hatch "true";
BA_ "Event" SG_ 1299 UPA_RearMiddle_Hatch "true";
BA_ "Event" SG_ 1299 UPA_RearMiddle_Hatch "true";
BA_ "Event" SG_ 1299 UPA_RearMiddle_Hatch "true";
BA_ "Unavailable_Value" SG_ 1299 UPA_RearMiddle_Hatch "0b0";
BA_ "Event" SG_ 1299 UPA_RearLeft_Hatch "true";
BA_ "Event" SG_ 1299 UPA_RearLeft_Hatch "true";
BA_ "Event" SG_ 1299 UPA_RearLeft_Hatch "true";
BA_ "Event" SG_ 1299 UPA_RearLeft_Hatch "true";
BA_ "Unavailable_Value" SG_ 1299 UPA_RearLeft_Hatch "0b0";
BA_ "Event" SG_ 1299 UPA_FrontRight_Hatch "true";
BA_ "Event" SG_ 1299 UPA_FrontRight_Hatch "true";
BA_ "Event" SG_ 1299 UPA_FrontRight_Hatch "true";
BA_ "Event" SG_ 1299 UPA_FrontRight_Hatch "true";
BA_ "Unavailable_Value" SG_ 1299 UPA_FrontRight_Hatch "0b0";
BA_ "Event" SG_ 1299 UPA_FrontMiddle_Hatch "true";
BA_ "Event" SG_ 1299 UPA_FrontMiddle_Hatch "true";
BA_ "Event" SG_ 1299 UPA_FrontMiddle_Hatch "true";
BA_ "Event" SG_ 1299 UPA_FrontMiddle_Hatch "true";
BA_ "Unavailable_Value" SG_ 1299 UPA_FrontMiddle_Hatch "0b0";
BA_ "Event" SG_ 1299 UPA_FrontLeft_Hatch "true";
BA_ "Event" SG_ 1299 UPA_FrontLeft_Hatch "true";
BA_ "Event" SG_ 1299 UPA_FrontLeft_Hatch "true";
BA_ "Event" SG_ 1299 UPA_FrontLeft_Hatch "true";
BA_ "Unavailable_Value" SG_ 1299 UPA_FrontLeft_Hatch "0b0";
BA_ "Event" SG_ 1299 FKP_ActivationStatus "true";
BA_ "Event" SG_ 1299 FKP_ActivationStatus "true";
BA_ "Event" SG_ 1299 FKP_ActivationStatus "true";
BA_ "Event" SG_ 1299 FKP_ActivationStatus "true";
BA_ "Unavailable_Value" SG_ 1299 FKP_ActivationStatus "0b0";
BA_ "Event" SG_ 1303 RainSymbolDisplayRequest "true";
BA_ "Event" SG_ 1303 RainSymbolDisplayRequest "true";
BA_ "Event" SG_ 1303 RainSymbolDisplayRequest "true";
BA_ "Event" SG_ 1303 RainSymbolDisplayRequest "true";
BA_ "Unavailable_Value" SG_ 1303 RainSymbolDisplayRequest "0b0";
BA_ "Event" SG_ 1303 TSR_OSP_SpeedSignalZone1 "true";
BA_ "Event" SG_ 1303 TSR_OSP_SpeedSignalZone1 "true";
BA_ "Event" SG_ 1303 TSR_OSP_SpeedSignalZone1 "true";
BA_ "Event" SG_ 1303 TSR_OSP_SpeedSignalZone1 "true";
BA_ "Unavailable_Value" SG_ 1303 TSR_OSP_SpeedSignalZone1 "0xFF";
BA_ "Event" SG_ 1303 TSR_OSP_ActivationStatus "true";
BA_ "Event" SG_ 1303 TSR_OSP_ActivationStatus "true";
BA_ "Event" SG_ 1303 TSR_OSP_ActivationStatus "true";
BA_ "Event" SG_ 1303 TSR_OSP_ActivationStatus "true";
BA_ "Unavailable_Value" SG_ 1303 TSR_OSP_ActivationStatus "0b00";
BA_ "Event" SG_ 1303 OSPOverSpeedDisplayRequest "true";
BA_ "Event" SG_ 1303 OSPOverSpeedDisplayRequest "true";
BA_ "Event" SG_ 1303 OSPOverSpeedDisplayRequest "true";
BA_ "Event" SG_ 1303 OSPOverSpeedDisplayRequest "true";
BA_ "Unavailable_Value" SG_ 1303 OSPOverSpeedDisplayRequest "0b0";
BA_ "Event" SG_ 1310 CartoData "true";
BA_ "Event" SG_ 1310 CartoData "true";
BA_ "Event" SG_ 1310 CartoData "true";
BA_ "Event" SG_ 1310 CartoData "true";
BA_ "Unavailable_Value" SG_ 1310 CartoData "null";
BA_ "Unavailable_Value" SG_ 1310 OSPDataType "0b110";
BA_ "Unavailable_Value" SG_ 1315 AbsoluteTimeSince1rstIgnition "0xFFFFFF";
BA_ "Event" SG_ 1318 RESPreSoak_ProgValue_MMI "true";
BA_ "Event" SG_ 1318 RESPreSoak_ProgValue_MMI "true";
BA_ "Event" SG_ 1318 RESPreSoak_ProgValue_MMI "true";
BA_ "Event" SG_ 1318 RESPreSoak_ProgValue_MMI "true";
BA_ "Unavailable_Value" SG_ 1318 RESPreSoak_ProgValue_MMI "0x7FF";
BA_ "Event" SG_ 1318 TripComputer_ResetRequest "true";
BA_ "Event" SG_ 1318 TripComputer_ResetRequest "true";
BA_ "Event" SG_ 1318 TripComputer_ResetRequest "true";
BA_ "Event" SG_ 1318 TripComputer_ResetRequest "true";
BA_ "Unavailable_Value" SG_ 1318 TripComputer_ResetRequest "0b0";
BA_ "Event" SG_ 1318 LDW_SoundLevelState_v2 "true";
BA_ "Event" SG_ 1318 LDW_SoundLevelState_v2 "true";
BA_ "Event" SG_ 1318 LDW_SoundLevelState_v2 "true";
BA_ "Event" SG_ 1318 LDW_SoundLevelState_v2 "true";
BA_ "Unavailable_Value" SG_ 1318 LDW_SoundLevelState_v2 "null";
BA_ "Unavailable_Value" SG_ 1318 VehicleSpeedbyGPS "0x3FFF";
BA_ "Event" SG_ 1318 RESPreSoak_ProgReq_MMI "true";
BA_ "Event" SG_ 1318 RESPreSoak_ProgReq_MMI "true";
BA_ "Event" SG_ 1318 RESPreSoak_ProgReq_MMI "true";
BA_ "Event" SG_ 1318 RESPreSoak_ProgReq_MMI "true";
BA_ "Unavailable_Value" SG_ 1318 RESPreSoak_ProgReq_MMI "0b11";
BA_ "Event" SG_ 1318 ESE_Soundvolume_Request "true";
BA_ "Event" SG_ 1318 ESE_Soundvolume_Request "true";
BA_ "Event" SG_ 1318 ESE_Soundvolume_Request "true";
BA_ "Event" SG_ 1318 ESE_Soundvolume_Request "true";
BA_ "Unavailable_Value" SG_ 1318 ESE_Soundvolume_Request "0x00";
BA_ "Event" SG_ 1318 HFP_SelectedManeuverTypeRequest "true";
BA_ "Event" SG_ 1318 HFP_SelectedManeuverTypeRequest "true";
BA_ "Event" SG_ 1318 HFP_SelectedManeuverTypeRequest "true";
BA_ "Event" SG_ 1318 HFP_SelectedManeuverTypeRequest "true";
BA_ "Unavailable_Value" SG_ 1318 HFP_SelectedManeuverTypeRequest "0b000";
BA_ "Event" SG_ 1318 ESE_Soundtype_Request "true";
BA_ "Event" SG_ 1318 ESE_Soundtype_Request "true";
BA_ "Event" SG_ 1318 ESE_Soundtype_Request "true";
BA_ "Event" SG_ 1318 ESE_Soundtype_Request "true";
BA_ "Unavailable_Value" SG_ 1318 ESE_Soundtype_Request "0x0";
BA_ "Event" SG_ 1319 ADL2_CurveWarningState "true";
BA_ "Event" SG_ 1319 ADL2_CurveWarningState "true";
BA_ "Event" SG_ 1319 ADL2_CurveWarningState "true";
BA_ "Event" SG_ 1319 ADL2_CurveWarningState "true";
BA_ "Unavailable_Value" SG_ 1319 ADL2_CurveWarningState "0x0";
BA_ "Event" SG_ 1319 ADL2L3_P2PFeatureState "true";
BA_ "Event" SG_ 1319 ADL2L3_P2PFeatureState "true";
BA_ "Event" SG_ 1319 ADL2L3_P2PFeatureState "true";
BA_ "Event" SG_ 1319 ADL2L3_P2PFeatureState "true";
BA_ "Unavailable_Value" SG_ 1319 ADL2L3_P2PFeatureState "0x0";
BA_ "Event" SG_ 1320 NAVI_curve_0 "true";
BA_ "Event" SG_ 1320 NAVI_curve_0 "true";
BA_ "Event" SG_ 1320 NAVI_curve_0 "true";
BA_ "Event" SG_ 1320 NAVI_curve_0 "true";
BA_ "Event" SG_ 1320 NAVI_curve_1 "true";
BA_ "Event" SG_ 1320 NAVI_curve_1 "true";
BA_ "Event" SG_ 1320 NAVI_curve_1 "true";
BA_ "Event" SG_ 1320 NAVI_curve_1 "true";
BA_ "Event" SG_ 1320 NAVI_curve_2 "true";
BA_ "Event" SG_ 1320 NAVI_curve_2 "true";
BA_ "Event" SG_ 1320 NAVI_curve_2 "true";
BA_ "Event" SG_ 1320 NAVI_curve_2 "true";
BA_ "Event" SG_ 1320 NAVI_curve_3 "true";
BA_ "Event" SG_ 1320 NAVI_curve_3 "true";
BA_ "Event" SG_ 1320 NAVI_curve_3 "true";
BA_ "Event" SG_ 1320 NAVI_curve_3 "true";
BA_ "Event" SG_ 1320 NAVI_curve_4 "true";
BA_ "Event" SG_ 1320 NAVI_curve_4 "true";
BA_ "Event" SG_ 1320 NAVI_curve_4 "true";
BA_ "Event" SG_ 1320 NAVI_curve_4 "true";
BA_ "Event" SG_ 1320 NAVI_curve_5 "true";
BA_ "Event" SG_ 1320 NAVI_curve_5 "true";
BA_ "Event" SG_ 1320 NAVI_curve_5 "true";
BA_ "Event" SG_ 1320 NAVI_curve_5 "true";
BA_ "Event" SG_ 1320 NAVI_curve_6 "true";
BA_ "Event" SG_ 1320 NAVI_curve_6 "true";
BA_ "Event" SG_ 1320 NAVI_curve_6 "true";
BA_ "Event" SG_ 1320 NAVI_curve_6 "true";
BA_ "Event" SG_ 1320 NAVI_Matching_RoutePlan "true";
BA_ "Event" SG_ 1320 NAVI_Matching_RoutePlan "true";
BA_ "Event" SG_ 1320 NAVI_Matching_RoutePlan "true";
BA_ "Event" SG_ 1320 NAVI_Matching_RoutePlan "true";
BA_ "Event" SG_ 1320 RoadData_UpdateCounter1 "true";
BA_ "Event" SG_ 1320 RoadData_UpdateCounter1 "true";
BA_ "Event" SG_ 1320 RoadData_UpdateCounter1 "true";
BA_ "Event" SG_ 1320 RoadData_UpdateCounter1 "true";
BA_ "Event" SG_ 1323 NAVI_curve_7 "true";
BA_ "Event" SG_ 1323 NAVI_curve_7 "true";
BA_ "Event" SG_ 1323 NAVI_curve_7 "true";
BA_ "Event" SG_ 1323 NAVI_curve_7 "true";
BA_ "Event" SG_ 1323 NAVI_curve_8 "true";
BA_ "Event" SG_ 1323 NAVI_curve_8 "true";
BA_ "Event" SG_ 1323 NAVI_curve_8 "true";
BA_ "Event" SG_ 1323 NAVI_curve_8 "true";
BA_ "Event" SG_ 1323 NAVI_curve_9 "true";
BA_ "Event" SG_ 1323 NAVI_curve_9 "true";
BA_ "Event" SG_ 1323 NAVI_curve_9 "true";
BA_ "Event" SG_ 1323 NAVI_curve_9 "true";
BA_ "Event" SG_ 1323 NAVI_curve_10 "true";
BA_ "Event" SG_ 1323 NAVI_curve_10 "true";
BA_ "Event" SG_ 1323 NAVI_curve_10 "true";
BA_ "Event" SG_ 1323 NAVI_curve_10 "true";
BA_ "Event" SG_ 1323 NAVI_curve_11 "true";
BA_ "Event" SG_ 1323 NAVI_curve_11 "true";
BA_ "Event" SG_ 1323 NAVI_curve_11 "true";
BA_ "Event" SG_ 1323 NAVI_curve_11 "true";
BA_ "Event" SG_ 1323 NAVI_curve_12 "true";
BA_ "Event" SG_ 1323 NAVI_curve_12 "true";
BA_ "Event" SG_ 1323 NAVI_curve_12 "true";
BA_ "Event" SG_ 1323 NAVI_curve_12 "true";
BA_ "Event" SG_ 1323 NAVI_curve_13 "true";
BA_ "Event" SG_ 1323 NAVI_curve_13 "true";
BA_ "Event" SG_ 1323 NAVI_curve_13 "true";
BA_ "Event" SG_ 1323 NAVI_curve_13 "true";
BA_ "Event" SG_ 1323 RoadData_UpdateCounter2 "true";
BA_ "Event" SG_ 1323 RoadData_UpdateCounter2 "true";
BA_ "Event" SG_ 1323 RoadData_UpdateCounter2 "true";
BA_ "Event" SG_ 1323 RoadData_UpdateCounter2 "true";
BA_ "Event" SG_ 1324 NAVI_curve_14 "true";
BA_ "Event" SG_ 1324 NAVI_curve_14 "true";
BA_ "Event" SG_ 1324 NAVI_curve_14 "true";
BA_ "Event" SG_ 1324 NAVI_curve_14 "true";
BA_ "Event" SG_ 1324 NAVI_curve_15 "true";
BA_ "Event" SG_ 1324 NAVI_curve_15 "true";
BA_ "Event" SG_ 1324 NAVI_curve_15 "true";
BA_ "Event" SG_ 1324 NAVI_curve_15 "true";
BA_ "Event" SG_ 1324 NAVI_curve_16 "true";
BA_ "Event" SG_ 1324 NAVI_curve_16 "true";
BA_ "Event" SG_ 1324 NAVI_curve_16 "true";
BA_ "Event" SG_ 1324 NAVI_curve_16 "true";
BA_ "Event" SG_ 1324 NAVI_curve_17 "true";
BA_ "Event" SG_ 1324 NAVI_curve_17 "true";
BA_ "Event" SG_ 1324 NAVI_curve_17 "true";
BA_ "Event" SG_ 1324 NAVI_curve_17 "true";
BA_ "Event" SG_ 1324 NAVI_curve_18 "true";
BA_ "Event" SG_ 1324 NAVI_curve_18 "true";
BA_ "Event" SG_ 1324 NAVI_curve_18 "true";
BA_ "Event" SG_ 1324 NAVI_curve_18 "true";
BA_ "Event" SG_ 1324 NAVI_curve_19 "true";
BA_ "Event" SG_ 1324 NAVI_curve_19 "true";
BA_ "Event" SG_ 1324 NAVI_curve_19 "true";
BA_ "Event" SG_ 1324 NAVI_curve_19 "true";
BA_ "Event" SG_ 1324 NAVI_curve_20 "true";
BA_ "Event" SG_ 1324 NAVI_curve_20 "true";
BA_ "Event" SG_ 1324 NAVI_curve_20 "true";
BA_ "Event" SG_ 1324 NAVI_curve_20 "true";
BA_ "Event" SG_ 1324 RoadData_UpdateCounter3 "true";
BA_ "Event" SG_ 1324 RoadData_UpdateCounter3 "true";
BA_ "Event" SG_ 1324 RoadData_UpdateCounter3 "true";
BA_ "Event" SG_ 1324 RoadData_UpdateCounter3 "true";
BA_ "Event" SG_ 1325 NAVI_DistanceToBranch "true";
BA_ "Event" SG_ 1325 NAVI_DistanceToBranch "true";
BA_ "Event" SG_ 1325 NAVI_DistanceToBranch "true";
BA_ "Event" SG_ 1325 NAVI_DistanceToBranch "true";
BA_ "Event" SG_ 1325 NAVI_BranchMultipleInfo "true";
BA_ "Event" SG_ 1325 NAVI_BranchMultipleInfo "true";
BA_ "Event" SG_ 1325 NAVI_BranchMultipleInfo "true";
BA_ "Event" SG_ 1325 NAVI_BranchMultipleInfo "true";
BA_ "Event" SG_ 1325 NAVI_BranchDirection "true";
BA_ "Event" SG_ 1325 NAVI_BranchDirection "true";
BA_ "Event" SG_ 1325 NAVI_BranchDirection "true";
BA_ "Event" SG_ 1325 NAVI_BranchDirection "true";
BA_ "Event" SG_ 1325 NAVI_CurveDirection "true";
BA_ "Event" SG_ 1325 NAVI_CurveDirection "true";
BA_ "Event" SG_ 1325 NAVI_CurveDirection "true";
BA_ "Event" SG_ 1325 NAVI_CurveDirection "true";
BA_ "Event" SG_ 1325 NaviGPS_PositioningStatus "true";
BA_ "Event" SG_ 1325 NaviGPS_PositioningStatus "true";
BA_ "Event" SG_ 1325 NaviGPS_PositioningStatus "true";
BA_ "Event" SG_ 1325 NaviGPS_PositioningStatus "true";
BA_ "Event" SG_ 1325 NAVI_Matching_Status "true";
BA_ "Event" SG_ 1325 NAVI_Matching_Status "true";
BA_ "Event" SG_ 1325 NAVI_Matching_Status "true";
BA_ "Event" SG_ 1325 NAVI_Matching_Status "true";
BA_ "Event" SG_ 1325 NAVI_MatchingReset "true";
BA_ "Event" SG_ 1325 NAVI_MatchingReset "true";
BA_ "Event" SG_ 1325 NAVI_MatchingReset "true";
BA_ "Event" SG_ 1325 NAVI_MatchingReset "true";
BA_ "Event" SG_ 1325 NAVI_DistanceToLinkFailure "true";
BA_ "Event" SG_ 1325 NAVI_DistanceToLinkFailure "true";
BA_ "Event" SG_ 1325 NAVI_DistanceToLinkFailure "true";
BA_ "Event" SG_ 1325 NAVI_DistanceToLinkFailure "true";
BA_ "Event" SG_ 1325 NAVI_LinkFailure "true";
BA_ "Event" SG_ 1325 NAVI_LinkFailure "true";
BA_ "Event" SG_ 1325 NAVI_LinkFailure "true";
BA_ "Event" SG_ 1325 NAVI_LinkFailure "true";
BA_ "Event" SG_ 1325 NAVI_TurningStatus "true";
BA_ "Event" SG_ 1325 NAVI_TurningStatus "true";
BA_ "Event" SG_ 1325 NAVI_TurningStatus "true";
BA_ "Event" SG_ 1325 NAVI_TurningStatus "true";
BA_ "Event" SG_ 1325 NAVI_CurvatureError "true";
BA_ "Event" SG_ 1325 NAVI_CurvatureError "true";
BA_ "Event" SG_ 1325 NAVI_CurvatureError "true";
BA_ "Event" SG_ 1325 NAVI_CurvatureError "true";
BA_ "Event" SG_ 1325 NAVI_LinkFailurePoint "true";
BA_ "Event" SG_ 1325 NAVI_LinkFailurePoint "true";
BA_ "Event" SG_ 1325 NAVI_LinkFailurePoint "true";
BA_ "Event" SG_ 1325 NAVI_LinkFailurePoint "true";
BA_ "Event" SG_ 1325 NAVI_DistanceToIntersection "true";
BA_ "Event" SG_ 1325 NAVI_DistanceToIntersection "true";
BA_ "Event" SG_ 1325 NAVI_DistanceToIntersection "true";
BA_ "Event" SG_ 1325 NAVI_DistanceToIntersection "true";
BA_ "Event" SG_ 1325 InGuidingRoute "true";
BA_ "Event" SG_ 1325 InGuidingRoute "true";
BA_ "Event" SG_ 1325 InGuidingRoute "true";
BA_ "Event" SG_ 1325 InGuidingRoute "true";
BA_ "Event" SG_ 1325 Current_Roadtype "true";
BA_ "Event" SG_ 1325 Current_Roadtype "true";
BA_ "Event" SG_ 1325 Current_Roadtype "true";
BA_ "Event" SG_ 1325 Current_Roadtype "true";
BA_ "Event" SG_ 1325 NAVI_DirectionDifference "true";
BA_ "Event" SG_ 1325 NAVI_DirectionDifference "true";
BA_ "Event" SG_ 1325 NAVI_DirectionDifference "true";
BA_ "Event" SG_ 1325 NAVI_DirectionDifference "true";
BA_ "Event" SG_ 1325 RoadData_UpdateCounter4 "true";
BA_ "Event" SG_ 1325 RoadData_UpdateCounter4 "true";
BA_ "Event" SG_ 1325 RoadData_UpdateCounter4 "true";
BA_ "Event" SG_ 1325 RoadData_UpdateCounter4 "true";
BA_ "Event" SG_ 1325 DistanceToTollgate "true";
BA_ "Event" SG_ 1325 DistanceToTollgate "true";
BA_ "Event" SG_ 1325 DistanceToTollgate "true";
BA_ "Event" SG_ 1325 DistanceToTollgate "true";
BA_ "Event" SG_ 1325 RouteGuiding_flag "true";
BA_ "Event" SG_ 1325 RouteGuiding_flag "true";
BA_ "Event" SG_ 1325 RouteGuiding_flag "true";
BA_ "Event" SG_ 1325 RouteGuiding_flag "true";
BA_ "Event" SG_ 1325 Current_Linktype "true";
BA_ "Event" SG_ 1325 Current_Linktype "true";
BA_ "Event" SG_ 1325 Current_Linktype "true";
BA_ "Event" SG_ 1325 Current_Linktype "true";
BA_ "Unavailable_Value" SG_ 1332 AIRBAGMalfunction "null";
BA_ "Unavailable_Value" SG_ 1332 PassengerSafetyBeltBuckleState "0b11";
BA_ "Unavailable_Value" SG_ 1332 PassengerPresenceState "0b11";
BA_ "Unavailable_Value" SG_ 1332 SecondRowLeftSafetyBeltState "0b11";
BA_ "Unavailable_Value" SG_ 1332 SecondRowCenterSafetyBeltState "0b11";
BA_ "Unavailable_Value" SG_ 1332 ThirdRowCenterSafetyBeltState "0b11";
BA_ "Unavailable_Value" SG_ 1332 SecondRowRightSafetyBeltState "0b11";
BA_ "Unavailable_Value" SG_ 1332 ThirdRowRightSafetyBeltState "0b11";
BA_ "Unavailable_Value" SG_ 1332 ThirdRowLeftSafetyBeltState "0b11";
BA_ "Unavailable_Value" SG_ 1332 FirstRowCenterSafetyBeltState "0b11";
BA_ "Unavailable_Value" SG_ 1334 RouteSegmentsNumber "Not applicable";
BA_ "Unavailable_Value" SG_ 1334 RouteID "0b000";
BA_ "Unavailable_Value" SG_ 1334 RouteStatus "0b000";
BA_ "Unavailable_Value" SG_ 1334 UrbanZevDrivingOption "0b0";
BA_ "Unavailable_Value" SG_ 1334 RouteLength "0xFFFF";
BA_ "Unavailable_Value" SG_ 1334 RouteDistanceFromStart "0x1FFFF";
BA_ "Event" SG_ 1335 SegmentRealTimeTrafficSpeed "true";
BA_ "Event" SG_ 1335 SegmentRealTimeTrafficSpeed "true";
BA_ "Event" SG_ 1335 SegmentRealTimeTrafficSpeed "true";
BA_ "Event" SG_ 1335 SegmentRealTimeTrafficSpeed "true";
BA_ "Unavailable_Value" SG_ 1335 SegmentRealTimeTrafficSpeed "0xFF";
BA_ "Event" SG_ 1335 SegmentStatisticalTrafficSpeed "true";
BA_ "Event" SG_ 1335 SegmentStatisticalTrafficSpeed "true";
BA_ "Event" SG_ 1335 SegmentStatisticalTrafficSpeed "true";
BA_ "Event" SG_ 1335 SegmentStatisticalTrafficSpeed "true";
BA_ "Unavailable_Value" SG_ 1335 SegmentStatisticalTrafficSpeed "0xFF";
BA_ "Event" SG_ 1335 SegmentRoadType "true";
BA_ "Event" SG_ 1335 SegmentRoadType "true";
BA_ "Event" SG_ 1335 SegmentRoadType "true";
BA_ "Event" SG_ 1335 SegmentRoadType "true";
BA_ "Unavailable_Value" SG_ 1335 SegmentRoadType "0b111";
BA_ "Event" SG_ 1335 SegmentSpeedLimit "true";
BA_ "Event" SG_ 1335 SegmentSpeedLimit "true";
BA_ "Event" SG_ 1335 SegmentSpeedLimit "true";
BA_ "Event" SG_ 1335 SegmentSpeedLimit "true";
BA_ "Unavailable_Value" SG_ 1335 SegmentSpeedLimit "0x1F";
BA_ "Event" SG_ 1335 SegmentIndex "true";
BA_ "Event" SG_ 1335 SegmentIndex "true";
BA_ "Event" SG_ 1335 SegmentIndex "true";
BA_ "Event" SG_ 1335 SegmentIndex "true";
BA_ "Unavailable_Value" SG_ 1335 SegmentIndex "0x000";
BA_ "Event" SG_ 1335 SegmentTrafficLightAndStopCount "true";
BA_ "Event" SG_ 1335 SegmentTrafficLightAndStopCount "true";
BA_ "Event" SG_ 1335 SegmentTrafficLightAndStopCount "true";
BA_ "Event" SG_ 1335 SegmentTrafficLightAndStopCount "true";
BA_ "Unavailable_Value" SG_ 1335 SegmentTrafficLightAndStopCount "0x3F";
BA_ "Event" SG_ 1335 SegmentLength "true";
BA_ "Event" SG_ 1335 SegmentLength "true";
BA_ "Event" SG_ 1335 SegmentLength "true";
BA_ "Event" SG_ 1335 SegmentLength "true";
BA_ "Unavailable_Value" SG_ 1335 SegmentLength "0x3FF";
BA_ "Event" SG_ 1335 SegmentRoadSlope "true";
BA_ "Event" SG_ 1335 SegmentRoadSlope "true";
BA_ "Event" SG_ 1335 SegmentRoadSlope "true";
BA_ "Event" SG_ 1335 SegmentRoadSlope "true";
BA_ "Unavailable_Value" SG_ 1335 SegmentRoadSlope "0x3FF";
BA_ "Event" SG_ 1335 SegmentInMandatoryZEVzone "true";
BA_ "Event" SG_ 1335 SegmentInMandatoryZEVzone "true";
BA_ "Event" SG_ 1335 SegmentInMandatoryZEVzone "true";
BA_ "Event" SG_ 1335 SegmentInMandatoryZEVzone "true";
BA_ "Unavailable_Value" SG_ 1335 SegmentInMandatoryZEVzone "0b0";
BA_ "Event" SG_ 1339 TimeHour "true";
BA_ "Event" SG_ 1339 TimeHour "true";
BA_ "Event" SG_ 1339 TimeHour "true";
BA_ "Event" SG_ 1339 TimeHour "true";
BA_ "Unavailable_Value" SG_ 1339 TimeHour "0x1F";
BA_ "Event" SG_ 1339 TimeMinute "true";
BA_ "Event" SG_ 1339 TimeMinute "true";
BA_ "Event" SG_ 1339 TimeMinute "true";
BA_ "Event" SG_ 1339 TimeMinute "true";
BA_ "Unavailable_Value" SG_ 1339 TimeMinute "0x3F";
BA_ "Event" SG_ 1339 DateYear "true";
BA_ "Event" SG_ 1339 DateYear "true";
BA_ "Event" SG_ 1339 DateYear "true";
BA_ "Event" SG_ 1339 DateYear "true";
BA_ "Unavailable_Value" SG_ 1339 DateYear "0x3FF";
BA_ "Event" SG_ 1339 TimeSeconde "true";
BA_ "Event" SG_ 1339 TimeSeconde "true";
BA_ "Event" SG_ 1339 TimeSeconde "true";
BA_ "Event" SG_ 1339 TimeSeconde "true";
BA_ "Unavailable_Value" SG_ 1339 TimeSeconde "0x3F";
BA_ "Event" SG_ 1339 DateMonth "true";
BA_ "Event" SG_ 1339 DateMonth "true";
BA_ "Event" SG_ 1339 DateMonth "true";
BA_ "Event" SG_ 1339 DateMonth "true";
BA_ "Unavailable_Value" SG_ 1339 DateMonth "0x0";
BA_ "Unavailable_Value" SG_ 1339 TimeWeekDay "0b111";
BA_ "Event" SG_ 1339 DateDay "true";
BA_ "Event" SG_ 1339 DateDay "true";
BA_ "Event" SG_ 1339 DateDay "true";
BA_ "Event" SG_ 1339 DateDay "true";
BA_ "Unavailable_Value" SG_ 1339 DateDay "0x00";
BA_ "Unavailable_Value" SG_ 1341 UPA_SoundRecurrenceType "0b0";
BA_ "Unavailable_Value" SG_ 1341 UPA_SoundRecurrencePeriod "0x7F";
BA_ "Unavailable_Value" SG_ 1341 UPA_SystemState "0b00";
BA_ "Unavailable_Value" SG_ 1341 UPA_Obstacle_Zone_Front_Right "0b111";
BA_ "Unavailable_Value" SG_ 1341 UPA_Obstacle_Zone_Front_Left "0b111";
BA_ "Unavailable_Value" SG_ 1341 UPA_Image_DisplayRequest "0b00";
BA_ "Unavailable_Value" SG_ 1341 UPA_Obstacle_Zone_Rear_Right "0b111";
BA_ "Unavailable_Value" SG_ 1341 UPA_Obstacle_Zone_Rear_Left "0b111";
BA_ "Unavailable_Value" SG_ 1341 UPA_SoundActivationBeep "0b0";
BA_ "Unavailable_Value" SG_ 1341 UPA_SoundErrorBeep "0b0";
BA_ "Unavailable_Value" SG_ 1341 UPA_Obstacle_Zone_Rear_Center "0b111";
BA_ "Unavailable_Value" SG_ 1341 UPA_Obstacle_Zone_Front_Center "0b111";
BA_ "Unavailable_Value" SG_ 1341 SensorAvailabilityFrontLeft "0b0";
BA_ "Unavailable_Value" SG_ 1341 SensorAvailabilityFrontCenter "0b0";
BA_ "Unavailable_Value" SG_ 1341 UPA_SoundObstacleZone "0b000";
BA_ "Unavailable_Value" SG_ 1341 UPAStatusDisplayRequest "0b000";
BA_ "Unavailable_Value" SG_ 1341 SensorAvailabilityFrontRight "0b0";
BA_ "Unavailable_Value" SG_ 1341 SonarObstacleDistanceDisplay "0x0";
BA_ "Unavailable_Value" SG_ 1341 ParkAssistVolumeState "Not applicable";
BA_ "Unavailable_Value" SG_ 1341 SensorAvailabilityRearRight "0b0";
BA_ "Unavailable_Value" SG_ 1341 SensorAvailabilityRearLeft "0b0";
BA_ "Unavailable_Value" SG_ 1341 SensorAvailabilityRearCenter "0b0";
BA_ "Unavailable_Value" SG_ 1341 UPA_ClosingAuthorization "0b0";

VAL_ 32 AirbagCrashOrder_v3 47 "Rear crash" 31 "Violent crash" 15 "Medium crash" 0 "Crash not detected";
VAL_ 116 StopAutoPhase 7 "Unavailable" 6 "ReflexStart" 5 "StartByInjectionOnly" 4 "StopAutoOngoing" 3 "Not Used" 2 "StopAuto" 1 "StartAuto" 0 "NotInAutoPhase";
VAL_ 117 PowerTrainStatus 3 "Powertrain Starting" 2 "Powertrain Running" 1 "Reserved" 0 "Powertrain Stopped";
VAL_ 168 SwaSensorInternalStatus 7 "reserved" 6 "reserved" 5 "calibrated, initialised" 4 "calibrated, not initialised" 3 "reserved" 2 "fault" 1 "not calibrated, indexed" 0 "not calibrated, not indexed";
VAL_ 286 TorqueConverterState 3 "unavailable" 2 "locked-up converter" 1 "sliding converter" 0 "unlocked converter";
VAL_ 303 GearLeverPosition_v2 15 "Not available (init or lever switched failure)" 14 "Not used" 13 "Not used" 12 "Not used" 11 "Not used" 10 "Not used" 9 "Not used" 8 "B (Brake)" 7 "Confirmed lever position (no switch signal)" 6 "Ds" 5 "L" 4 "Manual mode - M" 3 "Drive - D" 2 "Neutral - N" 1 "Reverse - R" 0 "Parking - P";
VAL_ 514 ABSinRegulation 1 "ABS in regulation" 0 "no ABS regulation";
VAL_ 514 WheelTopFL 108 "Max Nissan Value for 108 pulses" 96 "Max Nissan Value for 96 pulses";
VAL_ 514 WheelTopFR 108 "Max Nissan Value for 108 pulses" 96 "Max Nissan Value for 96 pulses";
VAL_ 514 MSRinRegulation 1 "MSR in regulation" 0 "no MSR regulation";
VAL_ 514 WheelTopRL 108 "Max Nissan Value for 108 pulses" 96 "Max Nissan Value for 96 pulses";
VAL_ 514 WheelTopRR 108 "Max Nissan Value for 108 pulses" 96 "Max Nissan Value for 96 pulses";
VAL_ 514 AYCMalfunction 1 "AYC malfunction" 0 "no AYC malfunction";
VAL_ 514 AYCinRegulation 1 "AYC in regulation" 0 "no AYC regulation";
VAL_ 514 ASRMalfunction 1 "ASR malfunction" 0 "No ASR malfunction";
VAL_ 514 ABSMalfunction 1 "ABS malfunction" 0 "no ABS malfunction";
VAL_ 534 EPSWarning 3 "Not Used" 2 "EPS failure level 2" 1 "EPS failure level 1" 0 "No EPS warning";
VAL_ 606 ADASISv2_ShortRang 0 "Table Value30479";
VAL_ 791 ISS_EcoActivationState 3 "Not used" 2 "ECO deactivated" 1 "ECO activated" 0 "Unavailable";
VAL_ 791 AirCondEcoActivationState 3 "Not used" 2 "ECO deactivated" 1 "ECO activated" 0 "Unavailable";
VAL_ 791 ClimECOModeStatusDisplay 3 "Unavailable" 2 "Not Activated" 1 "Activated" 0 "No display";
VAL_ 823 IoniserAutoLaunchState 3 "Not used" 2 "Auto launch not activated" 1 "Auto launch activated" 0 "Unavailable";
VAL_ 823 AQMAirFreshenerDisplayRequest 3 "Air Freshener delayed display" 2 "Air Freshener refused display" 1 "Air Freshener ON display" 0 "No display (Air Freshener OFF)";
VAL_ 823 ClimForcedRecyDisplay 3 "Not Used" 2 "Recycling OFF" 1 "Recycling On" 0 "No display";
VAL_ 823 AQMIoniserModeState 7 "Not used" 6 "Not used" 5 "Not used" 4 "Refused" 3 "Relax" 2 "Clean" 1 "Off" 0 "Unavailable";
VAL_ 823 ClimAutoRecyclingDisplay 3 "Not Used" 2 "Automatic Recycling in progress" 1 "Automatic Recycling not in progress" 0 "Unavailable value";
VAL_ 893 LDW_VibrationIntensityState 3 "High Intensity  " 2 "Middle Intensity  " 1 "Low Intensity" 0 "Unavailable";
VAL_ 893 LCA_SteeringStatus2 3 "Error" 2 "Temporary error" 1 "Ready" 0 "Not Ready";
VAL_ 928 ADASISv2_LongRang 0 "Table Value30443";
VAL_ 929 ADASISv2_SEGMENT 0 "Table Value30478";
VAL_ 931 ADASISv2_STUB 0 "Table Value30480";
VAL_ 934 APA_StatusDisplay2 3 "Not Used" 2 "Automatic maneuver ON" 1 "Automatic maneuver Standby" 0 "Automatic maneuver OFF";
VAL_ 955 RST_Boost_Activation_MMI 3 "Boost Unavailable" 2 "Not used" 1 "Boost Activated" 0 "Boost Deactivated";
VAL_ 961 DistanceBeforeNextAction 0 "Table Value26873";
VAL_ 961 UnitDistanceBeforeNextAction 15 "not used" 14 "not used" 13 "not used" 12 "not used" 11 "not used" 10 "not used" 9 "not used" 8 "not used" 7 "not used" 6 "not used" 5 "not used" 4 "feet" 3 "mile" 2 "yard" 1 "kilometer" 0 "meter";
VAL_ 961 LivingLightReq 3 "Reset Request" 2 "AmbientLighting Living not requested" 1 "AmbientLighting Living requested" 0 "No Request";
VAL_ 961 NavigationIconFailureMode 7 "Front-Left" 6 "Left" 5 "Rear-Left" 4 "Rear" 3 "Rear-Right" 2 "Right" 1 "Front-Right" 0 "Front";
VAL_ 961 NAVI_BootStatus 1 "boot" 0 "Not boot";
VAL_ 961 NAVI_OperationError 1 "Error" 0 "No Error";
VAL_ 962 APA_StatusDisplay 3 "Not Used" 2 "Automatic maneuver ON" 1 "Automatic maneuver Standby" 0 "Automatic maneuver OFF";
VAL_ 967 CDisplayAvailability 3 "Not Used" 2 "Display Not Available" 1 "Display Available" 0 "Unavailable";
VAL_ 967 AutoACC2_ON_Request_MM 3 "Not used" 2 "Multimedia_ON_Request" 1 "Preparation_Request" 0 "No request";
VAL_ 967 Audio_WorkingAuthorize 3 "Authorized " 2 "reserved" 1 "reserved" 0 "Not authorized";
VAL_ 967 IVI_RefusetoSleep 3 "reserved" 2 "IVI ready to sleep" 1 "IVI refuse to sleep" 0 "reserved";
VAL_ 967 SonarSystemPauseRequest2 1 "System Pause requested" 0 "No request";
VAL_ 967 IVI_InitializationState 1 "Initialization in progress" 0 "Initialization completed";
VAL_ 967 UserFeedbackAvailability 1 "user feedback unavailable" 0 "user feedback available";
VAL_ 967 AudioAvailability 1 "audio unavailable" 0 "audio available";
VAL_ 967 SwitchRequest_AVM 1 "Switch pushed" 0 "Switch released";
VAL_ 967 ChangeViewRequest_AVM 3 "Off" 2 "Side view" 1 "Bird view" 0 "No request";
VAL_ 967 Audio_ProcessingDeactivation 1 "Deactivation Requested" 0 "No request";
VAL_ 967 PassengerHeatingRequest 3 "Off request" 2 "Heating 2 request" 1 "Heating 1 request" 0 "No Request";
VAL_ 967 PassengerVentilRequest 3 "Off request" 2 "Ventilation 2 request" 1 "Ventilation 1 request" 0 "No Request";
VAL_ 967 DriverHeatingRequest 3 "Off request" 2 "Heating 2 request" 1 "Heating 1 request" 0 "No Request";
VAL_ 967 DriverVentilRequest 3 "Off request" 2 "Ventilation 2 request" 1 "Ventilation 1 request" 0 "No Request";
VAL_ 967 StorageFormatRequest 3 "Not used" 2 "Format Reject by User" 1 "Format request" 0 "No request";
VAL_ 967 TPMS_ResetDriverRequest2 3 "Not Used" 2 "TPMS Reset driver requested " 1 "TPMS Reset driver NOT requested " 0 "Unvailable Value";
VAL_ 967 TPW_ResetDriverRequest2 3 "Not used" 2 "TPW Reset driver requested" 1 "TPW Reset driver NOT requested" 0 "Unavailable";
VAL_ 967 EcoPedalForceSettingRequest 3 "ECO Pedal Force setting status Standard SW ON" 2 "ECO Pedal Force setting status Soft SW ON" 1 "ECO Pedal Force setting OFF SW ON" 0 "No request";
VAL_ 967 HUD_UpDownRequest2 3 "Reset request" 2 "Down command requested" 1 "Up command requested" 0 "No request";
VAL_ 967 IVI_ParkAssistVolumeState 7 "Not used" 6 "Not used" 5 "Level 5" 4 "Level 4" 3 "Level 3" 2 "Level 2" 1 "Level 1" 0 "Level 0 (off)";
VAL_ 970 VirtualKeyActivationState 1 "Virtual Key is activated" 0 "Virtual Key is deactivated";
VAL_ 970 VirtualKeyState 1 "VK Resumed" 0 "VK Suspended";
VAL_ 972 AD_TransitionState 15 "Not used" 14 "Not used" 13 "Not used" 12 "Not used" 11 "Not used" 10 "AD1L3 to AD1" 9 "AD1L3 to AD2L2 HandsON" 8 "AD1L3 to AD2L2 HandsOFF" 7 "AD2L2 HandsOFF to AD1L3" 6 "AD2L2 HandsOFF to AD1" 5 "AD2L2 HandsOFF to AD2L2 HandsON" 4 "AD2L2 HandsON to AD1L3" 3 "AD2L2 HandsON to AD2L2 HandsOFF" 2 "AD2L2 HandsON to AD1" 1 "AD1 to AD2L2 HandsON" 0 "No display";
VAL_ 972 AD2L2_HOFF_TransitonState 31 "Not used" 30 "Not used" 29 "Not used" 28 "Not used" 27 "Not used" 26 "Not used" 25 "Not used" 24 "Not used" 23 "Not used" 22 "Not used" 21 "Not used" 20 "Not used" 19 "Not used" 18 "Not used" 17 "Not used" 16 "Not used" 15 "Not used" 14 "Not used" 13 "Not used" 12 "Not used" 11 "Not used" 10 "System deactivation lvl2 ON Operational to OFF" 9 "System deactivation lvl1 ON Operational to OFF" 8 "System deactivation lvl2 ON Operational to ON NotOperational" 7 "System deactivation lvl1 ON Operational to ON NotOperational" 6 "System deactivation lvl2 ON NotOperational to OFF" 5 "System deactivation lvl1 ON NotOperational to OFF" 4 "User deactivation : ON Operational to OFF" 3 "User deactivation : ON NotOperational to OFF" 2 "System activation : ON NotOperational to Operational" 1 "User activation : OFF to AD2L2_HOFF ON NotOperational" 0 "No display";
VAL_ 972 AD2L2_HON_TransitonState 31 "Not used" 30 "Not used" 29 "Not used" 28 "Not used" 27 "Not used" 26 "Not used" 25 "Not used" 24 "Not used" 23 "Not used" 22 "Not used" 21 "Not used" 20 "Not used" 19 "Not used" 18 "Not used" 17 "Not used" 16 "Not used" 15 "Not used" 14 "Not used" 13 "Not used" 12 "Not used" 11 "Not used" 10 "System deactivation lvl2 ON Operational to OFF" 9 "System deactivation lvl1 ON Operational to OFF" 8 "System deactivation lvl2 ON Operational to ON NotOperational" 7 "System deactivation lvl1 : ON Operational to ON NotOperational" 6 "System deactivation lvl2 : ON NotOperational to OFF" 5 "System deactivation lvl1: ON NotOperational to OFF" 4 "User deactivation : ON Operational to OFF" 3 "User deactivation : NotOperational to OFF" 2 "System activation : ON NotOperational to ON Operational" 1 "User activation OFF to AD2L2_HON ON NotOperational" 0 "No display";
VAL_ 972 ADL3_MRM 31 "Alert Eyes not on road level16" 30 "Alert Eyes not on road level15" 29 "Alert Eyes not on road level14" 28 "Alert Eyes not on road level13" 27 "Alert Eyes not on road level12" 26 "Alert Eyes not on road level11" 25 "Alert Eyes not on road level10" 24 "Alert Eyes not on road level9" 23 "Alert Eyes not on road level8" 22 "Alert Eyes not on road level7" 21 "Alert Eyes not on road level6" 20 "Alert Eyes not on road level5" 19 "Alert Eyes not on road level4" 18 "Alert Eyes not on road level3" 17 "Alert Eyes not on road level2" 16 "Alert Eyes not on road level1" 15 "Alert Eyes on road level15" 14 "Alert Eyes on road level14" 13 "Alert Eyes on road level13" 12 "Alert Eyes on road level12" 11 "Alert Eyes on road level11" 10 "Alert Eyes on road level10" 9 "Alert Eyes on road level9" 8 "Alert Eyes on road level8" 7 "Alert Eyes on road level7" 6 "Alert Eyes on road level6" 5 "Alert Eyes on road level5" 4 "Alert Eyes on road level4" 3 "Alert Eyes on road level3" 2 "Alert Eyes on road level2" 1 "Alert Eyes on road level1" 0 "No display";
VAL_ 972 ADL3_TransitionState 31 "Not used" 30 "Not used" 29 "Not used" 28 "Not used" 27 "Not used" 26 "Not used" 25 "Not used" 24 "Not used" 23 "Not used" 22 "Not used" 21 "Not used" 20 "Not used" 19 "Not used" 18 "ON Operational to OFF level2" 17 "ON Operational to OFF level1" 16 "ON Operational to NotOperational Available wo Longi level2" 15 "ON Operational to NotOperational Available wo Longi level1" 14 "ON Operational to NotOperational Available w Longi level2" 13 "ON Operational to NotOperational Available w Longi level1" 12 "ON Operational to ON Ready level2" 11 "ON Operational to ON Ready level1" 10 "ON Ready to ON Operational" 9 "ON Ready to OFF" 8 "ON Ready to NotOperational Available wo Longi" 7 "ON Ready to NotOperational Available w Longi" 6 "NotOperational Available w Longi to ON Ready" 5 "NotOperational Available w Longi to OFF" 4 "NotOperational Available w Longi to NotOperational Available wo Longi" 3 "NotOperational Available wo Longi to NotOperational Available w Longi" 2 "User deactivation : NotOperational Available to OFF" 1 "User activation : OFF to NotOperational Available wo Longi" 0 "No display";
VAL_ 972 AD_CutinLeftDisplay 15 "Not used" 14 "Not used" 13 "Not used" 12 "Not used" 11 "Not used" 10 "Not used" 9 "Not used" 8 "Unknown Alert with risk" 7 "Unknown Alert without risk" 6 "Car Alert with risk" 5 "Car Alert without risk" 4 "Truck Alert with risk" 3 "Truck Alert without risk" 2 "Motorbike Alert with risk" 1 "Motorbike Alert without risk" 0 "No display";
VAL_ 972 AD_CancelReasonRER 1 "Reemission request" 0 "No request";
VAL_ 972 AD_CutinRightDisplay 15 "Not used" 14 "Not used" 13 "Not used" 12 "Not used" 11 "Not used" 10 "Not used" 9 "Not used" 8 "Unknown Alert with risk" 7 "Unknown Alert without risk" 6 "Car Alert with risk" 5 "Car Alert without risk" 4 "Truck Alert with risk" 3 "Truck Alert without risk" 2 "Motorbike Alert with risk" 1 "Motorbike Alert without risk" 0 "No display";
VAL_ 986 ALC_Distance 0 "No Display";
VAL_ 986 AD2_HandsOff_MRM 31 "Alert Eyes not on road level16" 30 "Alert Eyes not on road level15" 29 "Alert Eyes not on road level14" 28 "Alert Eyes not on road level13" 27 "Alert Eyes not on road level12" 26 "Alert Eyes not on road level11" 25 "Alert Eyes not on road level10" 24 "Alert Eyes not on road level9" 23 "Alert Eyes not on road level8" 22 "Alert Eyes not on road level7" 21 "Alert Eyes not on road level6" 20 "Alert Eyes not on road level5" 19 "Alert Eyes not on road level4" 18 "Alert Eyes not on road level3" 17 "Alert Eyes not on road level2" 16 "Alert Eyes not on road level1" 15 "Alert Eyes on road level15" 14 "Alert Eyes on road level14" 13 "Alert Eyes on road level13" 12 "Alert Eyes on road level12" 11 "Alert Eyes on road level11" 10 "Alert Eyes on road level10" 9 "Alert Eyes on road level9" 8 "Alert Eyes on road level8" 7 "Alert Eyes on road level7" 6 "Alert Eyes on road level6" 5 "Alert Eyes on road level5" 4 "Alert Eyes on road level4" 3 "Alert Eyes on road level3" 2 "Alert Eyes on road level2" 1 "Alert Eyes on road level1" 0 "No display";
VAL_ 986 AD_FocusStateRequest 3 "Focus level3" 2 "Focus level2" 1 "Focus level1" 0 "No Request";
VAL_ 986 AD_AvailabilityLevel 15 "Not used" 14 "Not used" 13 "Not used" 12 "Not used" 11 "AD Availability Level11 (up)" 10 "AD Availability Level10 (up/dn)" 9 "AD Availability Level9 (dn)" 8 "AD Availability Level8 (dn)" 7 "AD Availability Level7 (up/dn)" 6 "AD Availability Level6 (up/dn)" 5 "AD Availability Level5" 4 "AD Availability Level4" 3 "AD Availability Level3" 2 "AD Availability Level2 (up/dn)" 1 "AD Availability Level1 (dn)" 0 "No display";
VAL_ 986 ADL3_Status 3 "Not Used" 2 "L3 Deactivated" 1 "L3 Activated" 0 "No display";
VAL_ 986 AD_MRM_PhaseCounter 0 "No display";
VAL_ 993 FirstParkStartPositionID 0 "Unavailable";
VAL_ 993 SecondParkStartPositionID 0 "Unavailable";
VAL_ 993 ThirdParkStartPositionID 0 "Unavailable";
VAL_ 993 ThirdParkStartPositionDistanceType 1 "Straight line distance" 0 "Real link distance";
VAL_ 993 SecondParkStartPositionDistanceType 1 "Straight line distance" 0 "Real link distance";
VAL_ 993 FirstParkStartPositionDistanceType 1 "Straight line distance" 0 "Real link distance";
VAL_ 996 DriverMassageProgramState_v2 7 "Not used" 6 "Not used" 5 "Program massage 5 is runnning" 4 "Program massage 4 is runnning" 3 "Program massage 3 is runnning" 2 "Program massage 2 is runnning" 1 "Program massage 1 is runnning" 0 "Massage is not running";
VAL_ 1000 APPRUN_ActivationState 1 "Approach Unlock is activated" 0 "Approach Unlock is deactivated (initial value)";
VAL_ 1000 WAL_ActivationState 1 "Walk Away Locking is activated" 0 "Walk Away Locking is deactivated (initial value)";
VAL_ 1000 IKeyAccessActivationState 1 "iKey Access is Activated" 0 "iKey Access is Desactivated";
VAL_ 1001 PassengerMassageProgramState_v2 7 "Not used" 6 "Not used" 5 "Program massage 5 is runnning" 4 "Program massage 4 is runnning" 3 "Program massage 3 is runnning" 2 "Program massage 2 is runnning" 1 "Program massage 1 is runnning" 0 "Massage is not running";
VAL_ 1003 AD_SteeringWheelTakeOverAlert 7 "Alert level7" 6 "Alert level6" 5 "Alert level5" 4 "Alert level4" 3 "Alert level3" 2 "Alert level2" 1 "Alert level1" 0 "No Alert";
VAL_ 1003 AD_StatusDisplay 15 "Not used" 14 "Not used" 13 "Not used" 12 "Not used" 11 "Not used" 10 "AD_PermanentFailure" 9 "AD_TemporaryFailure" 8 "AD1L3 Operational" 7 "AD1L3 Ready" 6 "AD1L3 NotOperational Available w Longi" 5 "AD1L3 NotOperational Available wo Longi" 4 "AD2L2 HOFF Operational" 3 "AD2L2 HOFF NotOperational" 2 "AD2L2 HON Operational" 1 "AD2L2 HON NotOperational" 0 "No display";
VAL_ 1003 ALC_HandsRequest 3 "Not used" 2 "Hands Requested with risk" 1 "Hands Requested without risk" 0 "Hands NotRequested";
VAL_ 1003 ALC_StatusDisplay 7 "Not used" 6 "Operational Standby" 5 "Operational Active HandsOFF" 4 "Operational Active HandsON" 3 "Operational waiting HandsOFF" 2 "Operational waiting HandsON" 1 "Not Operational" 0 "No display";
VAL_ 1012 TCU_MuteRadioOrder 1 "Mute radio order" 0 "No mute radio order";
VAL_ 1012 IVC_FOTAbusyFlag 1 "IVC FOTA Ready" 0 "IVC FOTA Busy";
VAL_ 1012 IVC_FOTA_Status_v2 31 "invalid" 30 "Not used" 29 "Not used" 28 "Not used" 27 "Not used" 26 "Not used" 25 "Not used" 24 "Not used" 23 "Not used" 22 "Not used" 21 "Not used" 20 "Inventory upload completed" 19 "Inventory upload in progress" 18 "Setting completed" 17 "Setting in progress" 16 "Reboot in progress" 15 "Rollback complete" 14 "Rollback in progress" 13 "Cancel complete" 12 "Cancel in progress" 11 "Activation complete" 10 "Activation in progress" 9 "Ready for activation" 8 "Vehicle Condition check in progress" 7 "Installation complete" 6 "Installation in progress" 5 "Distribution complete" 4 "Integrity check in progress" 3 "Distribution in progress" 2 "Inventory read complete" 1 "Inventory read in progress" 0 "idle";
VAL_ 1017 UTA_VigilanceLevelDisplay 15 "Unavailable" 14 "Not used" 13 "Not used" 12 "Not used" 11 "Not used" 10 "Not used" 9 "Not used" 8 "Vigilance Level 8" 7 "Vigilance Level 7" 6 "Vigilance Level 6" 5 "Vigilance Level 5" 4 "Vigilance Level 4" 3 "Vigilance Level 3" 2 "Vigilance Level 2" 1 "Vigilance Level 1" 0 "UTA not operational";
VAL_ 1017 UTA_AlertActivationState 1 "UTA Activated" 0 "UTA NOT Activated";
VAL_ 1017 UTA_VigilanceAlertDisplay_v2 3 "Not used" 2 "Reemission Request" 1 "Vigilance Alert Display" 0 "NO Vigilance Alert Display";
VAL_ 1028 VSPSoundActivationState 1 "Activated" 0 "Not Activated";
VAL_ 1028 VSPsoundChoiceActivationState 7 "Not used" 6 "Not used" 5 "Not used" 4 "VSP Choice 5" 3 "VSP Choice 4" 2 "VSP Choice 3" 1 "VSP Choice 2" 0 "VSP Choice 1";
VAL_ 1047 AVM_WarningDisplayRequest 7 "Message 7" 6 "Message 6" 5 "Message 5" 4 "Message 4" 3 "Message 3" 2 "Message 2" 1 "Message 1" 0 "No message";
VAL_ 1047 HFP_ExtendedInstrContentDisplay2 31 "unavailable" 30 "instruction 31" 29 "instruction 30" 28 "instruction 29" 27 "instruction 28" 26 "instruction 27" 25 "instruction 26" 24 "instruction 25" 23 "instruction 24" 22 "instruction 23" 21 "instruction 22" 20 "instruction 21" 19 "instruction 20" 18 "instruction 19" 17 "instruction 18" 16 "instruction 17" 15 "instruction 16" 14 "instruction 15" 13 "instruction 14" 12 "instruction 13" 11 "instruction 12" 10 "instruction 11" 9 "instruction 10" 8 "instruction 9" 7 "instruction 8" 6 "instruction 7" 5 "instruction 6" 4 "instruction 5" 3 "instruction 4" 2 "instruction 3" 1 "instruction 2" 0 "instruction 1";
VAL_ 1058 OSPSpeedUnit 3 "unavailable" 2 "not used" 1 "mph" 0 "km/h";
VAL_ 1065 HVBatteryLow 1 "HV Battery Low Display Requested" 0 "No HV Battery Low Display Requested";
VAL_ 1065 ChargingPlugConnected_v2 3 "Unavailable value" 2 "PWT Start impossible - Plug Connected" 1 "Charging Plug is Connected" 0 "No display request (Charging Plug is NOT Connected)";
VAL_ 1065 AuxEnergyFlow 3 "Not used" 2 "Battery  to accessory - High power" 1 "Battery to accessory - Low power" 0 "No power";
VAL_ 1065 AllWheelDriveFlag 1 "AWD" 0 "2WD";
VAL_ 1065 EcoNavStatus_v2 15 "Not Used" 14 "Not Used" 13 "Not Used" 12 "Not Used" 11 "Not Used" 10 "Not Used" 9 "Not Used" 8 "No ZEV Zone Function" 7 "Solution with ask to recharge at station" 6 "Solution with ask to recharge on driving" 5 "Failed to compute" 4 "On updating" 3 "On regulation" 2 "On computing" 1 "Awaiting data transmission" 0 "Function not activated";
VAL_ 1065 TireRotatingDirection 3 "Unavailable value" 2 "Back direction" 1 "Forward direction" 0 "Stop";
VAL_ 1066 HVbatteryChargeType_v2 7 "V2G" 6 "V2H" 5 "Ultra fast" 4 "Quick charge" 3 "Fast charge" 2 "Accelerated charge" 1 "Normal charge" 0 "No charge";
VAL_ 1068 EngineMotorEnergyFlow_v2 7 "Not used" 6 "Motor to Engine - High Power" 5 "Motor to Engine - Mid Power" 4 "Motor to Engine - Low Power" 3 "Engine to Motor - High Power" 2 "Engine to Motor - Mid Power" 1 "Engine to Motor - Low Power" 0 "No Power";
VAL_ 1068 VehicleTractionMode 7 "Unavailable value" 6 "Unavailable value" 5 "Vehicle in hybrid parallel mode" 4 "Vehicle in thermic mode" 3 "Vehicle in hybrid serial mode" 2 "Vehicle in full electric mode" 1 "Vehicle in charge" 0 "Vehicle not in traction mode";
VAL_ 1068 EngineWheelEnergyFlow_v2 7 "Not used" 6 "Wheel to Engine - High Power" 5 "Wheel to Engine - Mid Power" 4 "Wheel to Engine - Low Power" 3 "Engine to Wheel - High Power" 2 "Engine to Wheel - Mid Power" 1 "Engine to Wheel- Low Power" 0 "No Power";
VAL_ 1068 BatteryMotorEnergyFlow_v2 7 "Not used" 6 "Motor to Battery - High Power" 5 "Motor to Battery - Mid Power" 4 "Motor to Battery - Low Power" 3 "Battery to Motor - High Power" 2 "Battery to Motor - Mid Power" 1 "Battery to Motor - Low Power" 0 "No Power";
VAL_ 1068 ChargingStatusDisplay_v2 15 "Not used" 14 "Not used" 13 "Not used" 12 "Not used" 11 "Not used" 10 "Not used" 9 "Not used" 8 "Charging is continue with full SOC" 7 "Stopped charge(SOC is not full)" 6 "Energy Flap opened: welcome MMI" 5 "Waiting for current charge" 4 "Charge failure" 3 "Charge in progress" 2 "Ended charge" 1 "Waiting a planned charge" 0 "No charge";
VAL_ 1076 WAC_APRUN_ActivationState 1 "WAC & APRUN is Activated" 0 "WAC & APRUN is Desactivated";
VAL_ 1076 SwitchOffSESDisturbers 1 "Disturbers switch off requested" 0 "No request";
VAL_ 1081 TCS_DeactivationState 1 "TCS deactivated" 0 "TCS not deactivated";
VAL_ 1099 ATCVT_RangeIndicationExtended 63 "Not used" 62 "Not used" 61 "Not used" 60 "Not used" 59 "Not used" 58 "Not used" 57 "Not used" 56 "Not used" 55 "Not used" 54 "Not used" 53 "Not used" 52 "Not used" 51 "Not used" 50 "Not used" 49 "Not used" 48 "Not used" 47 "Not used" 46 "Not used" 45 "Not used" 44 "Not used" 43 "Not used" 42 "Not used" 41 "Auto 10th" 40 "Auto 9th" 39 "Auto 8th" 38 "Auto 7th" 37 "Auto 6th" 36 "Auto 5th" 35 "Auto 4th" 34 "Auto 3rd" 33 "Auto 2nd" 32 "Auto 1st" 31 "Not used" 30 "Not used" 29 "M10th" 28 "M9th" 27 "M8th" 26 "M7th" 25 "M6th" 24 "M5th" 23 "M4th" 22 "M3rd" 21 "M2nd" 20 "M1st" 19 "Not used" 18 "Not used" 17 "10th range" 16 "9th range" 15 "8th range" 14 "7th range" 13 "6th range" 12 "5th range" 11 "4th range" 10 "3rd range" 9 "2nd range" 8 "1st range" 7 "B range" 6 "L range" 5 "S range" 4 "D range" 3 "N range" 2 "R range" 1 "P range" 0 "OFF";
VAL_ 1100 RST_LaunchControlReady 3 "reserved" 2 "Launch Control Active" 1 "Launch Control Not Active" 0 "Launch Control Not Available";
VAL_ 1101 FlashingIndicatorStatusDisplay 7 "Unavailable" 6 "Not used" 5 "Not used" 4 "Not used" 3 "left flashing indicator ON and right flashing indicator ON" 2 "left flashing indicator OFF and right flashing indicator ON" 1 "left flashing indicator ON and right flashing indicator OFF" 0 "left and right flashing indicators OFF";
VAL_ 1102 AutoLockActivationState 3 "Not used" 2 "Auto Lock with Park-out is activated" 1 "Auto Lock with Speed is activated" 0 "Auto Lock is not activated";
VAL_ 1102 AutoLightSensitivityStatus 3 "Configuration 4 activated" 2 "Configuration 3 activated" 1 "Configuration 2 activated" 0 "Configuration 1 activated";
VAL_ 1102 AutoFrontWiperActivationStatus 3 "Not used" 2 "Not used" 1 "Auto Front wiper activation requested" 0 "Auto Front wiper de-activation requested";
VAL_ 1102 AHL_ActivationState 3 "Unavailable" 2 "AHL NOT activated" 1 "AHL activated" 0 "Not used";
VAL_ 1102 RearWiperStatus 3 "Not used" 2 "Rear wiper de-activation requested" 1 "Rear wiper activation requested" 0 "Unavailable";
VAL_ 1102 AutoUnLockActivationState 3 "Not used" 2 "Auto UnLock with Park is activated" 1 "Auto UnLock with IGN OFF is activated" 0 "Auto UnLock is not activated";
VAL_ 1102 AmbientLightingPatternState 1 "Deactivated" 0 "Activated";
VAL_ 1102 AutoFMHactivationState 1 "Deactivated" 0 "Activated";
VAL_ 1102 AutoInternalLightingState 1 "Activation" 0 "Deactivation";
VAL_ 1102 AutoFMHdurationState 7 "Not used" 6 "180 sec" 5 "150 sec" 4 "120 sec" 3 "90 sec" 2 "60 sec" 1 "45 sec" 0 "30 sec";
VAL_ 1102 ADB_ActivationState 1 "Deactivated" 0 "Activated";
VAL_ 1102 AutoReLockActivationState 1 "Auto ReLock ON" 0 "Auto ReLock OFF";
VAL_ 1102 FrontRearWiperDropStatus 1 "Wiper Drop Activated" 0 "Wiper Drop Deactivated";
VAL_ 1102 WGSactivationState 1 "Deactivated" 0 "Activated";
VAL_ 1102 LowBeamDisplay 1 "low beam display requested" 0 "low beam display not requested";
VAL_ 1102 HighBeamDisplay 1 "High beam display requested" 0 "High beam display not requested";
VAL_ 1103 BCM_SteeringPushToTalkCommand 1 "button pressed" 0 "button released";
VAL_ 1103 BCM_SteeringPhoneCommand 1 "button pressed" 0 "button released";
VAL_ 1103 BCM_SteeringCommandE 1 "button pressed" 0 "button released";
VAL_ 1103 BCM_SteeringCommandA 1 "button pressed" 0 "button released";
VAL_ 1103 BCM_MMISteeringSwitchesFailure 1 "MMI steering switches failure" 0 "No MMI steering switches failure";
VAL_ 1104 ExternalTempDisplayUnit 1 "display mode in °F" 0 "display mode in °C";
VAL_ 1104 SteeringPushToTalkCommand 1 "Button pressed" 0 "Button released";
VAL_ 1104 SteeringPhoneCommand 1 "Button pressed" 0 "Button released";
VAL_ 1104 UnitDistanceDisplayState 1 "displayed unit in mph" 0 "displayed unit in km";
VAL_ 1104 Meter_ADACresetRequest 1 "Reset  METER requested" 0 "Reset  METER not requested";
VAL_ 1104 DiagnosedFuelLow 3 "Not used" 2 "Empty" 1 "Not empty" 0 "Unavailable";
VAL_ 1104 MuteRadioOrder 1 "Mute radio order" 0 "No mute radio order";
VAL_ 1104 WelcomeSequenceStatus 3 "Sequence Done" 2 "Sequence in progress" 1 "Sequence not Started" 0 "Unavailable";
VAL_ 1104 DisplayedOilLevel 15 "not available" 14 "Not used" 13 "Not used" 12 "Not used" 11 "Not used" 10 "Not used" 9 "Not used" 8 "8 bargraph element displayed" 7 "7 bargraph element displayed" 6 "6 bargraph element displayed" 5 "5 bargraph element displayed" 4 "4 bargraph element displayed" 3 "3 bargraph element displayed" 2 "2 bargraph element displayed" 1 "1 bargraph element displayed" 0 "warning";
VAL_ 1104 MeterVolumeState 3 "Volume 3" 2 "Volume 2" 1 "Volume 1" 0 "Unavailable";
VAL_ 1104 FuelLevelDisplayed 0 "petrol tank reserve";
VAL_ 1105 DisplayedSpeedUnit 1 "Speed Unit in mph" 0 "Speed Unit in kmph";
VAL_ 1105 GlobalVehicleWarningState 3 "SERV and STOP are ON (alert type R3& D3)" 2 "STOP is ON (alert type D3)" 1 "SERV is ON (alert type R3)" 0 " No gloval  vehicle  Fault";
VAL_ 1105 DayNightForBacklights 3 "Unavailable" 2 "Night" 1 "Twilight" 0 "Day";
VAL_ 1105 ParkingBrakeStatus 3 "Unavailable" 2 "Automatic or manual Parking brake applied" 1 "Automatic or manual Parking brake not applied" 0 "Not used";
VAL_ 1106 AutoDimmingState 1 "AutoDimming activated" 0 "AutoDimming Not activated";
VAL_ 1106 DayNightStatusForB_Switches 1 "Permanent backlight" 0 "Conditionned backlight";
VAL_ 1106 RST_GearShiftBuzzerActivState 3 "Not used" 2 "Deactivated" 1 "Activated" 0 "Unavailable";
VAL_ 1106 AutoDimmingOffsetY0 15 "Step 15" 14 "Step 14" 13 "Step 13" 12 "Step 12" 11 "Step 11" 10 "Step 10" 9 "Step 9" 8 "Step 8" 7 "Step 7" 6 "Step 6" 5 "Step 5" 4 "Step 4" 3 "Step 3" 2 "Step 2" 1 "Step 1" 0 "Unavailable";
VAL_ 1107 RearGearEngaged 3 "unavailable" 2 "Rear Gear Engaged" 1 "Rear Gear not Engaged" 0 "Not used";
VAL_ 1107 EngineHoodState 3 "Not used" 2 "Hood closed" 1 "Hood opened" 0 "Unvailable value";
VAL_ 1107 EEM_StaticPowerLimitationRequest 7 "Not used" 6 "Not used" 5 "Not used" 4 "Producer failure power limitation" 3 "Battery Disconnection power limitation" 2 "Delivery Mode power limitation" 1 "Life on Board Low SOC power limitation" 0 "No Request";
VAL_ 1108 HandDrivingActivationState 1 "Left Hand Driving activated" 0 "Right Hand Driving activated";
VAL_ 1108 LowBatteryVoltageDisplay 3 "Battery in charge" 2 "Battery weak : start engine" 1 "Battery weak" 0 "No display request";
VAL_ 1108 AFS_ActivationState 1 "AFS deactivated" 0 "AFS activated";
VAL_ 1109 HDC_StatusDisplay 3 "HDC Failure" 2 "HDC in Control" 1 "HDC Activated" 0 "HDC Not activated";
VAL_ 1109 BrakingSystemStateDisplayRequest 1 "Failure" 0 "No failure";
VAL_ 1109 AccurateOdometer 0 "00h to 1Eh (available till 31km/h)";
VAL_ 1109 VehicleSpeedSign 3 "Unavailable" 2 "Negative vehicle speed (= reverse motion)" 1 "Positive vehicle speed (= Forward motion)" 0 "nul vehicle speed";
VAL_ 1109 EBDstateDisplayRequest 1 "Failure " 0 "No failure";
VAL_ 1109 ABSstateDisplayRequest 3 "To be calibrated" 2 "In ext diag session" 1 "Failure" 0 "No failure";
VAL_ 1109 VDCstateDisplayRequest 3 "Not used" 2 "In active control" 1 "Failure" 0 "No failure and no control";
VAL_ 1109 TPW_AcknowledgeResetDriver 3 "TPW not activ" 2 "Reset ack " 1 "Reset fail " 0 "Waiting ";
VAL_ 1109 VDCdeactivationDisplayRequest 1 "VDC deactivated display request" 0 "No request";
VAL_ 1109 TPW_TireCheckReminder 1 "Tire check reminder" 0 "No tire check reminder";
VAL_ 1109 TPW_Status 3 "TPW not operational" 2 "Failure" 1 "Tyre under inflated" 0 "System OK";
VAL_ 1116 ASAactivationState 1 "Deactivated" 0 "Activated";
VAL_ 1116 ADA1ActivationState 1 "Deactivated" 0 "Activated";
VAL_ 1135 AVM_UserAcknowledgement 3 "Not Used" 2 "User acknowledgement2" 1 "User acknowledgement1" 0 "No user acknowledgement";
VAL_ 1135 APA_UserAcknowledgement 3 "Not Used" 2 "User acknowledgement2" 1 "User acknowledgement1" 0 "No user acknowledgement";
VAL_ 1135 WelcomeFunctionAvailability 3 "Video and sound available" 2 "Video available" 1 "Sound available" 0 "Not ready";
VAL_ 1136 EngineControlFailureLevel2 1 "Engine Control Failure Level 2 create by stoping the engine" 0 "no Engine Control Failure Level 2 create by stoping the engine";
VAL_ 1136 EngineControlFailureLevel1 1 "Engine Control Failure Level 1" 0 "no Engine Control Failure Level 1";
VAL_ 1137 ShiftIndicator 3 "No Shift change display Request (by freeshift function" 2 "DownShift display request " 1 "UpShift display resques" 0 "No display request (no freeshift function or not equipped)";
VAL_ 1137 RequestedSpeedDisplayRequest 255 "CC/SL failure" 254 "CC/SL off or awaiting for a speed selection";
VAL_ 1137 EcoPedalMenuRequest 1 "Menu ON  " 0 "Menu OFF";
VAL_ 1137 EcoPedalForceSettingStatus 3 "ECO Pedal Force setting status Standard" 2 "ECO Pedal Force setting status Soft" 1 "ECO Pedal Force setting status OFF" 0 "No request";
VAL_ 1137 CruiseControlStatus 7 "Vehicle not equipped with CC/SL" 6 "CC requested and in failure" 5 "CC ON and ( awaiting  or suspended)" 4 "CC active" 3 "SL requested and in failure" 2 "SL on and (awaiting or suspended)" 1 "SL active" 0 "Cruise Control (CC) and Speed Limit (SL) OFF";
VAL_ 1137 FreeKmCalculationAuthorization 1 "Free Km calculation ON" 0 "Free Km calculation OFF";
VAL_ 1138 SailingActivationIdleStatus 1 "Activated" 0 "Deactivated";
VAL_ 1138 PredictiveShiftActivationState 3 "Not used" 2 "Deactivated" 1 "Activated" 0 "Unavailable";
VAL_ 1138 SailingStopActivationState 1 "Deactivated" 0 "Activated";
VAL_ 1138 CruiseEcoActivationState 3 "Not used" 2 "ECO deactivated" 1 "ECO activated" 0 "Unavailable";
VAL_ 1140 LKA_AlertStatus 3 "Not used" 2 "Left alert" 1 "Right alert" 0 "No alert";
VAL_ 1140 LKA_ActivationState 3 "Not used" 2 "Deactivated" 1 "Activated" 0 "Unavailable";
VAL_ 1140 LKA_SWheelTakeOverAlert_v3 7 "Not used" 6 "Not used" 5 "Alert Lvl 5" 4 "Alert Lvl 4" 3 "Alert Lvl 3" 2 "Alert Lvl 2" 1 "Alert Lvl 1" 0 "No Alert";
VAL_ 1143 RearRightDoorState 3 "Not Used" 2 "Rear Right door open" 1 "Rear Right door closed" 0 "Unvailable Value";
VAL_ 1143 DriverSeatBeltFailureState 3 "Not used" 2 "Driver Seat Belt OK" 1 "Supposed Driver Seat Belt Failure" 0 "No Monitoring";
VAL_ 1143 V_WakeUpType 7 "Unavailable" 6 "Selective Wake-Up Mode 6" 5 "Selective Wake-Up Mode 5" 4 "Selective Wake-Up Mode 4" 3 "Selective Wake-Up Mode 3" 2 "Selective Wake-Up Mode 2" 1 "Selective Wake-Up Mode 1" 0 "Full Wake-Up Mode";
VAL_ 1143 V_WakeUpSleepCommand 3 "WakeUp" 2 "reserved" 1 "reserved" 0 "Go to Sleep";
VAL_ 1143 RearFogLightStateDisplay 1 "rear fog light ON" 0 "rear fog light OFF";
VAL_ 1143 DriverDoorState 3 "Not Used" 2 "Driver door open" 1 "Driver door closed" 0 "Unavailable Value";
VAL_ 1143 PassengerDoorState 3 "Not used" 2 "Passenger door open" 1 "Passenger door closed" 0 "Unavailable Value";
VAL_ 1143 RearLeftDoorState 3 "Not Used" 2 "Rear left door open" 1 "Rear left door closed" 0 "Unavailable Value";
VAL_ 1144 DriveModeStatusDisplay 7 "Not used" 6 "Not used" 5 "Not used" 4 " Race mode displayed (ESC off) for RST" 3 "Sport mode displayed" 2 "Eco mode displayed" 1 "Normal mode displayed" 0 "No display Request";
VAL_ 1144 WarningLightsStatus 1 "Warning Lights ON" 0 "Warning Lights OFF";
VAL_ 1144 VehicleOutsideLockedState 1 "Vehicle Locked from the outside by the customer" 0 "Vehicle not locked from the outside by the customer";
VAL_ 1144 FrontFogLightsDisplay 1 "front fog lights display requested" 0 "front fog lights display not requested";
VAL_ 1144 BrakeLampStatus 1 "Brake Lamp On" 0 "Brake Lamp Off";
VAL_ 1145 SingleDoorOpeningActivationState 1 "Single door opening deactivated" 0 "Single door opening activated";
VAL_ 1145 DriverModeUpSwitchState 1 "Pushed" 0 "Not Pushed";
VAL_ 1145 SRU_Position 15 "Window position 7" 14 "Window sector 67" 13 "Window position 6" 12 "Window sector 56" 11 "Window position 5" 10 "Window sector 45" 9 "Window position 4" 8 "Window sector 34" 7 "Window position 3" 6 "Window sector 23" 5 "Window position 2" 4 "Window sector 12" 3 "Window position 1" 2 "Window sector 01" 1 "Window position 0 (closed)" 0 "Window position invalid";
VAL_ 1145 WindowPosition_FR 7 "Window fully open (HW block position)" 6 "Window fully open (SW block position)" 5 "Window in intermediate position (default or lower than RCU position)" 4 "Window RCU Drop position" 3 "Window in intermediate position (upper than RCU position)" 2 "Window Short Drop position" 1 "Window fully closed (HW or SW block position)" 0 "Window position invalid";
VAL_ 1145 WindowPosition_FL 7 "Window fully open (HW block position)" 6 "Window fully open (SW block position)" 5 "Window in intermediate position (default or lower than RCU position)" 4 "Window RCU Drop position" 3 "Window in intermediate position (upper than RCU position)" 2 "Window Short Drop position" 1 "Window fully closed (HW or SW block position)" 0 "Window position invalid";
VAL_ 1145 ProbableCustomerFeedBackNeed 1 "Customer feedback needed" 0 "Customer feedback probably not needed";
VAL_ 1145 WindowPosition_RR 7 "Window fully open (HW block position)" 6 "Window fully open (SW block position)" 5 "Window in intermediate position (default or lower than RCU position)" 4 "Window RCU Drop position" 3 "Window in intermediate position (upper than RCU position)" 2 "Window Short Drop position" 1 "Window fully closed (HW or SW block position)" 0 "Window position invalid";
VAL_ 1145 WindowPosition_RL 7 "Window fully open (HW block position)" 6 "Window fully open (SW block position)" 5 "Window in intermediate position (default or lower than RCU position)" 4 "Window RCU Drop position" 3 "Window in intermediate position (upper than RCU position)" 2 "Window Short Drop position" 1 "Window fully closed (HW or SW block position)" 0 "Window position invalid";
VAL_ 1145 DayNightSynthesis 3 "Not used" 2 "Night" 1 "Twilight" 0 "Day";
VAL_ 1145 AutoFoldingActivationState 3 "Unlock + IGN Unfold" 2 "IGN Unfold" 1 "Disable" 0 "Unavailable";
VAL_ 1145 AutoACC2Status_MM 3 "Multimedia can work for all functions" 2 "Multimedia can detect manual operation" 1 "Multimedia can receive / send messages" 0 "Multimedia is done";
VAL_ 1145 MexSwitchState 1 "Pushed" 0 "Not Pushed";
VAL_ 1146 DriverSafetyBeltBuckleState 3 "Unavailable" 2 "SB fastened" 1 "SB unfastened" 0 "SB Not monitored";
VAL_ 1146 ClutchSwitchMinimumTravel 3 "Unavailable" 2 "Clutch pedal pressed at minimum" 1 "Clutch pedal not pressed                               " 0 "Not used";
VAL_ 1146 TailGateStatus 3 "Not Used  " 2 "TailGate is open" 1 "TailGate is closed" 0 "Unvailable Value";
VAL_ 1146 VehicleStates 15 "Unavailable" 14 "Not used" 13 "Not used" 12 "Not used" 11 "Not used" 10 "Not used" 9 "EngineSystemStop" 8 "AutoStart" 7 "PowertrainRunning" 6 "StartingInProgress" 5 "IgnitionLevel" 4 "Not used" 3 "AutoACC  - BatTempoLevel" 2 "CutoffPending" 1 "Not used" 0 "Sleeping";
VAL_ 1146 BrakeInfoStatus 7 "unavailable" 6 "Not used" 5 "Not used" 4 "Brake pedal confirmed pressed" 3 "Not used" 2 "Brake pedal pressed" 1 "Brake pedal not pressed" 0 "Not used";
VAL_ 1146 DeliveryModeInformation_v2 3 "Not used" 2 "delivery mode level 2" 1 "delivery mode level 1" 0 "customer mode";
VAL_ 1146 DriveModeRequest 7 "Unavailable" 6 "Not used" 5 "Not used" 4 "Not used" 3 "Race mode requested (ESC off) for RST" 2 "Sport mode requested" 1 "Eco mode requested" 0 "Normal mode requested";
VAL_ 1146 FlashingIndicatorStatus 7 "Unavailable" 6 "Not used" 5 "Not used" 4 "Not used" 3 "left flashing indicator ON and right flashing indicator ON" 2 "left flashing indicator OFF and right flashing indicator ON" 1 "left flashing indicator ON and right flashing indicator OFF" 0 "left and right flashing indicators OFF";
VAL_ 1146 GADE_v2 7 "Unavailable" 6 "Not used" 5 "Not used" 4 "FOTA switch fault, Disable DiagMuxDTC" 3 "ALL fault, Enable DiagMuxDTC" 2 "ALL fault, Disable DiagMuxDTC" 1 "AutoACC fault, Disable DiagMuxDTC" 0 "Sleep or Crank fault, Disable DiagMuxDTC";
VAL_ 1146 FrontWiperStatus_BCM 3 "Unavailable" 2 "high speed active" 1 "low speed active" 0 "front wiper stopped";
VAL_ 1146 TrailerPresence 1 "trailer detected" 0 "no trailer detected";
VAL_ 1146 FrontWipingRequest 7 "high speed wiping requested" 6 "low speed wiping requested" 5 "Not used" 4 "unavailable" 3 "Not used" 2 "Not used" 1 "front wiper forced to stop" 0 "front wiper in stop position";
VAL_ 1146 LightSensorStatus 1 "Night time according to light level sensor" 0 "Day time according light level sensor ";
VAL_ 1146 RainStatus 3 "unavailable" 2 "not used" 1 "rain" 0 "no rain";
VAL_ 1146 ClutchSwitchMaximumTravel 3 "Unavailable" 2 "Clutch pedal pressed at maximum" 1 "Clutch pedal not pressed at maximum                             " 0 "Not used";
VAL_ 1147 OilPressureWarning_ECM 1 "Oil Pressure Warning" 0 "No Oil Pressure Warning";
VAL_ 1147 WarningWaterTemp 1 "water temperature warning" 0 "no water temperature warning";
VAL_ 1150 SET_PositionInLane_State 3 "To_overtake_lane" 2 "Centre" 1 "To_hard_shoulder" 0 "Invalid";
VAL_ 1150 SET_VoiceGuidance_State 3 "Not Used" 2 "ON" 1 "OFF" 0 "Invalid";
VAL_ 1150 SET_LaneChangeSwiftness_State 3 "Comfort" 2 "Standard" 1 "Swift" 0 "Invalid";
VAL_ 1150 SET_NavigatDriveAssist_State 3 "Not Used" 2 "ON" 1 "OFF" 0 "Invalid";
VAL_ 1150 SET_OvertakeRelatSpeed_State 3 "High" 2 "Middle" 1 "Low" 0 "Invalid";
VAL_ 1150 SET_OvertakingAssist_State 3 "Not Used" 2 "ON" 1 "OFF" 0 "Invalid";
VAL_ 1150 SET_Acceleration_State 3 "Gentle" 2 "Standard" 1 "Quick" 0 "Invalid";
VAL_ 1150 SET_ALCActivationByTSIG_State 3 "Not Used" 2 "ON" 1 "OFF" 0 "Invalid";
VAL_ 1150 SET_CornerSpeedLevel_State 3 "Gentle" 2 "Standard" 1 "Quick" 0 "Invalid";
VAL_ 1150 SET_Deceleration_State 3 "Gentle" 2 "Standard" 1 "Quick" 0 "Invalid";
VAL_ 1150 ADL3_DisclaimerRepetitionRequest 1 "Repetition request" 0 "No repetition request";
VAL_ 1150 SET_ADL3Activation_State 3 "Not Used" 2 "Deactivated" 1 "Activated" 0 "Invalid";
VAL_ 1150 SET_AD_HandsOff_State 3 "Not Used" 2 "Deactivated" 1 "Activated" 0 "Invalid";
VAL_ 1150 SET_ALC_AssistMode_State 3 "Not Used" 2 "Individual" 1 "Successive" 0 "Invalid";
VAL_ 1172 EcoNavRechargeDuringTrip 7 "Not used" 6 "Not used" 5 "Not used" 4 "No Recharge at Station" 3 "Recharge at Station" 2 "No recharge while driving" 1 "Recharge while driving" 0 "No Status";
VAL_ 1172 RST_GearShiftBuzzerActivRequest 3 "Reset request" 2 "Beep deactivation request" 1 "Beep activation request" 0 "No request";
VAL_ 1172 SC_SmartchargingActivationStatus 3 "Unavailable" 2 "Smart Charging  activated" 1 "Smart Charging Not activated" 0 "No value";
VAL_ 1172 SC_PresoakActivationStatus 3 "Unavailable" 2 "Presoak activated" 1 "Presoak Not activated" 0 "No value";
VAL_ 1202 MemoParkStatusDisplayRequest 0 "No display";
VAL_ 1202 TrailerGuidelineActivationState 1 "Deactivated" 0 "Activated";
VAL_ 1202 FAPK_ManeuverType_ParkOut 3 "Unavailable" 2 "Not Used" 1 "Selected" 0 "Not selected";
VAL_ 1202 FAPK_ManeuverType_Parallel 3 "Unavailable" 2 "Not Used" 1 "Selected" 0 "Not selected";
VAL_ 1202 FAPK_ManeuverType_AutoMode 3 "Unavailable" 2 "Not Used" 1 "Selected" 0 "Not selected";
VAL_ 1202 FAPK_ManeuverType_Angular 3 "Unavailable" 2 "Not Used" 1 "Selected" 0 "Not selected";
VAL_ 1202 FAPK_ManeuverType_Perpendicular 3 "Unavailable" 2 "Not Used" 1 "Selected" 0 "Not selected";
VAL_ 1276 BCI_ActivationState 1 "Deactivated" 0 "Activated";
VAL_ 1276 ACC_Status_Slow 15 "Unavailable" 14 "Not used" 13 "Not used" 12 "Not used" 11 "Not used" 10 "Not used" 9 "Not used" 8 "ACC in failure State" 7 "ACC driver override" 6 "ACC regulation" 5 "ACC in brake only mode" 4 "ACC suspended" 3 "ACC waiting" 2 "ACC in stop" 1 "ACC in take off" 0 "ACC OFF";
VAL_ 1282 SonarSystemPauseStatus 1 "System Pause On" 0 "System Pause Off";
VAL_ 1282 ParkAssistSensitivityStatus 3 "Near Range Detection" 2 "Middle Range Detection " 1 "Far Range Detection" 0 "Unavailable";
VAL_ 1282 FrontParkAssistState 1 "Front park assistance activated" 0 "Front park assistance de-activated";
VAL_ 1282 RearParkAssistState 1 "Rear park assistance activated" 0 "Rear park assistance de-activated";
VAL_ 1282 SonarAutoDisplayState 3 "Not used" 2 "Auto Display Deactivation" 1 "Auto Display Activation" 0 "Unavailable";
VAL_ 1292 RST_TrackSettings 1 "Requested" 0 "Not Requested";
VAL_ 1292 BrakePedalLevelRequest 7 "Unavailable" 6 "Not Used" 5 "Not Used" 4 "Not Used" 3 "Pedal tuning 3" 2 "Pedal tuning 2" 1 "Pedal tuning 1" 0 "No request";
VAL_ 1294 VirtualKeyMenuState 3 "Not Used" 2 "Deactivate Menu" 1 "Activate Menu" 0 "Display Menu";
VAL_ 1295 SET_ALCP2P_AlertLevel_Request2 7 "Not used" 6 "Not used" 5 "Not used" 4 "Reset request" 3 "Lv3" 2 "Lv2" 1 "Lv1" 0 "No request";
VAL_ 1295 HVbatteryCoolingActivationReq2 3 "Reset to factory value" 2 "Battery cooling desactivation Request" 1 "Battery cooling activation Request" 0 "No request";
VAL_ 1295 SET_AD_HandsOff_Request2 3 "Reset request" 2 "Deactivation" 1 "Activation" 0 "No request";
VAL_ 1295 SET_ALC_AssistMode_Request2 3 "Reset request" 2 "Individual" 1 "Successive" 0 "No request";
VAL_ 1295 V2G_ServiceActivationRequest 3 "Reset request" 2 "V2G activated" 1 "V2G not activated" 0 "No request";
VAL_ 1295 SET_ADL3Activation_Request2 3 "Reset Request" 2 "Deactivation" 1 "Activation" 0 "No request";
VAL_ 1296 IVI_SafeMode 1 "Activated" 0 "Not activated";
VAL_ 1296 IVI_SafeModePersistentON 1 "Persistent mode enabled" 0 "Persistent mode disabled";
VAL_ 1296 IVI_SafeModeRebootReason 7 "Display message 7" 6 "Display message 6" 5 "Display message 5" 4 "Display message 4" 3 "Display message 3" 2 "Display message 2" 1 "Display message 1" 0 "No message to user";
VAL_ 1299 FKP_ObstacleZone_RF 3 "Detect level 3" 2 "Detect level 2" 1 "Detect level 1" 0 "No detection";
VAL_ 1299 FKP_ObstacleZone_LRC 3 "Detect level 3" 2 "Detect level 2" 1 "Detect level 1" 0 "No detection";
VAL_ 1299 FKP_ObstacleZone_LFC 3 "Detect level 3" 2 "Detect level 2" 1 "Detect level 1" 0 "No detection";
VAL_ 1299 FKP_ObstacleZone_LF 3 "Detect level 3" 2 "Detect level 2" 1 "Detect level 1" 0 "No detection";
VAL_ 1299 FKP_ObstacleZone_RRC 3 "Detect level 3" 2 "Detect level 2" 1 "Detect level 1" 0 "No detection";
VAL_ 1299 FKP_ObstacleZone_RR 3 "Detect level 3" 2 "Detect level 2" 1 "Detect level 1" 0 "No detection";
VAL_ 1299 FKP_ObstacleZone_RL 3 "Detect level 3" 2 "Detect level 2" 1 "Detect level 1" 0 "No detection";
VAL_ 1299 FKP_ObstacleZone_RFC 3 "Detect level 3" 2 "Detect level 2" 1 "Detect level 1" 0 "No detection";
VAL_ 1299 FKP_FrontMiddleL_Scan 1 "Area Scanned" 0 "Area Not Scanned";
VAL_ 1299 FKP_FrontMiddleR_Hatch 1 "Area Hatched" 0 "Area Not Hatched";
VAL_ 1299 FKP_FrontMiddleL_Hatch 1 "Area Hatched" 0 "Area Not Hatched";
VAL_ 1299 FKP_FrontFrontR_Scan 1 "Area Scanned" 0 "Area Not Scanned";
VAL_ 1299 FKP_FrontFrontR_Hatch 1 "Area Hatched" 0 "Area Not Hatched";
VAL_ 1299 FKP_FrontFrontL_Scan 1 "Area Scanned" 0 "Area Not Scanned";
VAL_ 1299 FKP_ImageDisplayRequest 1 "Display requested" 0 "Display NOT requested";
VAL_ 1299 FKP_FrontMiddleR_Scan 1 "Area Scanned" 0 "Area Not Scanned";
VAL_ 1299 FKP_RearRearR_Scan 1 "Area Scanned" 0 "Area Not Scanned";
VAL_ 1299 FKP_RearRearR_Hatch 1 "Area Hatched" 0 "Area Not Hatched";
VAL_ 1299 FKP_RearRearL_Scan 1 "Area Scanned" 0 "Area Not Scanned";
VAL_ 1299 FKP_RearRearL_Hatch 1 "Area Hatched" 0 "Area Not Hatched";
VAL_ 1299 FKP_RearMiddleR_Scan 1 "Area Scanned" 0 "Area Not Scanned";
VAL_ 1299 FKP_RearMiddleR_Hatch 1 "Area Hatched" 0 "Area Not Hatched";
VAL_ 1299 FKP_RearMiddleL_Scan 1 "Area Scanned" 0 "Area Not Scanned";
VAL_ 1299 FKP_RearMiddleL_Hatch 1 "Area Hatched" 0 "Area Not Hatched";
VAL_ 1299 FKP_FrontFrontL_Hatch 1 "Area Hatched" 0 "Area Not Hatched";
VAL_ 1299 UPA_RearRight_Hatch 1 "Area Hatched" 0 "Area Not Hatched";
VAL_ 1299 UPA_RearMiddle_Hatch 1 "Area Hatched" 0 "Area Not Hatched";
VAL_ 1299 UPA_RearLeft_Hatch 1 "Area Hatched" 0 "Area Not Hatched";
VAL_ 1299 UPA_FrontRight_Hatch 1 "Area Hatched" 0 "Area Not Hatched";
VAL_ 1299 UPA_FrontMiddle_Hatch 1 "Area Hatched" 0 "Area Not Hatched";
VAL_ 1299 UPA_FrontLeft_Hatch 1 "Area Hatched" 0 "Area Not Hatched";
VAL_ 1299 FKP_ActivationStatus 1 "Flank Protection activated" 0 "Flank Protection NOT activated";
VAL_ 1303 RainSymbolDisplayRequest 1 "Rain Symbol Display Request" 0 "No Rain Symbol Display Request";
VAL_ 1303 TSR_OSP_SpeedSignalZone1 255 "No Speed available show ---" 254 "Free speed' Symbol";
VAL_ 1303 TSR_OSP_ActivationStatus 3 "Not used" 2 "TSR/OSP Not Activated" 1 "TSR/OSP Activated" 0 "Unavailable";
VAL_ 1303 OSPOverSpeedDisplayRequest 1 "OverSpeedAlert" 0 "No Overspeed alert";
VAL_ 1310 CartoData 0 "Table Value16337";
VAL_ 1310 OSPDataType 7 "Reserved" 6 "META-DATA" 5 "PROFILE LONG" 4 "PROFILE SHORT" 3 "STUB" 2 "SEGMENT" 1 "POSITION" 0 "Reserved";
VAL_ 1318 TripComputer_ResetRequest 1 "Reset OnBoardComputer requested" 0 "Reset OnBoardComputer not requested";
VAL_ 1318 LDW_SoundLevelState_v2 7 "Not Used" 6 "Not Used" 5 "Level 5" 4 "Level 4" 3 "Level 3" 2 "Level 2" 1 "Level 1" 0 "Not used";
VAL_ 1318 RESPreSoak_ProgReq_MMI 3 "Not used" 2 "Start Timer Request - every two hours (5 times max)" 1 "Start Timer Request - one time (RES or Presoak)" 0 "No Timer";
VAL_ 1318 ESE_Soundvolume_Request 31 "Reset request" 30 "Not used" 29 "Not used" 28 "Not used" 27 "Not used" 26 "Not used" 25 "Not used" 24 "Not used" 23 "Not used" 22 "Not used" 21 "Not used" 20 "Not used" 19 "Not used" 18 "Not used" 17 "14" 16 "13" 15 "12" 14 "11" 13 "10" 12 "9" 11 "8" 10 "7" 9 "6" 8 "5" 7 "4" 6 "3" 5 "2" 4 "1" 3 "High" 2 "Low" 1 "0" 0 "No request";
VAL_ 1318 HFP_SelectedManeuverTypeRequest 7 "Not used" 6 "Not used" 5 "Not used" 4 "park out" 3 "park in / angled" 2 "park in / perpendicular" 1 "park in / parallel" 0 "no request";
VAL_ 1318 ESE_Soundtype_Request 15 "Reset Request" 14 "Not used" 13 "Not used" 12 "Not used" 11 "Not used" 10 "Not used" 9 "RSound6" 8 "RSound5" 7 "RSound4" 6 "RSound3" 5 "RSound2" 4 "RSound1" 3 "Sound2" 2 "Sound 1" 1 "Neutral" 0 "No Request";
VAL_ 1320 NAVI_Matching_RoutePlan 1 "Matching" 0 "Not Matching";
VAL_ 1325 NAVI_BranchMultipleInfo 1 "Multiple branch" 0 "No branch or Single branch";
VAL_ 1325 NAVI_BranchDirection 3 "Not Used" 2 "Right Branch" 1 "Left Branch" 0 "No Branch";
VAL_ 1325 NaviGPS_PositioningStatus 1 "not Normal" 0 "Normal";
VAL_ 1325 NAVI_Matching_Status 1 "matching" 0 "Not matching";
VAL_ 1325 NAVI_MatchingReset 1 "Reset" 0 "Not reset";
VAL_ 1325 NAVI_LinkFailure 1 "Existing Link failure" 0 "Not existing Link failure";
VAL_ 1325 NAVI_TurningStatus 1 "Turning" 0 "Not Turning";
VAL_ 1325 NAVI_CurvatureError 1 "Error" 0 "No error";
VAL_ 1325 InGuidingRoute 1 "in the guiding route" 0 "not in the guiding route";
VAL_ 1325 Current_Roadtype 7 "other" 6 "general road" 5 "principal prefectural road" 4 "prefectural road" 3 "national road" 2 "toll road" 1 "urban expressway" 0 "intercity expressway";
VAL_ 1325 RouteGuiding_flag 1 "ON" 0 "OFF";
VAL_ 1325 Current_Linktype 7 "other" 6 "Rotary link" 5 "Lateral line for SA" 4 "Side road same line as mainroad" 3 "Junction link 2" 2 "Junction link 1" 1 "Up-down separable link" 0 "Up-down inseparable link";
VAL_ 1332 AIRBAGMalfunction 1 "AIRBAG system malfunction" 0 "no AIRBAG system malfunction";
VAL_ 1332 PassengerSafetyBeltBuckleState 3 "Unavailable" 2 "SB fastened " 1 "SB unfastened" 0 "SB Not monitored ";
VAL_ 1332 PassengerPresenceState 3 "Unknown" 2 "Absent" 1 "Present" 0 "Not monitored";
VAL_ 1332 SecondRowLeftSafetyBeltState 3 "Unavailable" 2 "SB fastened" 1 "SB unfastened" 0 "SB not monitored";
VAL_ 1332 SecondRowCenterSafetyBeltState 3 "Unavailable" 2 "SB fastened" 1 "SB unfastened" 0 "SB not monitored";
VAL_ 1332 ThirdRowCenterSafetyBeltState 3 "Unavailable" 2 "SB fastened" 1 "SB unfastened" 0 "SB not monitored";
VAL_ 1332 SecondRowRightSafetyBeltState 3 "Unavailable" 2 "SB fastened" 1 "SB unfastened" 0 "SB not monitored";
VAL_ 1332 ThirdRowRightSafetyBeltState 3 "Unavailable" 2 "SB fastened" 1 "SB unfastened" 0 "SB not monitored";
VAL_ 1332 ThirdRowLeftSafetyBeltState 3 "Unavailable" 2 "SB fastened" 1 "SB unfastened" 0 "SB not monitored";
VAL_ 1332 FirstRowCenterSafetyBeltState 3 "Unavailable" 2 "SB fastened" 1 "SB unfastened" 0 "SB Not monitored";
VAL_ 1334 RouteID 7 "Route 7" 6 "Route 6" 5 "Route 5" 4 "Route 4" 3 "Route 3" 2 "Route 2" 1 "Route 1" 0 "No route available";
VAL_ 1334 RouteStatus 7 "Not used" 6 "Not used" 5 "Driver Stopped Following the Route" 4 "GPS Signal Lost" 3 "Route Available From Estimation" 2 "Route Available From User Input" 1 "Route under calculation" 0 "Not Available";
VAL_ 1334 UrbanZevDrivingOption 1 "ZEV urban mode preference" 0 "No ZEV urban mode preference";
VAL_ 1335 SegmentRoadType 7 "Unavailable" 6 "Other/unknown" 5 "Service" 4 "Residential" 3 "Urban" 2 "Rural" 1 "Freeway" 0 "Highway";
VAL_ 1335 SegmentInMandatoryZEVzone 1 "Segment In Mandatory ZEV Zone" 0 "No restrictions";
VAL_ 1339 TimeWeekDay 7 "Unavailable" 6 "Sunday" 5 "Saturday" 4 "Friday" 3 "Thursday" 2 "Wednesday" 1 "Tuesday" 0 "Monday";
VAL_ 1341 UPA_SoundRecurrenceType 1 "Continuous sound" 0 "Discontinuous sound";
VAL_ 1341 UPA_SystemState 3 "Error Mode" 2 "Standby Mode " 1 "Normal Mode" 0 "Manoeuvring Mode";
VAL_ 1341 UPA_Obstacle_Zone_Front_Right 7 "Unavailable" 6 "Reserve" 5 "Detect level 5" 4 "Detect level 4 (30~cm)" 3 "Detect level 3 (50~30cm)" 2 "Detect level 2 (70~50cm)" 1 "Reserve" 0 "No detection";
VAL_ 1341 UPA_Obstacle_Zone_Front_Left 7 "Unavailable" 6 "Reserve" 5 "Detect level 5" 4 "Detect level 4 (30~cm)" 3 "Detect level 3 (50~30cm)" 2 "Detect level 2 (70~50cm)" 1 "Reserve" 0 "No detection";
VAL_ 1341 UPA_Image_DisplayRequest 3 "Front and Rear Detection ON" 2 "Front Detection ON" 1 "Rear Detection ON" 0 "No display request";
VAL_ 1341 UPA_Obstacle_Zone_Rear_Right 7 "Unavailable" 6 "Reserve" 5 "Detect level 5" 4 "Detect level 4 (30~cm)" 3 "Detect level 3 (50~30cm)" 2 "Detect level 2 (70~50cm)" 1 "Detect level 1 (~70cm)" 0 "No detection";
VAL_ 1341 UPA_Obstacle_Zone_Rear_Left 7 "Unavailable" 6 "Reserve" 5 "Detect level 5" 4 "Detect level 4 (30~cm)" 3 "Detect level 3 (50~30cm)" 2 "Detect level 2 (70~50cm)" 1 "Detect level 1 (~70cm)" 0 "No detection";
VAL_ 1341 UPA_SoundActivationBeep 1 "Request" 0 "No Request";
VAL_ 1341 UPA_SoundErrorBeep 1 "Error sound" 0 "No error sound";
VAL_ 1341 UPA_Obstacle_Zone_Rear_Center 7 "Unavailable" 6 "Reserve" 5 "Detect level 5" 4 "Detect level 4 (30~cm)" 3 "Detect level 3 (50~30cm)" 2 "Detect level 2 (70~50cm)" 1 "Detect level 1 (   ~70cm)" 0 "No detection";
VAL_ 1341 UPA_Obstacle_Zone_Front_Center 7 "Unavailable" 6 "Reserve" 5 "Detect level 5" 4 "Detect level 4 (30~cm)" 3 "Detect level 3 (50~30cm)" 2 "Detect level 2 (70~50cm)" 1 "Detect level 1 (   ~70cm)" 0 "No detection";
VAL_ 1341 SensorAvailabilityFrontLeft 1 "Sensor available" 0 "Sensor not available";
VAL_ 1341 SensorAvailabilityFrontCenter 1 "Sensor available" 0 "Sensor not available";
VAL_ 1341 UPA_SoundObstacleZone 7 "reserved" 6 "Sound rear right " 5 "Sound rear center" 4 "Sound rear left " 3 "Sound front right " 2 "Sound front center " 1 "Sound front left " 0 "No Sound";
VAL_ 1341 UPAStatusDisplayRequest 7 "System Error" 6 "Rear and front UPA activated" 5 "Not used" 4 "Rear UPA activated and front UPA de-activated" 3 "Not used" 2 "Rear UPA de-activated and front UPA activated" 1 "Rear and front UPA de-activated" 0 "no upa status display request";
VAL_ 1341 SensorAvailabilityFrontRight 1 "Sensor available" 0 "Sensor not available";
VAL_ 1341 SonarObstacleDistanceDisplay 15 "Reserved" 14 "Reserved" 13 "Reserved" 12 "Distance 12" 11 "Distance 11" 10 "Distance 10" 9 "Distance 9" 8 "Distance 8" 7 "Distance 7" 6 "Distance 6" 5 "Distance 5" 4 "Distance 4" 3 "Distance 3" 2 "Distance 2" 1 "Distance 1" 0 "No detect / No display";
VAL_ 1341 ParkAssistVolumeState 7 "Not used" 6 "Not used" 5 "Level 5" 4 "Level 4" 3 "Level 3" 2 "Level 2" 1 "Level 1" 0 "Level 0 (off)";
VAL_ 1341 SensorAvailabilityRearRight 1 "Sensor available" 0 "Sensor not available";
VAL_ 1341 SensorAvailabilityRearLeft 1 "Sensor available" 0 "Sensor not available";
VAL_ 1341 SensorAvailabilityRearCenter 1 "Sensor available" 0 "Sensor not available";
VAL_ 1341 UPA_ClosingAuthorization 1 "Authorized" 0 "Not authorized";
